VERSION ""

NS_ :

BS_:

BU_: SR_RR SR_RF SR_LR SR_LF DACU

BO_ 842 LFSideSensorObj10: 48 SR_LF
 SG_ LFSideSensorObj10_LatExtLeft : 276|7@1+ (0.05,0) [0|6.35] "m"  VCM
 SG_ LFSideSensorObj10_LatVel : 208|13@1+ (0.032,-80) [-80|182.112] "m_per_s"  VCM
 SG_ LFSideSensorObj10_LatPosVar : 88|8@1+ (0.1,0) [0|25.5] "NotApplicable"  VCM
 SG_ LFSideSensorObj10_LongAccVar : 72|8@1+ (0.1,0) [0|25.5] "NotApplicable"  VCM
 SG_ LFSideSensorObj10_LongPos : 234|13@1+ (0.05,-180) [-180|229.55] "m"  VCM
 SG_ LFSideSensorObj10_ObstacleConf : 300|7@1+ (0.01,0) [0|1.27] "NotApplicable"  VCM
 SG_ LFSideSensorObj10_LatExtRtVar : 96|8@1+ (0.1,0) [0|25.5] "NotApplicable"  VCM
 SG_ LFSideSensorObj10_Prioritisation : 290|2@1+ (1,0) [0|0] ""  VCM
 SG_ LFSideSensorObj10_HeadingVar : 120|8@1+ (0.001,0) [0|0.255] "NotApplicable"  VCM
 SG_ LFSideSensorObj10_ExistConf : 283|7@1+ (0.01,0) [0|1.27] "NotApplicable"  VCM
 SG_ LFSideSensorObj10_Counter : 16|8@1+ (1,0) [0|255] "Count"  VCM
 SG_ LFSideSensorObj10_ObjDynClass : 166|2@1+ (1,0) [0|0] ""  VCM
 SG_ LFSideSensorObj10_LatAcc : 267|9@1+ (0.08,-20) [-20|20.88] "m_per_s_squared"  VCM
 SG_ LFSideSensorObj10_TrackStatus : 192|3@1+ (1,0) [0|0] ""  VCM
 SG_ LFSideSensorObj10_CoastIndex : 155|5@1+ (1,0) [0|31] "NotApplicable"  VCM
 SG_ LFSideSensorObj10_LongVelVar : 40|8@1+ (0.01,0) [0|2.55] "NotApplicable"  VCM
 SG_ LFSideSensorObj10_LongExtFrVar : 56|8@1+ (0.1,0) [0|25.5] "NotApplicable"  VCM
 SG_ LFSideSensorObj10_LongExtFront : 247|10@1+ (0.05,0) [0|51.15] "m"  VCM
 SG_ LFSideSensorObj10_LatExtRight : 185|7@1+ (0.05,-5) [-5|1.35] "m"  VCM
 SG_ LFSideSensorObj10_MOISPrio : 307|1@1+ (1,0) [0|0] ""  VCM
 SG_ LFSideSensorObj10_LongAcc : 176|9@1+ (0.08,-20) [-20|20.88] "m_per_s_squared"  VCM
 SG_ LFSideSensorObj10_LongVel : 195|13@1+ (0.032,-80) [-80|182.112] "m_per_s"  VCM
 SG_ LFSideSensorObj10_LongExtBack : 257|10@1+ (0.05,-50) [-50|1.15000000000001] "m"  VCM
 SG_ LFSideSensorObj10_ObjClassConf : 296|4@1+ (0.1,0) [0|1.5] "NotApplicable"  VCM
 SG_ LFSideSensorObj10_LatVelVar : 80|8@1+ (0.01,0) [0|2.55] "NotApplicable"  VCM
 SG_ LFSideSensorObj10_TimeStamp : 24|16@1+ (0.1,0) [0|6553.5] "ms"  VCM
 SG_ LFSideSensorObj10_ObjID : 160|6@1+ (1,0) [0|63] "NotApplicable"  VCM
 SG_ LFSideSensorObj10_ObjClass : 292|4@1+ (1,0) [0|0] ""  VCM
 SG_ LFSideSensorObj10_LifeTime : 128|16@1+ (0.1,0) [0|6553.5] "s"  VCM
 SG_ LFSideSensorObj10_LongPosVar : 48|8@1+ (0.01,0) [0|2.55] "NotApplicable"  VCM
 SG_ LFSideSensorObj10_LongExtBkVar : 64|8@1+ (0.1,0) [0|25.5] "NotApplicable"  VCM
 SG_ LFSideSensorObj10_LatExtLeftVar : 104|8@1+ (0.1,0) [0|25.5] "NotApplicable"  VCM
 SG_ LFSideSensorObj10_Heading : 144|11@1+ (0.005818,-4.71) [-4.71|7.199446] "rad"  VCM
 SG_ LFSideSensorObj10_CRC : 0|16@1+ (1,0) [0|65535] "NotApplicable"  VCM
 SG_ LFSideSensorObj10_LatAccVar : 112|8@1+ (0.1,0) [0|25.5] "NotApplicable"  VCM
 SG_ LFSideSensorObj10_Height : 168|8@1+ (0.02,0) [0|5.1] "m"  VCM
 SG_ LFSideSensorObj10_LatPos : 221|13@1+ (0.05,-180) [-180|229.55] "m"  VCM

BO_ 841 LFSideSensorObj09: 48 SR_LF
 SG_ LFSideSensorObj09_Prioritisation : 290|2@1+ (1,0) [0|0] ""  VCM
 SG_ LFSideSensorObj09_TimeStamp : 24|16@1+ (0.1,0) [0|6553.5] "ms"  VCM
 SG_ LFSideSensorObj09_CoastIndex : 155|5@1+ (1,0) [0|31] "NotApplicable"  VCM
 SG_ LFSideSensorObj09_MOISPrio : 307|1@1+ (1,0) [0|0] ""  VCM
 SG_ LFSideSensorObj09_ExistConf : 283|7@1+ (0.01,0) [0|1.27] "NotApplicable"  VCM
 SG_ LFSideSensorObj09_Counter : 16|8@1+ (1,0) [0|255] "Count"  VCM
 SG_ LFSideSensorObj09_TrackStatus : 192|3@1+ (1,0) [0|0] ""  VCM
 SG_ LFSideSensorObj09_LongExtFront : 247|10@1+ (0.05,0) [0|51.15] "m"  VCM
 SG_ LFSideSensorObj09_LatPos : 221|13@1+ (0.05,-180) [-180|229.55] "m"  VCM
 SG_ LFSideSensorObj09_LongExtFrVar : 56|8@1+ (0.1,0) [0|25.5] "NotApplicable"  VCM
 SG_ LFSideSensorObj09_CRC : 0|16@1+ (1,0) [0|65535] "NotApplicable"  VCM
 SG_ LFSideSensorObj09_LongVelVar : 40|8@1+ (0.01,0) [0|2.55] "NotApplicable"  VCM
 SG_ LFSideSensorObj09_LongPosVar : 48|8@1+ (0.01,0) [0|2.55] "NotApplicable"  VCM
 SG_ LFSideSensorObj09_LongExtBkVar : 64|8@1+ (0.1,0) [0|25.5] "NotApplicable"  VCM
 SG_ LFSideSensorObj09_LongPos : 234|13@1+ (0.05,-180) [-180|229.55] "m"  VCM
 SG_ LFSideSensorObj09_LatVelVar : 80|8@1+ (0.01,0) [0|2.55] "NotApplicable"  VCM
 SG_ LFSideSensorObj09_LatExtRtVar : 96|8@1+ (0.1,0) [0|25.5] "NotApplicable"  VCM
 SG_ LFSideSensorObj09_ObjClassConf : 296|4@1+ (0.1,0) [0|1.5] "NotApplicable"  VCM
 SG_ LFSideSensorObj09_Height : 168|8@1+ (0.02,0) [0|5.1] "m"  VCM
 SG_ LFSideSensorObj09_LatVel : 208|13@1+ (0.032,-80) [-80|182.112] "m_per_s"  VCM
 SG_ LFSideSensorObj09_ObjDynClass : 166|2@1+ (1,0) [0|0] ""  VCM
 SG_ LFSideSensorObj09_LongExtBack : 257|10@1+ (0.05,-50) [-50|1.15000000000001] "m"  VCM
 SG_ LFSideSensorObj09_LatExtLeftVar : 104|8@1+ (0.1,0) [0|25.5] "NotApplicable"  VCM
 SG_ LFSideSensorObj09_HeadingVar : 120|8@1+ (0.001,0) [0|0.255] "NotApplicable"  VCM
 SG_ LFSideSensorObj09_LatExtLeft : 276|7@1+ (0.05,0) [0|6.35] "m"  VCM
 SG_ LFSideSensorObj09_LongAccVar : 72|8@1+ (0.1,0) [0|25.5] "NotApplicable"  VCM
 SG_ LFSideSensorObj09_LifeTime : 128|16@1+ (0.1,0) [0|6553.5] "s"  VCM
 SG_ LFSideSensorObj09_LongVel : 195|13@1+ (0.032,-80) [-80|182.112] "m_per_s"  VCM
 SG_ LFSideSensorObj09_Heading : 144|11@1+ (0.005818,-4.71) [-4.71|7.199446] "rad"  VCM
 SG_ LFSideSensorObj09_LatPosVar : 88|8@1+ (0.1,0) [0|25.5] "NotApplicable"  VCM
 SG_ LFSideSensorObj09_ObjID : 160|6@1+ (1,0) [0|63] "NotApplicable"  VCM
 SG_ LFSideSensorObj09_LatAccVar : 112|8@1+ (0.1,0) [0|25.5] "NotApplicable"  VCM
 SG_ LFSideSensorObj09_LatExtRight : 185|7@1+ (0.05,-5) [-5|1.35] "m"  VCM
 SG_ LFSideSensorObj09_LongAcc : 176|9@1+ (0.08,-20) [-20|20.88] "m_per_s_squared"  VCM
 SG_ LFSideSensorObj09_LatAcc : 267|9@1+ (0.08,-20) [-20|20.88] "m_per_s_squared"  VCM
 SG_ LFSideSensorObj09_ObjClass : 292|4@1+ (1,0) [0|0] ""  VCM
 SG_ LFSideSensorObj09_ObstacleConf : 300|7@1+ (0.01,0) [0|1.27] "NotApplicable"  VCM

BO_ 840 LFSideSensorObj08: 48 SR_LF
 SG_ LFSideSensorObj08_CoastIndex : 155|5@1+ (1,0) [0|31] "NotApplicable"  VCM
 SG_ LFSideSensorObj08_LatExtLeftVar : 104|8@1+ (0.1,0) [0|25.5] "NotApplicable"  VCM
 SG_ LFSideSensorObj08_LongExtFront : 247|10@1+ (0.05,0) [0|51.15] "m"  VCM
 SG_ LFSideSensorObj08_LatExtLeft : 276|7@1+ (0.05,0) [0|6.35] "m"  VCM
 SG_ LFSideSensorObj08_LatAcc : 267|9@1+ (0.08,-20) [-20|20.88] "m_per_s_squared"  VCM
 SG_ LFSideSensorObj08_LongExtBkVar : 64|8@1+ (0.1,0) [0|25.5] "NotApplicable"  VCM
 SG_ LFSideSensorObj08_LifeTime : 128|16@1+ (0.1,0) [0|6553.5] "s"  VCM
 SG_ LFSideSensorObj08_LatPos : 221|13@1+ (0.05,-180) [-180|229.55] "m"  VCM
 SG_ LFSideSensorObj08_ObjID : 160|6@1+ (1,0) [0|63] "NotApplicable"  VCM
 SG_ LFSideSensorObj08_Prioritisation : 290|2@1+ (1,0) [0|0] ""  VCM
 SG_ LFSideSensorObj08_ExistConf : 283|7@1+ (0.01,0) [0|1.27] "NotApplicable"  VCM
 SG_ LFSideSensorObj08_LongExtFrVar : 56|8@1+ (0.1,0) [0|25.5] "NotApplicable"  VCM
 SG_ LFSideSensorObj08_MOISPrio : 307|1@1+ (1,0) [0|0] ""  VCM
 SG_ LFSideSensorObj08_LongPosVar : 48|8@1+ (0.01,0) [0|2.55] "NotApplicable"  VCM
 SG_ LFSideSensorObj08_LongVel : 195|13@1+ (0.032,-80) [-80|182.112] "m_per_s"  VCM
 SG_ LFSideSensorObj08_TrackStatus : 192|3@1+ (1,0) [0|0] ""  VCM
 SG_ LFSideSensorObj08_Counter : 16|8@1+ (1,0) [0|255] "Count"  VCM
 SG_ LFSideSensorObj08_CRC : 0|16@1+ (1,0) [0|65535] "NotApplicable"  VCM
 SG_ LFSideSensorObj08_LatExtRight : 185|7@1+ (0.05,-5) [-5|1.35] "m"  VCM
 SG_ LFSideSensorObj08_LongVelVar : 40|8@1+ (0.01,0) [0|2.55] "NotApplicable"  VCM
 SG_ LFSideSensorObj08_LongAcc : 176|9@1+ (0.08,-20) [-20|20.88] "m_per_s_squared"  VCM
 SG_ LFSideSensorObj08_Heading : 144|11@1+ (0.005818,-4.71) [-4.71|7.199446] "rad"  VCM
 SG_ LFSideSensorObj08_LongExtBack : 257|10@1+ (0.05,-50) [-50|1.15000000000001] "m"  VCM
 SG_ LFSideSensorObj08_LatExtRtVar : 96|8@1+ (0.1,0) [0|25.5] "NotApplicable"  VCM
 SG_ LFSideSensorObj08_LatVelVar : 80|8@1+ (0.01,0) [0|2.55] "NotApplicable"  VCM
 SG_ LFSideSensorObj08_HeadingVar : 120|8@1+ (0.001,0) [0|0.255] "NotApplicable"  VCM
 SG_ LFSideSensorObj08_ObjClass : 292|4@1+ (1,0) [0|0] ""  VCM
 SG_ LFSideSensorObj08_ObjClassConf : 296|4@1+ (0.1,0) [0|1.5] "NotApplicable"  VCM
 SG_ LFSideSensorObj08_LatPosVar : 88|8@1+ (0.1,0) [0|25.5] "NotApplicable"  VCM
 SG_ LFSideSensorObj08_LongPos : 234|13@1+ (0.05,-180) [-180|229.55] "m"  VCM
 SG_ LFSideSensorObj08_LatAccVar : 112|8@1+ (0.1,0) [0|25.5] "NotApplicable"  VCM
 SG_ LFSideSensorObj08_Height : 168|8@1+ (0.02,0) [0|5.1] "m"  VCM
 SG_ LFSideSensorObj08_TimeStamp : 24|16@1+ (0.1,0) [0|6553.5] "ms"  VCM
 SG_ LFSideSensorObj08_LongAccVar : 72|8@1+ (0.1,0) [0|25.5] "NotApplicable"  VCM
 SG_ LFSideSensorObj08_LatVel : 208|13@1+ (0.032,-80) [-80|182.112] "m_per_s"  VCM
 SG_ LFSideSensorObj08_ObjDynClass : 166|2@1+ (1,0) [0|0] ""  VCM
 SG_ LFSideSensorObj08_ObstacleConf : 300|7@1+ (0.01,0) [0|1.27] "NotApplicable"  VCM

BO_ 839 LFSideSensorObj07: 48 SR_LF
 SG_ LFSideSensorObj07_LatAcc : 267|9@1+ (0.08,-20) [-20|20.88] "m_per_s_squared"  VCM
 SG_ LFSideSensorObj07_LongPosVar : 48|8@1+ (0.01,0) [0|2.55] "NotApplicable"  VCM
 SG_ LFSideSensorObj07_ObjClassConf : 296|4@1+ (0.1,0) [0|1.5] "NotApplicable"  VCM
 SG_ LFSideSensorObj07_LatPosVar : 88|8@1+ (0.1,0) [0|25.5] "NotApplicable"  VCM
 SG_ LFSideSensorObj07_ExistConf : 283|7@1+ (0.01,0) [0|1.27] "NotApplicable"  VCM
 SG_ LFSideSensorObj07_LifeTime : 128|16@1+ (0.1,0) [0|6553.5] "s"  VCM
 SG_ LFSideSensorObj07_ObstacleConf : 300|7@1+ (0.01,0) [0|1.27] "NotApplicable"  VCM
 SG_ LFSideSensorObj07_MOISPrio : 307|1@1+ (1,0) [0|0] ""  VCM
 SG_ LFSideSensorObj07_ObjDynClass : 166|2@1+ (1,0) [0|0] ""  VCM
 SG_ LFSideSensorObj07_Height : 168|8@1+ (0.02,0) [0|5.1] "m"  VCM
 SG_ LFSideSensorObj07_HeadingVar : 120|8@1+ (0.001,0) [0|0.255] "NotApplicable"  VCM
 SG_ LFSideSensorObj07_Heading : 144|11@1+ (0.005818,-4.71) [-4.71|7.199446] "rad"  VCM
 SG_ LFSideSensorObj07_LatExtLeftVar : 104|8@1+ (0.1,0) [0|25.5] "NotApplicable"  VCM
 SG_ LFSideSensorObj07_LatVel : 208|13@1+ (0.032,-80) [-80|182.112] "m_per_s"  VCM
 SG_ LFSideSensorObj07_Counter : 16|8@1+ (1,0) [0|255] "Count"  VCM
 SG_ LFSideSensorObj07_TrackStatus : 192|3@1+ (1,0) [0|0] ""  VCM
 SG_ LFSideSensorObj07_LongExtBack : 257|10@1+ (0.05,-50) [-50|1.15000000000001] "m"  VCM
 SG_ LFSideSensorObj07_LatVelVar : 80|8@1+ (0.01,0) [0|2.55] "NotApplicable"  VCM
 SG_ LFSideSensorObj07_TimeStamp : 24|16@1+ (0.1,0) [0|6553.5] "ms"  VCM
 SG_ LFSideSensorObj07_LongAccVar : 72|8@1+ (0.1,0) [0|25.5] "NotApplicable"  VCM
 SG_ LFSideSensorObj07_LongVelVar : 40|8@1+ (0.01,0) [0|2.55] "NotApplicable"  VCM
 SG_ LFSideSensorObj07_LatExtLeft : 276|7@1+ (0.05,0) [0|6.35] "m"  VCM
 SG_ LFSideSensorObj07_LongPos : 234|13@1+ (0.05,-180) [-180|229.55] "m"  VCM
 SG_ LFSideSensorObj07_LongVel : 195|13@1+ (0.032,-80) [-80|182.112] "m_per_s"  VCM
 SG_ LFSideSensorObj07_LongExtFrVar : 56|8@1+ (0.1,0) [0|25.5] "NotApplicable"  VCM
 SG_ LFSideSensorObj07_LatExtRtVar : 96|8@1+ (0.1,0) [0|25.5] "NotApplicable"  VCM
 SG_ LFSideSensorObj07_LatAccVar : 112|8@1+ (0.1,0) [0|25.5] "NotApplicable"  VCM
 SG_ LFSideSensorObj07_Prioritisation : 290|2@1+ (1,0) [0|0] ""  VCM
 SG_ LFSideSensorObj07_ObjClass : 292|4@1+ (1,0) [0|0] ""  VCM
 SG_ LFSideSensorObj07_CoastIndex : 155|5@1+ (1,0) [0|31] "NotApplicable"  VCM
 SG_ LFSideSensorObj07_LatPos : 221|13@1+ (0.05,-180) [-180|229.55] "m"  VCM
 SG_ LFSideSensorObj07_LongExtBkVar : 64|8@1+ (0.1,0) [0|25.5] "NotApplicable"  VCM
 SG_ LFSideSensorObj07_ObjID : 160|6@1+ (1,0) [0|63] "NotApplicable"  VCM
 SG_ LFSideSensorObj07_LongExtFront : 247|10@1+ (0.05,0) [0|51.15] "m"  VCM
 SG_ LFSideSensorObj07_CRC : 0|16@1+ (1,0) [0|65535] "NotApplicable"  VCM
 SG_ LFSideSensorObj07_LatExtRight : 185|7@1+ (0.05,-5) [-5|1.35] "m"  VCM
 SG_ LFSideSensorObj07_LongAcc : 176|9@1+ (0.08,-20) [-20|20.88] "m_per_s_squared"  VCM

BO_ 838 LFSideSensorObj06: 48 SR_LF
 SG_ LFSideSensorObj06_MOISPrio : 307|1@1+ (1,0) [0|0] ""  VCM
 SG_ LFSideSensorObj06_ObstacleConf : 300|7@1+ (0.01,0) [0|1.27] "NotApplicable"  VCM
 SG_ LFSideSensorObj06_LongVel : 195|13@1+ (0.032,-80) [-80|182.112] "m_per_s"  VCM
 SG_ LFSideSensorObj06_LongExtFront : 247|10@1+ (0.05,0) [0|51.15] "m"  VCM
 SG_ LFSideSensorObj06_Counter : 16|8@1+ (1,0) [0|255] "Count"  VCM
 SG_ LFSideSensorObj06_LongVelVar : 40|8@1+ (0.01,0) [0|2.55] "NotApplicable"  VCM
 SG_ LFSideSensorObj06_LongPos : 234|13@1+ (0.05,-180) [-180|229.55] "m"  VCM
 SG_ LFSideSensorObj06_LongExtFrVar : 56|8@1+ (0.1,0) [0|25.5] "NotApplicable"  VCM
 SG_ LFSideSensorObj06_LatExtLeft : 276|7@1+ (0.05,0) [0|6.35] "m"  VCM
 SG_ LFSideSensorObj06_Prioritisation : 290|2@1+ (1,0) [0|0] ""  VCM
 SG_ LFSideSensorObj06_CoastIndex : 155|5@1+ (1,0) [0|31] "NotApplicable"  VCM
 SG_ LFSideSensorObj06_HeadingVar : 120|8@1+ (0.001,0) [0|0.255] "NotApplicable"  VCM
 SG_ LFSideSensorObj06_LatAcc : 267|9@1+ (0.08,-20) [-20|20.88] "m_per_s_squared"  VCM
 SG_ LFSideSensorObj06_LongExtBkVar : 64|8@1+ (0.1,0) [0|25.5] "NotApplicable"  VCM
 SG_ LFSideSensorObj06_LongAccVar : 72|8@1+ (0.1,0) [0|25.5] "NotApplicable"  VCM
 SG_ LFSideSensorObj06_LongExtBack : 257|10@1+ (0.05,-50) [-50|1.15000000000001] "m"  VCM
 SG_ LFSideSensorObj06_Heading : 144|11@1+ (0.005818,-4.71) [-4.71|7.199446] "rad"  VCM
 SG_ LFSideSensorObj06_ExistConf : 283|7@1+ (0.01,0) [0|1.27] "NotApplicable"  VCM
 SG_ LFSideSensorObj06_LatVelVar : 80|8@1+ (0.01,0) [0|2.55] "NotApplicable"  VCM
 SG_ LFSideSensorObj06_LifeTime : 128|16@1+ (0.1,0) [0|6553.5] "s"  VCM
 SG_ LFSideSensorObj06_LatVel : 208|13@1+ (0.032,-80) [-80|182.112] "m_per_s"  VCM
 SG_ LFSideSensorObj06_TimeStamp : 24|16@1+ (0.1,0) [0|6553.5] "ms"  VCM
 SG_ LFSideSensorObj06_ObjDynClass : 166|2@1+ (1,0) [0|0] ""  VCM
 SG_ LFSideSensorObj06_ObjClass : 292|4@1+ (1,0) [0|0] ""  VCM
 SG_ LFSideSensorObj06_TrackStatus : 192|3@1+ (1,0) [0|0] ""  VCM
 SG_ LFSideSensorObj06_LatExtLeftVar : 104|8@1+ (0.1,0) [0|25.5] "NotApplicable"  VCM
 SG_ LFSideSensorObj06_ObjClassConf : 296|4@1+ (0.1,0) [0|1.5] "NotApplicable"  VCM
 SG_ LFSideSensorObj06_LongPosVar : 48|8@1+ (0.01,0) [0|2.55] "NotApplicable"  VCM
 SG_ LFSideSensorObj06_LatExtRtVar : 96|8@1+ (0.1,0) [0|25.5] "NotApplicable"  VCM
 SG_ LFSideSensorObj06_CRC : 0|16@1+ (1,0) [0|65535] "NotApplicable"  VCM
 SG_ LFSideSensorObj06_LatPosVar : 88|8@1+ (0.1,0) [0|25.5] "NotApplicable"  VCM
 SG_ LFSideSensorObj06_LatPos : 221|13@1+ (0.05,-180) [-180|229.55] "m"  VCM
 SG_ LFSideSensorObj06_ObjID : 160|6@1+ (1,0) [0|63] "NotApplicable"  VCM
 SG_ LFSideSensorObj06_LongAcc : 176|9@1+ (0.08,-20) [-20|20.88] "m_per_s_squared"  VCM
 SG_ LFSideSensorObj06_LatExtRight : 185|7@1+ (0.05,-5) [-5|1.35] "m"  VCM
 SG_ LFSideSensorObj06_LatAccVar : 112|8@1+ (0.1,0) [0|25.5] "NotApplicable"  VCM
 SG_ LFSideSensorObj06_Height : 168|8@1+ (0.02,0) [0|5.1] "m"  VCM

BO_ 837 LFSideSensorObj05: 48 SR_LF
 SG_ LFSideSensorObj05_Height : 168|8@1+ (0.02,0) [0|5.1] "m"  VCM
 SG_ LFSideSensorObj05_LatPosVar : 88|8@1+ (0.1,0) [0|25.5] "NotApplicable"  VCM
 SG_ LFSideSensorObj05_MOISPrio : 307|1@1+ (1,0) [0|0] ""  VCM
 SG_ LFSideSensorObj05_LatExtLeftVar : 104|8@1+ (0.1,0) [0|25.5] "NotApplicable"  VCM
 SG_ LFSideSensorObj05_LongPosVar : 48|8@1+ (0.01,0) [0|2.55] "NotApplicable"  VCM
 SG_ LFSideSensorObj05_LatAccVar : 112|8@1+ (0.1,0) [0|25.5] "NotApplicable"  VCM
 SG_ LFSideSensorObj05_LongExtBkVar : 64|8@1+ (0.1,0) [0|25.5] "NotApplicable"  VCM
 SG_ LFSideSensorObj05_LongAcc : 176|9@1+ (0.08,-20) [-20|20.88] "m_per_s_squared"  VCM
 SG_ LFSideSensorObj05_LatExtRight : 185|7@1+ (0.05,-5) [-5|1.35] "m"  VCM
 SG_ LFSideSensorObj05_LatExtLeft : 276|7@1+ (0.05,0) [0|6.35] "m"  VCM
 SG_ LFSideSensorObj05_LongExtFront : 247|10@1+ (0.05,0) [0|51.15] "m"  VCM
 SG_ LFSideSensorObj05_ObjClassConf : 296|4@1+ (0.1,0) [0|1.5] "NotApplicable"  VCM
 SG_ LFSideSensorObj05_ObjID : 160|6@1+ (1,0) [0|63] "NotApplicable"  VCM
 SG_ LFSideSensorObj05_LatPos : 221|13@1+ (0.05,-180) [-180|229.55] "m"  VCM
 SG_ LFSideSensorObj05_LongExtBack : 257|10@1+ (0.05,-50) [-50|1.15000000000001] "m"  VCM
 SG_ LFSideSensorObj05_Heading : 144|11@1+ (0.005818,-4.71) [-4.71|7.199446] "rad"  VCM
 SG_ LFSideSensorObj05_CRC : 0|16@1+ (1,0) [0|65535] "NotApplicable"  VCM
 SG_ LFSideSensorObj05_LongAccVar : 72|8@1+ (0.1,0) [0|25.5] "NotApplicable"  VCM
 SG_ LFSideSensorObj05_LatExtRtVar : 96|8@1+ (0.1,0) [0|25.5] "NotApplicable"  VCM
 SG_ LFSideSensorObj05_ExistConf : 283|7@1+ (0.01,0) [0|1.27] "NotApplicable"  VCM
 SG_ LFSideSensorObj05_LatAcc : 267|9@1+ (0.08,-20) [-20|20.88] "m_per_s_squared"  VCM
 SG_ LFSideSensorObj05_CoastIndex : 155|5@1+ (1,0) [0|31] "NotApplicable"  VCM
 SG_ LFSideSensorObj05_LongPos : 234|13@1+ (0.05,-180) [-180|229.55] "m"  VCM
 SG_ LFSideSensorObj05_LongVel : 195|13@1+ (0.032,-80) [-80|182.112] "m_per_s"  VCM
 SG_ LFSideSensorObj05_LongVelVar : 40|8@1+ (0.01,0) [0|2.55] "NotApplicable"  VCM
 SG_ LFSideSensorObj05_TrackStatus : 192|3@1+ (1,0) [0|0] ""  VCM
 SG_ LFSideSensorObj05_LifeTime : 128|16@1+ (0.1,0) [0|6553.5] "s"  VCM
 SG_ LFSideSensorObj05_ObjClass : 292|4@1+ (1,0) [0|0] ""  VCM
 SG_ LFSideSensorObj05_HeadingVar : 120|8@1+ (0.001,0) [0|0.255] "NotApplicable"  VCM
 SG_ LFSideSensorObj05_Prioritisation : 290|2@1+ (1,0) [0|0] ""  VCM
 SG_ LFSideSensorObj05_Counter : 16|8@1+ (1,0) [0|255] "Count"  VCM
 SG_ LFSideSensorObj05_LatVel : 208|13@1+ (0.032,-80) [-80|182.112] "m_per_s"  VCM
 SG_ LFSideSensorObj05_LongExtFrVar : 56|8@1+ (0.1,0) [0|25.5] "NotApplicable"  VCM
 SG_ LFSideSensorObj05_ObjDynClass : 166|2@1+ (1,0) [0|0] ""  VCM
 SG_ LFSideSensorObj05_TimeStamp : 24|16@1+ (0.1,0) [0|6553.5] "ms"  VCM
 SG_ LFSideSensorObj05_ObstacleConf : 300|7@1+ (0.01,0) [0|1.27] "NotApplicable"  VCM
 SG_ LFSideSensorObj05_LatVelVar : 80|8@1+ (0.01,0) [0|2.55] "NotApplicable"  VCM

BO_ 836 LFSideSensorObj04: 48 SR_LF
 SG_ LFSideSensorObj04_TrackStatus : 192|3@1+ (1,0) [0|0] ""  VCM
 SG_ LFSideSensorObj04_LongAcc : 176|9@1+ (0.08,-20) [-20|20.88] "m_per_s_squared"  VCM
 SG_ LFSideSensorObj04_LatExtRight : 185|7@1+ (0.05,-5) [-5|1.35] "m"  VCM
 SG_ LFSideSensorObj04_Heading : 144|11@1+ (0.005818,-4.71) [-4.71|7.199446] "rad"  VCM
 SG_ LFSideSensorObj04_ObjDynClass : 166|2@1+ (1,0) [0|0] ""  VCM
 SG_ LFSideSensorObj04_CRC : 0|16@1+ (1,0) [0|65535] "NotApplicable"  VCM
 SG_ LFSideSensorObj04_ExistConf : 283|7@1+ (0.01,0) [0|1.27] "NotApplicable"  VCM
 SG_ LFSideSensorObj04_LongAccVar : 72|8@1+ (0.1,0) [0|25.5] "NotApplicable"  VCM
 SG_ LFSideSensorObj04_TimeStamp : 24|16@1+ (0.1,0) [0|6553.5] "ms"  VCM
 SG_ LFSideSensorObj04_Counter : 16|8@1+ (1,0) [0|255] "Count"  VCM
 SG_ LFSideSensorObj04_LatPos : 221|13@1+ (0.05,-180) [-180|229.55] "m"  VCM
 SG_ LFSideSensorObj04_CoastIndex : 155|5@1+ (1,0) [0|31] "NotApplicable"  VCM
 SG_ LFSideSensorObj04_LongPos : 234|13@1+ (0.05,-180) [-180|229.55] "m"  VCM
 SG_ LFSideSensorObj04_LongExtBkVar : 64|8@1+ (0.1,0) [0|25.5] "NotApplicable"  VCM
 SG_ LFSideSensorObj04_LatVelVar : 80|8@1+ (0.01,0) [0|2.55] "NotApplicable"  VCM
 SG_ LFSideSensorObj04_LatAccVar : 112|8@1+ (0.1,0) [0|25.5] "NotApplicable"  VCM
 SG_ LFSideSensorObj04_LifeTime : 128|16@1+ (0.1,0) [0|6553.5] "s"  VCM
 SG_ LFSideSensorObj04_LongExtFront : 247|10@1+ (0.05,0) [0|51.15] "m"  VCM
 SG_ LFSideSensorObj04_Prioritisation : 290|2@1+ (1,0) [0|0] ""  VCM
 SG_ LFSideSensorObj04_ObjID : 160|6@1+ (1,0) [0|63] "NotApplicable"  VCM
 SG_ LFSideSensorObj04_LongPosVar : 48|8@1+ (0.01,0) [0|2.55] "NotApplicable"  VCM
 SG_ LFSideSensorObj04_LongVel : 195|13@1+ (0.032,-80) [-80|182.112] "m_per_s"  VCM
 SG_ LFSideSensorObj04_ObjClassConf : 296|4@1+ (0.1,0) [0|1.5] "NotApplicable"  VCM
 SG_ LFSideSensorObj04_LatExtLeft : 276|7@1+ (0.05,0) [0|6.35] "m"  VCM
 SG_ LFSideSensorObj04_LatVel : 208|13@1+ (0.032,-80) [-80|182.112] "m_per_s"  VCM
 SG_ LFSideSensorObj04_LongExtBack : 257|10@1+ (0.05,-50) [-50|1.15000000000001] "m"  VCM
 SG_ LFSideSensorObj04_LatAcc : 267|9@1+ (0.08,-20) [-20|20.88] "m_per_s_squared"  VCM
 SG_ LFSideSensorObj04_MOISPrio : 307|1@1+ (1,0) [0|0] ""  VCM
 SG_ LFSideSensorObj04_ObstacleConf : 300|7@1+ (0.01,0) [0|1.27] "NotApplicable"  VCM
 SG_ LFSideSensorObj04_LatPosVar : 88|8@1+ (0.1,0) [0|25.5] "NotApplicable"  VCM
 SG_ LFSideSensorObj04_HeadingVar : 120|8@1+ (0.001,0) [0|0.255] "NotApplicable"  VCM
 SG_ LFSideSensorObj04_LongExtFrVar : 56|8@1+ (0.1,0) [0|25.5] "NotApplicable"  VCM
 SG_ LFSideSensorObj04_LatExtLeftVar : 104|8@1+ (0.1,0) [0|25.5] "NotApplicable"  VCM
 SG_ LFSideSensorObj04_Height : 168|8@1+ (0.02,0) [0|5.1] "m"  VCM
 SG_ LFSideSensorObj04_LongVelVar : 40|8@1+ (0.01,0) [0|2.55] "NotApplicable"  VCM
 SG_ LFSideSensorObj04_ObjClass : 292|4@1+ (1,0) [0|0] ""  VCM
 SG_ LFSideSensorObj04_LatExtRtVar : 96|8@1+ (0.1,0) [0|25.5] "NotApplicable"  VCM

BO_ 835 LFSideSensorObj03: 48 SR_LF
 SG_ LFSideSensorObj03_ObjDynClass : 166|2@1+ (1,0) [0|0] ""  VCM
 SG_ LFSideSensorObj03_TrackStatus : 192|3@1+ (1,0) [0|0] ""  VCM
 SG_ LFSideSensorObj03_Counter : 16|8@1+ (1,0) [0|255] "Count"  VCM
 SG_ LFSideSensorObj03_LatVel : 208|13@1+ (0.032,-80) [-80|182.112] "m_per_s"  VCM
 SG_ LFSideSensorObj03_LatVelVar : 80|8@1+ (0.01,0) [0|2.55] "NotApplicable"  VCM
 SG_ LFSideSensorObj03_ExistConf : 283|7@1+ (0.01,0) [0|1.27] "NotApplicable"  VCM
 SG_ LFSideSensorObj03_ObjClass : 292|4@1+ (1,0) [0|0] ""  VCM
 SG_ LFSideSensorObj03_ObstacleConf : 300|7@1+ (0.01,0) [0|1.27] "NotApplicable"  VCM
 SG_ LFSideSensorObj03_LongAcc : 176|9@1+ (0.08,-20) [-20|20.88] "m_per_s_squared"  VCM
 SG_ LFSideSensorObj03_LatAccVar : 112|8@1+ (0.1,0) [0|25.5] "NotApplicable"  VCM
 SG_ LFSideSensorObj03_CRC : 0|16@1+ (1,0) [0|65535] "NotApplicable"  VCM
 SG_ LFSideSensorObj03_MOISPrio : 307|1@1+ (1,0) [0|0] ""  VCM
 SG_ LFSideSensorObj03_ObjClassConf : 296|4@1+ (0.1,0) [0|1.5] "NotApplicable"  VCM
 SG_ LFSideSensorObj03_LongPos : 234|13@1+ (0.05,-180) [-180|229.55] "m"  VCM
 SG_ LFSideSensorObj03_LatPosVar : 88|8@1+ (0.1,0) [0|25.5] "NotApplicable"  VCM
 SG_ LFSideSensorObj03_ObjID : 160|6@1+ (1,0) [0|63] "NotApplicable"  VCM
 SG_ LFSideSensorObj03_LongVel : 195|13@1+ (0.032,-80) [-80|182.112] "m_per_s"  VCM
 SG_ LFSideSensorObj03_Height : 168|8@1+ (0.02,0) [0|5.1] "m"  VCM
 SG_ LFSideSensorObj03_LatExtLeftVar : 104|8@1+ (0.1,0) [0|25.5] "NotApplicable"  VCM
 SG_ LFSideSensorObj03_Prioritisation : 290|2@1+ (1,0) [0|0] ""  VCM
 SG_ LFSideSensorObj03_HeadingVar : 120|8@1+ (0.001,0) [0|0.255] "NotApplicable"  VCM
 SG_ LFSideSensorObj03_LifeTime : 128|16@1+ (0.1,0) [0|6553.5] "s"  VCM
 SG_ LFSideSensorObj03_LatExtLeft : 276|7@1+ (0.05,0) [0|6.35] "m"  VCM
 SG_ LFSideSensorObj03_Heading : 144|11@1+ (0.005818,-4.71) [-4.71|7.199446] "rad"  VCM
 SG_ LFSideSensorObj03_LongPosVar : 48|8@1+ (0.01,0) [0|2.55] "NotApplicable"  VCM
 SG_ LFSideSensorObj03_LongExtFrVar : 56|8@1+ (0.1,0) [0|25.5] "NotApplicable"  VCM
 SG_ LFSideSensorObj03_LongExtBack : 257|10@1+ (0.05,-50) [-50|1.15000000000001] "m"  VCM
 SG_ LFSideSensorObj03_LatExtRtVar : 96|8@1+ (0.1,0) [0|25.5] "NotApplicable"  VCM
 SG_ LFSideSensorObj03_TimeStamp : 24|16@1+ (0.1,0) [0|6553.5] "ms"  VCM
 SG_ LFSideSensorObj03_LongExtBkVar : 64|8@1+ (0.1,0) [0|25.5] "NotApplicable"  VCM
 SG_ LFSideSensorObj03_LatAcc : 267|9@1+ (0.08,-20) [-20|20.88] "m_per_s_squared"  VCM
 SG_ LFSideSensorObj03_LatPos : 221|13@1+ (0.05,-180) [-180|229.55] "m"  VCM
 SG_ LFSideSensorObj03_LongVelVar : 40|8@1+ (0.01,0) [0|2.55] "NotApplicable"  VCM
 SG_ LFSideSensorObj03_CoastIndex : 155|5@1+ (1,0) [0|31] "NotApplicable"  VCM
 SG_ LFSideSensorObj03_LatExtRight : 185|7@1+ (0.05,-5) [-5|1.35] "m"  VCM
 SG_ LFSideSensorObj03_LongExtFront : 247|10@1+ (0.05,0) [0|51.15] "m"  VCM
 SG_ LFSideSensorObj03_LongAccVar : 72|8@1+ (0.1,0) [0|25.5] "NotApplicable"  VCM

BO_ 834 LFSideSensorObj02: 48 SR_LF
 SG_ LFSideSensorObj02_LatVelVar : 80|8@1+ (0.01,0) [0|2.55] "NotApplicable"  VCM
 SG_ LFSideSensorObj02_LatExtLeftVar : 104|8@1+ (0.1,0) [0|25.5] "NotApplicable"  VCM
 SG_ LFSideSensorObj02_ObstacleConf : 300|7@1+ (0.01,0) [0|1.27] "NotApplicable"  VCM
 SG_ LFSideSensorObj02_LatExtRtVar : 96|8@1+ (0.1,0) [0|25.5] "NotApplicable"  VCM
 SG_ LFSideSensorObj02_Height : 168|8@1+ (0.02,0) [0|5.1] "m"  VCM
 SG_ LFSideSensorObj02_LongVelVar : 40|8@1+ (0.01,0) [0|2.55] "NotApplicable"  VCM
 SG_ LFSideSensorObj02_Prioritisation : 290|2@1+ (1,0) [0|0] ""  VCM
 SG_ LFSideSensorObj02_ExistConf : 283|7@1+ (0.01,0) [0|1.27] "NotApplicable"  VCM
 SG_ LFSideSensorObj02_CRC : 0|16@1+ (1,0) [0|65535] "NotApplicable"  VCM
 SG_ LFSideSensorObj02_LongVel : 195|13@1+ (0.032,-80) [-80|182.112] "m_per_s"  VCM
 SG_ LFSideSensorObj02_LongAcc : 176|9@1+ (0.08,-20) [-20|20.88] "m_per_s_squared"  VCM
 SG_ LFSideSensorObj02_LifeTime : 128|16@1+ (0.1,0) [0|6553.5] "s"  VCM
 SG_ LFSideSensorObj02_LatAcc : 267|9@1+ (0.08,-20) [-20|20.88] "m_per_s_squared"  VCM
 SG_ LFSideSensorObj02_ObjClassConf : 296|4@1+ (0.1,0) [0|1.5] "NotApplicable"  VCM
 SG_ LFSideSensorObj02_LatPos : 221|13@1+ (0.05,-180) [-180|229.55] "m"  VCM
 SG_ LFSideSensorObj02_ObjID : 160|6@1+ (1,0) [0|63] "NotApplicable"  VCM
 SG_ LFSideSensorObj02_LongPos : 234|13@1+ (0.05,-180) [-180|229.55] "m"  VCM
 SG_ LFSideSensorObj02_LatVel : 208|13@1+ (0.032,-80) [-80|182.112] "m_per_s"  VCM
 SG_ LFSideSensorObj02_Heading : 144|11@1+ (0.005818,-4.71) [-4.71|7.199446] "rad"  VCM
 SG_ LFSideSensorObj02_LongExtFront : 247|10@1+ (0.05,0) [0|51.15] "m"  VCM
 SG_ LFSideSensorObj02_MOISPrio : 307|1@1+ (1,0) [0|0] ""  VCM
 SG_ LFSideSensorObj02_LatAccVar : 112|8@1+ (0.1,0) [0|25.5] "NotApplicable"  VCM
 SG_ LFSideSensorObj02_TimeStamp : 24|16@1+ (0.1,0) [0|6553.5] "ms"  VCM
 SG_ LFSideSensorObj02_LongExtFrVar : 56|8@1+ (0.1,0) [0|25.5] "NotApplicable"  VCM
 SG_ LFSideSensorObj02_LatExtLeft : 276|7@1+ (0.05,0) [0|6.35] "m"  VCM
 SG_ LFSideSensorObj02_LongExtBack : 257|10@1+ (0.05,-50) [-50|1.15000000000001] "m"  VCM
 SG_ LFSideSensorObj02_ObjDynClass : 166|2@1+ (1,0) [0|0] ""  VCM
 SG_ LFSideSensorObj02_HeadingVar : 120|8@1+ (0.001,0) [0|0.255] "NotApplicable"  VCM
 SG_ LFSideSensorObj02_LongPosVar : 48|8@1+ (0.01,0) [0|2.55] "NotApplicable"  VCM
 SG_ LFSideSensorObj02_LatPosVar : 88|8@1+ (0.1,0) [0|25.5] "NotApplicable"  VCM
 SG_ LFSideSensorObj02_LatExtRight : 185|7@1+ (0.05,-5) [-5|1.35] "m"  VCM
 SG_ LFSideSensorObj02_LongAccVar : 72|8@1+ (0.1,0) [0|25.5] "NotApplicable"  VCM
 SG_ LFSideSensorObj02_CoastIndex : 155|5@1+ (1,0) [0|31] "NotApplicable"  VCM
 SG_ LFSideSensorObj02_Counter : 16|8@1+ (1,0) [0|255] "Count"  VCM
 SG_ LFSideSensorObj02_ObjClass : 292|4@1+ (1,0) [0|0] ""  VCM
 SG_ LFSideSensorObj02_LongExtBkVar : 64|8@1+ (0.1,0) [0|25.5] "NotApplicable"  VCM
 SG_ LFSideSensorObj02_TrackStatus : 192|3@1+ (1,0) [0|0] ""  VCM

BO_ 833 LFSideSensorObj01: 48 SR_LF
 SG_ LFSideSensorObj01_LatAcc : 267|9@1+ (0.08,-20) [-20|20.88] "m_per_s_squared"  VCM
 SG_ LFSideSensorObj01_ExistConf : 283|7@1+ (0.01,0) [0|1.27] "NotApplicable"  VCM
 SG_ LFSideSensorObj01_ObjDynClass : 166|2@1+ (1,0) [0|0] ""  VCM
 SG_ LFSideSensorObj01_LongAcc : 176|9@1+ (0.08,-20) [-20|20.88] "m_per_s_squared"  VCM
 SG_ LFSideSensorObj01_LatExtRtVar : 96|8@1+ (0.1,0) [0|25.5] "NotApplicable"  VCM
 SG_ LFSideSensorObj01_CRC : 0|16@1+ (1,0) [0|65535] "NotApplicable"  VCM
 SG_ LFSideSensorObj01_LatVel : 208|13@1+ (0.032,-80) [-80|182.112] "m_per_s"  VCM
 SG_ LFSideSensorObj01_LongExtBack : 257|10@1+ (0.05,-50) [-50|1.15000000000001] "m"  VCM
 SG_ LFSideSensorObj01_LongAccVar : 72|8@1+ (0.1,0) [0|25.5] "NotApplicable"  VCM
 SG_ LFSideSensorObj01_Counter : 16|8@1+ (1,0) [0|255] "Count"  VCM
 SG_ LFSideSensorObj01_Heading : 144|11@1+ (0.005818,-4.71) [-4.71|7.199446] "rad"  VCM
 SG_ LFSideSensorObj01_ObjID : 160|6@1+ (1,0) [0|63] "NotApplicable"  VCM
 SG_ LFSideSensorObj01_LatPosVar : 88|8@1+ (0.1,0) [0|25.5] "NotApplicable"  VCM
 SG_ LFSideSensorObj01_LongVel : 195|13@1+ (0.032,-80) [-80|182.112] "m_per_s"  VCM
 SG_ LFSideSensorObj01_ObjClass : 292|4@1+ (1,0) [0|0] ""  VCM
 SG_ LFSideSensorObj01_MOISPrio : 307|1@1+ (1,0) [0|0] ""  VCM
 SG_ LFSideSensorObj01_LongPos : 234|13@1+ (0.05,-180) [-180|229.55] "m"  VCM
 SG_ LFSideSensorObj01_LatExtRight : 185|7@1+ (0.05,-5) [-5|1.35] "m"  VCM
 SG_ LFSideSensorObj01_LatExtLeftVar : 104|8@1+ (0.1,0) [0|25.5] "NotApplicable"  VCM
 SG_ LFSideSensorObj01_LongExtFrVar : 56|8@1+ (0.1,0) [0|25.5] "NotApplicable"  VCM
 SG_ LFSideSensorObj01_LatExtLeft : 276|7@1+ (0.05,0) [0|6.35] "m"  VCM
 SG_ LFSideSensorObj01_Prioritisation : 290|2@1+ (1,0) [0|0] ""  VCM
 SG_ LFSideSensorObj01_Height : 168|8@1+ (0.02,0) [0|5.1] "m"  VCM
 SG_ LFSideSensorObj01_HeadingVar : 120|8@1+ (0.001,0) [0|0.255] "NotApplicable"  VCM
 SG_ LFSideSensorObj01_CoastIndex : 155|5@1+ (1,0) [0|31] "NotApplicable"  VCM
 SG_ LFSideSensorObj01_ObjClassConf : 296|4@1+ (0.1,0) [0|1.5] "NotApplicable"  VCM
 SG_ LFSideSensorObj01_LongExtBkVar : 64|8@1+ (0.1,0) [0|25.5] "NotApplicable"  VCM
 SG_ LFSideSensorObj01_LifeTime : 128|16@1+ (0.1,0) [0|6553.5] "s"  VCM
 SG_ LFSideSensorObj01_LongPosVar : 48|8@1+ (0.01,0) [0|2.55] "NotApplicable"  VCM
 SG_ LFSideSensorObj01_LatPos : 221|13@1+ (0.05,-180) [-180|229.55] "m"  VCM
 SG_ LFSideSensorObj01_LongVelVar : 40|8@1+ (0.01,0) [0|2.55] "NotApplicable"  VCM
 SG_ LFSideSensorObj01_LongExtFront : 247|10@1+ (0.05,0) [0|51.15] "m"  VCM
 SG_ LFSideSensorObj01_ObstacleConf : 300|7@1+ (0.01,0) [0|1.27] "NotApplicable"  VCM
 SG_ LFSideSensorObj01_TrackStatus : 192|3@1+ (1,0) [0|0] ""  VCM
 SG_ LFSideSensorObj01_TimeStamp : 24|16@1+ (0.1,0) [0|6553.5] "ms"  VCM
 SG_ LFSideSensorObj01_LatAccVar : 112|8@1+ (0.1,0) [0|25.5] "NotApplicable"  VCM
 SG_ LFSideSensorObj01_LatVelVar : 80|8@1+ (0.01,0) [0|2.55] "NotApplicable"  VCM

BO_ 832 LFSideSensorObj00: 48 SR_LF
 SG_ LFSideSensorObj00_LongAccVar : 72|8@1+ (0.1,0) [0|25.5] "NotApplicable"  VCM
 SG_ LFSideSensorObj00_LongVelVar : 40|8@1+ (0.01,0) [0|2.55] "NotApplicable"  VCM
 SG_ LFSideSensorObj00_Prioritisation : 290|2@1+ (1,0) [0|0] ""  VCM
 SG_ LFSideSensorObj00_LatAcc : 267|9@1+ (0.08,-20) [-20|20.88] "m_per_s_squared"  VCM
 SG_ LFSideSensorObj00_MOISPrio : 307|1@1+ (1,0) [0|0] ""  VCM
 SG_ LFSideSensorObj00_Heading : 144|11@1+ (0.005818,-4.71) [-4.71|7.199446] "rad"  VCM
 SG_ LFSideSensorObj00_LongAcc : 176|9@1+ (0.08,-20) [-20|20.88] "m_per_s_squared"  VCM
 SG_ LFSideSensorObj00_LongPos : 234|13@1+ (0.05,-180) [-180|229.55] "m"  VCM
 SG_ LFSideSensorObj00_ObjID : 160|6@1+ (1,0) [0|63] "NotApplicable"  VCM
 SG_ LFSideSensorObj00_LongPosVar : 48|8@1+ (0.01,0) [0|2.55] "NotApplicable"  VCM
 SG_ LFSideSensorObj00_HeadingVar : 120|8@1+ (0.001,0) [0|0.255] "NotApplicable"  VCM
 SG_ LFSideSensorObj00_LongExtFrVar : 56|8@1+ (0.1,0) [0|25.5] "NotApplicable"  VCM
 SG_ LFSideSensorObj00_LatVelVar : 80|8@1+ (0.01,0) [0|2.55] "NotApplicable"  VCM
 SG_ LFSideSensorObj00_LatPosVar : 88|8@1+ (0.1,0) [0|25.5] "NotApplicable"  VCM
 SG_ LFSideSensorObj00_ObjDynClass : 166|2@1+ (1,0) [0|0] ""  VCM
 SG_ LFSideSensorObj00_CRC : 0|16@1+ (1,0) [0|65535] "NotApplicable"  VCM
 SG_ LFSideSensorObj00_ExistConf : 283|7@1+ (0.01,0) [0|1.27] "NotApplicable"  VCM
 SG_ LFSideSensorObj00_Height : 168|8@1+ (0.02,0) [0|5.1] "m"  VCM
 SG_ LFSideSensorObj00_LongVel : 195|13@1+ (0.032,-80) [-80|182.112] "m_per_s"  VCM
 SG_ LFSideSensorObj00_LongExtBkVar : 64|8@1+ (0.1,0) [0|25.5] "NotApplicable"  VCM
 SG_ LFSideSensorObj00_LatPos : 221|13@1+ (0.05,-180) [-180|229.55] "m"  VCM
 SG_ LFSideSensorObj00_Counter : 16|8@1+ (1,0) [0|255] "Count"  VCM
 SG_ LFSideSensorObj00_ObjClass : 292|4@1+ (1,0) [0|0] ""  VCM
 SG_ LFSideSensorObj00_LatAccVar : 112|8@1+ (0.1,0) [0|25.5] "NotApplicable"  VCM
 SG_ LFSideSensorObj00_TrackStatus : 192|3@1+ (1,0) [0|0] ""  VCM
 SG_ LFSideSensorObj00_LatExtRtVar : 96|8@1+ (0.1,0) [0|25.5] "NotApplicable"  VCM
 SG_ LFSideSensorObj00_ObstacleConf : 300|7@1+ (0.01,0) [0|1.27] "NotApplicable"  VCM
 SG_ LFSideSensorObj00_LongExtBack : 257|10@1+ (0.05,-50) [-50|1.15000000000001] "m"  VCM
 SG_ LFSideSensorObj00_ObjClassConf : 296|4@1+ (0.1,0) [0|1.5] "NotApplicable"  VCM
 SG_ LFSideSensorObj00_LatExtLeftVar : 104|8@1+ (0.1,0) [0|25.5] "NotApplicable"  VCM
 SG_ LFSideSensorObj00_LifeTime : 128|16@1+ (0.1,0) [0|6553.5] "s"  VCM
 SG_ LFSideSensorObj00_LatExtLeft : 276|7@1+ (0.05,0) [0|6.35] "m"  VCM
 SG_ LFSideSensorObj00_TimeStamp : 24|16@1+ (0.1,0) [0|6553.5] "ms"  VCM
 SG_ LFSideSensorObj00_LatVel : 208|13@1+ (0.032,-80) [-80|182.112] "m_per_s"  VCM
 SG_ LFSideSensorObj00_LongExtFront : 247|10@1+ (0.05,0) [0|51.15] "m"  VCM
 SG_ LFSideSensorObj00_LatExtRight : 185|7@1+ (0.05,-5) [-5|1.35] "m"  VCM
 SG_ LFSideSensorObj00_CoastIndex : 155|5@1+ (1,0) [0|31] "NotApplicable"  VCM

BO_ 1556 LFSRSwVersion_Vic4: 64 SR_LF
 SG_ LFSRSwVersion_Substring6 : 384|64@1+ (1,0) [0|0] ""  VCM
 SG_ LFSRSwVersion_Substring2 : 128|64@1+ (1,0) [0|0] ""  VCM
 SG_ LFSRSwVersion_Substring1 : 64|64@1+ (1,0) [0|0] ""  VCM
 SG_ LFSRSwVersion_Substring0 : 0|64@1+ (1,0) [0|0] ""  VCM
 SG_ LFSRSwVersion_Substring3 : 192|64@1+ (1,0) [0|0] ""  VCM
 SG_ LFSRSwVersion_Substring5 : 320|64@1+ (1,0) [0|0] ""  VCM
 SG_ LFSRSwVersion_Substring4 : 256|64@1+ (1,0) [0|0] ""  VCM
 SG_ LFSRSwVersion_Substring7 : 448|64@1+ (1,0) [0|0] ""  VCM

BO_ 847 LFSRRaisedEdge_Vic4: 20 SR_LF
 SG_ LFSRRaisedEdge_LifeTime : 136|16@1+ (0.1,0) [0|6553.5] "s"  VCM
 SG_ LFSRRaisedEdge_HeadingAngle : 80|13@1+ (0.0005,-1.57) [-1.57|2.5255] "rad"  VCM
 SG_ LFSRRaisedEdge_Curvature : 96|18@1+ (1E-006,-0.1310705) [-0.1310705|0.1310725] "per_meter"  VCM
 SG_ LFSRRaisedEdge_CoastIndex : 75|5@1+ (1,0) [0|31] "NotApplicable"  VCM
 SG_ LFSRRaisedEdge_Confidence : 126|7@1+ (0.01,0) [0|1.27] "NotApplicable"  VCM
 SG_ LFSRRaisedEdge_DxEnd : 56|8@1+ (1,0) [0|255] "m"  VCM
 SG_ LFSRRaisedEdge_Type : 133|3@1+ (1,0) [0|0] ""  VCM
 SG_ LFSRRaisedEdge_CurvatureRate : 64|11@1+ (5.1E-007,-0.000516) [-0.000516|0.00052797] "per_meter_squared"  VCM
 SG_ LFSRRaisedEdge_Counter : 16|8@1+ (1,0) [0|255] "Count"  VCM
 SG_ LFSRRaisedEdge_LatDist : 114|12@1+ (0.005,-10) [-10|10.475] "m"  VCM
 SG_ LFSRRaisedEdge_DxStart : 40|8@1+ (1,0) [0|255] "m"  VCM
 SG_ LFSRRaisedEdge_TimeStamp : 24|16@1+ (0.1,0) [0|6553.5] "ms"  VCM
 SG_ LFSRRaisedEdge_CRC : 0|16@1+ (1,0) [0|65535] "NotApplicable"  VCM
 SG_ LFSRRaisedEdge_TrackStatus : 93|3@1+ (1,0) [0|0] ""  VCM
 SG_ LFSRRaisedEdge_LatDistVar : 48|8@1+ (0.001,0) [0|0.255] "NotApplicable"  VCM

BO_ 846 LFSREgoAssumpt_Vic4: 16 SR_LF
 SG_ LFSREgoAssumpt_EgoLongVel : 0|16@1+ (0.00108507,0) [0|71.11006245] "m_per_s"  VCM
 SG_ LFSREgoAssumpt_EgoRoadEnd : 72|8@1+ (1,0) [0|255] "m"  VCM
 SG_ LFSREgoAssumpt_EgoLongAcc : 16|16@1+ (0.00048828125,-15.6875) [-15.6875|16.31201171875] "m_per_s_squared"  VCM
 SG_ LFSREgoAssumpt_EgoRoadCurvature : 104|18@1+ (1E-006,-0.1310705) [-0.1310705|0.1310725] "per_meter"  VCM
 SG_ LFSREgoAssumpt_EgoRoadCurvRate : 93|11@1+ (5.1E-007,-0.000516) [-0.000516|0.00052797] "per_meter_squared"  VCM
 SG_ LFSREgoAssumpt_EgoYawRate : 32|16@1+ (0.000122,-3.92) [-3.92|4.07527] "Rad_per_s"  VCM
 SG_ LFSREgoAssumpt_VelCorrFactor : 64|8@1+ (0.002,0.75) [0.75|1.26] "NotApplicable"  VCM
 SG_ LFSREgoAssumpt_EgoRoadHeading : 80|13@1+ (0.0005,-1.57) [-1.57|2.5255] "rad"  VCM
 SG_ LFSREgoAssumpt_TimeStamp : 48|16@1+ (0.1,0) [0|6553.5] "ms"  VCM

BO_ 2671902708 IntTesterTGW2FuncDiagMsg_Vic4: 8 DACU
 SG_ FuncDiagDataIntTesterTGW2 : 0|64@1+ (1,0) [0|0] ""  SR_LF,SR_LR,SR_RF,SR_RR

BO_ 2671964779 DiagUUDTRespMsg1_F2_6B_Vic4: 8 SR_RF
 SG_ DiagUUDTRespSig_F2_6B : 0|64@1+ (1,0) [0|0] ""  VCM

BO_ 2671964778 DiagUUDTRespMsg1_F2_6A_Vic4: 8 SR_RR
 SG_ DiagUUDTRespSig_F2_6A : 0|64@1+ (1,0) [0|0] ""  VCM

BO_ 2671964777 DiagUUDTRespMsg1_F2_69_Vic4: 8 SR_LF
 SG_ DiagUUDTRespSig_F2_69 : 0|64@1+ (1,0) [0|0] ""  VCM

BO_ 2671964776 DiagUUDTRespMsg1_F2_68_Vic4: 8 SR_LR
 SG_ DiagUUDTRespSig_F2_68 : 0|64@1+ (1,0) [0|0] ""  VCM

BO_ 2671834219 DiagRespMsgIntTGW_F4_6B_Vic4: 8 SR_RF
 SG_ InternalTesterDiagSig_F4_6B : 0|64@1+ (1,0) [0|0] ""  VCM

BO_ 2671834218 DiagRespMsgIntTGW_F4_6A_Vic4: 8 SR_RR
 SG_ InternalTesterDiagSig_F4_6A : 0|64@1+ (1,0) [0|0] ""  VCM

BO_ 2671834217 DiagRespMsgIntTGW_F4_69_Vic4: 8 SR_LF
 SG_ InternalTesterDiagSig_F4_69 : 0|64@1+ (1,0) [0|0] ""  VCM

BO_ 2671834216 DiagRespMsgIntTGW_F4_68_Vic4: 8 SR_LR
 SG_ InternalTesterDiagSig_F4_68 : 0|64@1+ (1,0) [0|0] ""  VCM

BO_ 2671833963 DiagRespMsgIntIC_F3_6B_Vic4: 8 SR_RF
 SG_ InternalTesterDiagSig_F3_6B : 0|64@1+ (1,0) [0|0] ""  VCM

BO_ 2671833962 DiagRespMsgIntIC_F3_6A_Vic4: 8 SR_RR
 SG_ InternalTesterDiagSig_F3_6A : 0|64@1+ (1,0) [0|0] ""  VCM

BO_ 2671833961 DiagRespMsgIntIC_F3_69_Vic4: 8 SR_LF
 SG_ InternalTesterDiagSig_F3_69 : 0|64@1+ (1,0) [0|0] ""  VCM

BO_ 2671833960 DiagRespMsgIntIC_F3_68_Vic4: 8 SR_LR
 SG_ InternalTesterDiagSig_F3_68 : 0|64@1+ (1,0) [0|0] ""  VCM

BO_ 2671799284 DiagReqMsgIntTGW_6B_F4_Vic4: 8 DACU
 SG_ InternalTesterDiagSig_6B_F4 : 0|64@1+ (1,0) [0|0] ""  SR_RF

BO_ 2671799028 DiagReqMsgIntTGW_6A_F4_Vic4: 8 DACU
 SG_ InternalTesterDiagSig_6A_F4 : 0|64@1+ (1,0) [0|0] ""  SR_RR

BO_ 2671798772 DiagReqMsgIntTGW_69_F4_Vic4: 8 DACU
 SG_ InternalTesterDiagSig_69_F4 : 0|64@1+ (1,0) [0|0] ""  SR_LF

BO_ 2671798516 DiagReqMsgIntTGW_68_F4_Vic4: 8 DACU
 SG_ InternalTesterDiagSig_68_F4 : 0|64@1+ (1,0) [0|0] ""  SR_LR

BO_ 2671799283 DiagReqMsgIntIC_6B_F3_Vic4: 8 DACU
 SG_ InternalTesterDiagSig_6B_F3 : 0|64@1+ (1,0) [0|0] ""  SR_RF

BO_ 2671799027 DiagReqMsgIntIC_6A_F3_Vic4: 8 DACU
 SG_ InternalTesterDiagSig_6A_F3 : 0|64@1+ (1,0) [0|0] ""  SR_RR

BO_ 2671798771 DiagReqMsgIntIC_69_F3_Vic4: 8 DACU
 SG_ InternalTesterDiagSig_69_F3 : 0|64@1+ (1,0) [0|0] ""  SR_LF

BO_ 2671798515 DiagReqMsgIntIC_68_F3_Vic4: 8 DACU
 SG_ InternalTesterDiagSig_68_F3 : 0|64@1+ (1,0) [0|0] ""  SR_LR

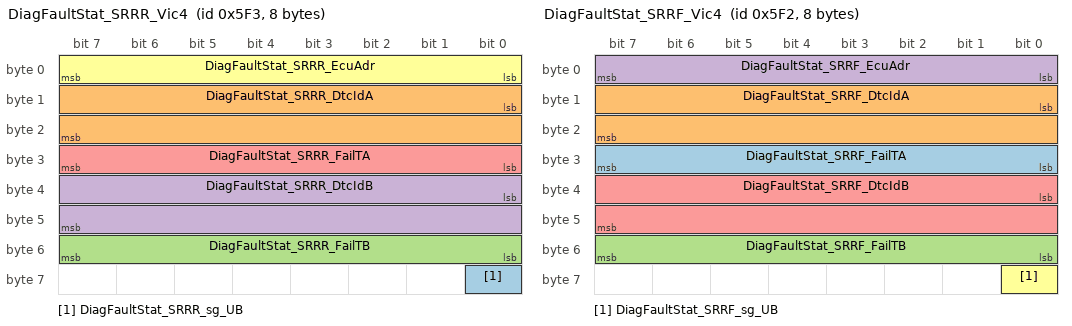
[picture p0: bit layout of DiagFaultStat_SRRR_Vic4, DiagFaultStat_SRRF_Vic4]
BO_ 1523 DiagFaultStat_SRRR_Vic4: 8 SR_RR
 SG_ DiagFaultStat_SRRR_sg_UB : 56|1@1+ (1,0) [0|0] ""  VCM
 SG_ DiagFaultStat_SRRR_DtcIdA : 8|16@1+ (1,0) [0|65535] ""  VCM
 SG_ DiagFaultStat_SRRR_FailTB : 48|8@1+ (1,0) [0|255] ""  VCM
 SG_ DiagFaultStat_SRRR_DtcIdB : 32|16@1+ (1,0) [0|65535] ""  VCM
 SG_ DiagFaultStat_SRRR_FailTA : 24|8@1+ (1,0) [0|255] ""  VCM
 SG_ DiagFaultStat_SRRR_EcuAdr : 0|8@1+ (1,0) [0|255] ""  VCM

BO_ 1522 DiagFaultStat_SRRF_Vic4: 8 SR_RF
 SG_ DiagFaultStat_SRRF_FailTA : 24|8@1+ (1,0) [0|255] ""  VCM
 SG_ DiagFaultStat_SRRF_DtcIdA : 8|16@1+ (1,0) [0|65535] ""  VCM
 SG_ DiagFaultStat_SRRF_FailTB : 48|8@1+ (1,0) [0|255] ""  VCM
 SG_ DiagFaultStat_SRRF_EcuAdr : 0|8@1+ (1,0) [0|255] ""  VCM
 SG_ DiagFaultStat_SRRF_DtcIdB : 32|16@1+ (1,0) [0|65535] ""  VCM
 SG_ DiagFaultStat_SRRF_sg_UB : 56|1@1+ (1,0) [0|0] ""  VCM

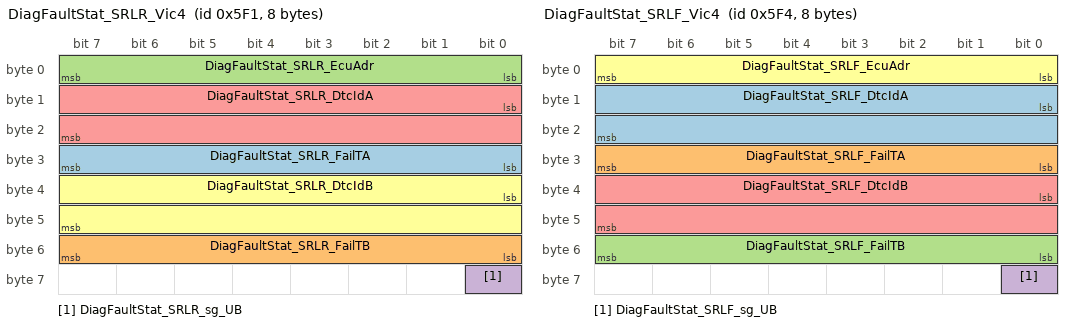
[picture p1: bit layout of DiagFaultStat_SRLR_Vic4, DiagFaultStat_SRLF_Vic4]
BO_ 1521 DiagFaultStat_SRLR_Vic4: 8 SR_LR
 SG_ DiagFaultStat_SRLR_FailTA : 24|8@1+ (1,0) [0|255] ""  VCM
 SG_ DiagFaultStat_SRLR_FailTB : 48|8@1+ (1,0) [0|255] ""  VCM
 SG_ DiagFaultStat_SRLR_EcuAdr : 0|8@1+ (1,0) [0|255] ""  VCM
 SG_ DiagFaultStat_SRLR_sg_UB : 56|1@1+ (1,0) [0|0] ""  VCM
 SG_ DiagFaultStat_SRLR_DtcIdA : 8|16@1+ (1,0) [0|65535] ""  VCM
 SG_ DiagFaultStat_SRLR_DtcIdB : 32|16@1+ (1,0) [0|65535] ""  VCM

BO_ 1524 DiagFaultStat_SRLF_Vic4: 8 SR_LF
 SG_ DiagFaultStat_SRLF_DtcIdA : 8|16@1+ (1,0) [0|65535] ""  VCM
 SG_ DiagFaultStat_SRLF_FailTA : 24|8@1+ (1,0) [0|255] ""  VCM
 SG_ DiagFaultStat_SRLF_FailTB : 48|8@1+ (1,0) [0|255] ""  VCM
 SG_ DiagFaultStat_SRLF_sg_UB : 56|1@1+ (1,0) [0|0] ""  VCM
 SG_ DiagFaultStat_SRLF_DtcIdB : 32|16@1+ (1,0) [0|65535] ""  VCM
 SG_ DiagFaultStat_SRLF_EcuAdr : 0|8@1+ (1,0) [0|255] ""  VCM

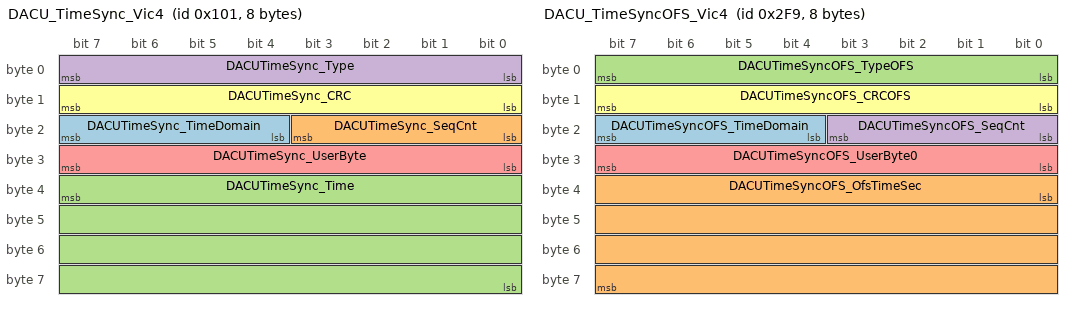
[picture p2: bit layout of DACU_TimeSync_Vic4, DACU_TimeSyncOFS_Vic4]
BO_ 257 DACU_TimeSync_Vic4: 8 DACU
 SG_ DACUTimeSync_TimeDomain : 23|4@0+ (1,0) [0|15] "Count"  SR_RR,SR_LF,SR_RF,SR_LR
 SG_ DACUTimeSync_SeqCnt : 19|4@0+ (1,0) [0|15] "Count"  SR_LF,SR_RR,SR_LR,SR_RF
 SG_ DACUTimeSync_Time : 39|32@0+ (1,0) [0|0] ""  SR_LR,SR_RF,SR_LF,SR_RR
 SG_ DACUTimeSync_Type : 7|8@0+ (1,0) [0|0] ""  SR_LR,SR_RR,SR_RF,SR_LF
 SG_ DACUTimeSync_UserByte : 31|8@0+ (1,0) [0|0] ""  SR_LF,SR_RF,SR_LR,SR_RR
 SG_ DACUTimeSync_CRC : 15|8@0+ (1,0) [0|0] ""  SR_LR,SR_RR,SR_LF,SR_RF

BO_ 761 DACU_TimeSyncOFS_Vic4: 8 DACU
 SG_ DACUTimeSyncOFS_TimeDomain : 20|4@1+ (1,16) [16|31] "NotApplicable"  SR_LR,SR_RR,SR_LF,SR_RF
 SG_ DACUTimeSyncOFS_OfsTimeSec : 32|32@1+ (1,0) [0|0] ""  SR_LR,SR_LF,SR_RR,SR_RF
 SG_ DACUTimeSyncOFS_TypeOFS : 0|8@1+ (1,0) [0|0] ""  SR_RF,SR_LF,SR_RR,SR_LR
 SG_ DACUTimeSyncOFS_SeqCnt : 16|4@1+ (1,0) [0|15] "Count"  SR_RR,SR_RF,SR_LF,SR_LR
 SG_ DACUTimeSyncOFS_UserByte0 : 24|8@1+ (1,0) [0|0] ""  SR_LR,SR_RR,SR_LF,SR_RF
 SG_ DACUTimeSyncOFS_CRCOFS : 8|8@1+ (1,0) [0|0] ""  SR_LF,SR_RF,SR_RR,SR_LR

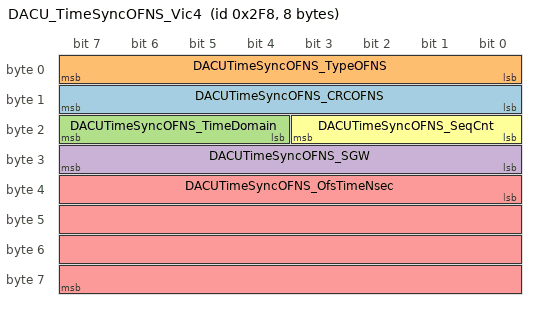
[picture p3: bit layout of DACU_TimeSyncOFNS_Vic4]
BO_ 760 DACU_TimeSyncOFNS_Vic4: 8 DACU
 SG_ DACUTimeSyncOFNS_CRCOFNS : 8|8@1+ (1,0) [0|0] ""  SR_LF,SR_RF,SR_RR,SR_LR
 SG_ DACUTimeSyncOFNS_TypeOFNS : 0|8@1+ (1,0) [0|0] ""  SR_LF,SR_LR,SR_RF,SR_RR
 SG_ DACUTimeSyncOFNS_TimeDomain : 20|4@1+ (1,16) [16|31] "NotApplicable"  SR_RF,SR_RR,SR_LR,SR_LF
 SG_ DACUTimeSyncOFNS_SGW : 24|8@1+ (1,0) [0|0] ""  SR_RR,SR_LR,SR_LF,SR_RF
 SG_ DACUTimeSyncOFNS_OfsTimeNsec : 32|32@1+ (1,0) [0|0] ""  SR_RR,SR_LR,SR_RF,SR_LF
 SG_ DACUTimeSyncOFNS_SeqCnt : 16|4@1+ (1,0) [0|15] "Count"  SR_RF,SR_LR,SR_LF,SR_RR

BO_ 279 DACU_EgoPathPrediction_Vic4: 16 DACU
 SG_ EgoPathPrediction_DxEnd : 0|8@1+ (1,-126) [-126|129] "m"  SR_RR,SR_LF,SR_RF,SR_LR
 SG_ EgoPathPrediction_ConfCoeffA1 : 40|16@1+ (0.001,-30) [-30|35.535] "NotApplicable"  SR_RR,SR_LR,SR_RF,SR_LF
 SG_ EgoPathPrediction_ConfCoeffA0 : 8|16@1+ (0.001,-30) [-30|35.535] "NotApplicable"  SR_LF,SR_LR,SR_RR,SR_RF
 SG_ EgoPathPrediction_ConfCoeffA2 : 24|16@1+ (0.001,-30) [-30|35.535] "NotApplicable"  SR_LR,SR_RF,SR_LF,SR_RR
 SG_ EgoPathPrediction_Curvature : 96|18@1+ (1E-006,-0.1310705) [-0.1310705|0.1310725] "per_meter"  SR_RF,SR_LR,SR_RR,SR_LF
 SG_ EgoPathPrediction_HeadingAngle : 72|13@1+ (0.0005,-1.57) [-1.57|2.5255] "rad"  SR_LF,SR_LR,SR_RF,SR_RR
 SG_ EgoPathPrediction_ConfCoeffA3 : 56|16@1+ (0.001,-30) [-30|35.535] "NotApplicable"  SR_RR,SR_RF,SR_LR,SR_LF
 SG_ EgoPathPrediction_CurvatureRate : 85|11@1+ (5.1E-007,-0.000516) [-0.000516|0.00052797] "per_meter_squared"  SR_RF,SR_RR,SR_LR,SR_LF

BO_ 275 DACU_EgoMotion_Vic4: 32 DACU
 SG_ EgoMotionXYplane_LateralAcc : 56|16@1+ (0.00048828125,-15.687) [-15.687|16.31251171875] "m_per_s_squared"  SR_LR,SR_RR,SR_RF,SR_LF
 SG_ EgoMotionXYplane_LongAcc : 24|16@1+ (0.00048828125,-15.687) [-15.687|16.31251171875] "m_per_s_squared"  SR_LF,SR_LR,SR_RR,SR_RF
 SG_ EgoMotionXYplane_LongSpeed : 104|16@1+ (0.00108507,0) [0|71.11006245] "m_per_s"  SR_RF,SR_LR,SR_LF,SR_RR
 SG_ EgoMotionXYplane_LongMotDirConf : 190|4@1+ (1,0) [0|0] ""  SR_LF,SR_RR,SR_LR,SR_RF
 SG_ EgoMotionXYplane_Curvature : 200|21@1+ (1E-006,-1.0486) [-1.0486|1.048551] "per_meter"  SR_RR,SR_LR,SR_LF,SR_RF
 SG_ EgoMotionXYplane_EffectiveWheelB : 224|10@1+ (10,2000) [2000|12230] "mm"  SR_RF,SR_RR,SR_LF,SR_LR
 SG_ EgoMotionXYplane_LongMotionDir : 221|3@1+ (1,0) [0|0] ""  SR_RR,SR_LF,SR_LR,SR_RF
 SG_ EgoMotionXYplane_LongSpeedVar : 72|16@1+ (0.00115384616,0) [0|75.6173080956] "NotApplicable"  SR_RR,SR_LF,SR_RF,SR_LR
 SG_ EgoMotionXYplane_Counter : 16|8@1+ (1,0) [0|255] "Count"  SR_RF,SR_LF,SR_LR,SR_RR
 SG_ EgoMotionXYplane_LatencyEst : 176|8@1+ (1,0) [0|255] "ms"  SR_LF,SR_RF,SR_RR,SR_LR
 SG_ EgoMotionXYplane_LatAccVariance : 194|6@1+ (0.1,0) [0|6.3] "NotApplicable"  SR_LF,SR_RR,SR_RF,SR_LR
 SG_ EgoMotionXYplane_CRC : 0|16@1+ (1,0) [0|65535] "NotApplicable"  SR_RF,SR_LR,SR_LF,SR_RR
 SG_ EgoMotionXYplane_ReferencePointX : 40|16@1+ (0.001,-32) [-32|33.535] "m"  SR_RR,SR_LF,SR_RF,SR_LR
 SG_ EgoMotionXYplane_LateralSpeed : 152|16@1+ (0.00108507,-35) [-35|36.11006245] "m_per_s"  SR_LF,SR_RR,SR_RF,SR_LR
 SG_ EgoMotionXYplane_LatSpeedVar : 88|16@1+ (0.00153846154,0) [0|100.8230770239] "NotApplicable"  SR_RF,SR_LF,SR_LR,SR_RR
 SG_ EgoMotionXYplane_YawRateComp : 136|16@1+ (0.000122,-3.92) [-3.92|4.07527] "Rad_per_s"  SR_LR,SR_RR,SR_RF,SR_LF
 SG_ EgoMotionXYplane_ChassisDynPitch : 168|8@1+ (0.001,-0.126) [-0.126|0.129] "rad"  SR_RF,SR_RR,SR_LR,SR_LF
 SG_ EgoMotionXYplane_YawRateVariance : 120|16@1+ (3.846154E-005,0) [0|2.5205770239] "NotApplicable"  SR_LF,SR_LR,SR_RR,SR_RF
 SG_ EgoMotionXYplane_LongAccVariance : 184|6@1+ (0.1,0) [0|6.3] "NotApplicable"  SR_LF,SR_RR,SR_LR,SR_RF

CM_ BO_ 275 "Default 20 msec. TriggeredBy Application";
BA_DEF_ BO_  "GenMsgStartDelayTime" INT 0 0;
BA_DEF_ BO_  "GenMsgDelayTime" INT 0 0;
BA_DEF_ BO_  "GenMsgCycleTime" INT 0 0;
BA_DEF_ BO_  "GenMsgSendType" ENUM  "Cyclic","NotUsed","NotUsed","NotUsed","NotUsed","NotUsed","NotUsed","IfActive","NoMsgSendType","NotUsed";
BA_DEF_ SG_  "GenSigStartValue" INT 0 0;
BA_DEF_ SG_  "GenSigCycleTimeActive" INT 0 0;
BA_DEF_ SG_  "GenSigCycleTime" INT 0 0;
BA_DEF_ SG_  "GenSigSendType" ENUM  "Cyclic","OnWrite","OnWriteWithRepetition","OnChange","OnChangeWithRepetition","IfActive","IfActiveWithRepetition","NoSigSendType","NotUsed","NotUsed","NotUsed","NotUsed","NotUsed";
BA_DEF_ BO_  "VFrameFormat" ENUM  "StandardCAN","ExtendedCAN","reserved","J1939PG","reserved","reserved","reserved","reserved","reserved","reserved","reserved","reserved","reserved","reserved","StandardCAN_FD","ExtendedCAN_FD";
BA_DEF_ SG_  "SigType" ENUM  "Default","Range","RangeSigned","ASCII","Discrete","Control","ReferencePGN","DTC","StringDelimiter","StringLength","StringLengthControl";
BA_DEF_ SG_  "SeToolVersion_SIGNAL" STRING ;
BA_DEF_ SG_  "SeToolUniqueID_SIGNAL" STRING ;
BA_DEF_ SG_  "SeToolName_SIGNAL" STRING ;
BA_DEF_ SG_  "SeToolItemID_SIGNAL" STRING ;
BA_DEF_ SG_  "SeToolAncestorID_SIGNAL" STRING ;
BA_DEF_ SG_  "Platform_VMCU1_Sig" ENUM  "No","Yes";
BA_DEF_ SG_  "NeedsUpdateBit" ENUM  "No","Yes";
BA_DEF_ SG_  "GenSigMaxLatency" INT 0 65535;
BA_DEF_ SG_  "GenSigILSupport" ENUM  "Yes","No";
BA_DEF_ BO_  "GenMsgILSupport" ENUM  "No","Yes";
BA_DEF_ SG_  "E2EProfile" STRING ;
BA_DEF_ SG_  "E2EDataLength" INT 0 65535;
BA_DEF_ SG_  "E2EDataId" INT 0 65535;
BA_DEF_ BO_  "DiagUUDTResponse" ENUM  "No","Yes";
BA_DEF_ BO_  "DiagState" ENUM  "No","Yes";
BA_DEF_ BO_  "DiagResponse" ENUM  "No","Yes";
BA_DEF_ BO_  "DiagRequest" ENUM  "No","Yes";
BA_DEF_ BO_  "DiagConnection" HEX 0 65535;
BA_DEF_ BO_  "CanTpFcFrameId" HEX 0 2147483647;
BA_DEF_ BO_  "CanTpBs" INT 0 255;
BA_DEF_ BO_  "CANFD_BRS" ENUM  "0","1";
BA_DEF_REL_ BU_SG_REL_  "GenSigTimeoutTime" INT 0 65535;
BA_DEF_REL_ BU_SG_REL_  "GenSigFirstTimeoutTime" INT 0 65535;
BA_DEF_DEF_  "GenMsgStartDelayTime" 0;
BA_DEF_DEF_  "GenMsgDelayTime" 0;
BA_DEF_DEF_  "GenMsgCycleTime" 0;
BA_DEF_DEF_  "GenMsgSendType" "Cyclic";
BA_DEF_DEF_  "GenSigStartValue" 0;
BA_DEF_DEF_  "GenSigCycleTimeActive" 0;
BA_DEF_DEF_  "GenSigCycleTime" 0;
BA_DEF_DEF_  "GenSigSendType" "Cyclic";
BA_DEF_DEF_  "VFrameFormat" "ExtendedCAN";
BA_DEF_DEF_  "SigType" "Default";
BA_DEF_DEF_  "SeToolVersion_SIGNAL" "";
BA_DEF_DEF_  "SeToolUniqueID_SIGNAL" "";
BA_DEF_DEF_  "SeToolName_SIGNAL" "";
BA_DEF_DEF_  "SeToolItemID_SIGNAL" "";
BA_DEF_DEF_  "SeToolAncestorID_SIGNAL" "";
BA_DEF_DEF_  "Platform_VMCU1_Sig" "No";
BA_DEF_DEF_  "NeedsUpdateBit" "No";
BA_DEF_DEF_  "GenSigMaxLatency" 0;
BA_DEF_DEF_  "GenSigILSupport" "Yes";
BA_DEF_DEF_  "GenMsgILSupport" "Yes";
BA_DEF_DEF_  "E2EProfile" "none";
BA_DEF_DEF_  "E2EDataLength" 0;
BA_DEF_DEF_  "E2EDataId" 0;
BA_DEF_DEF_  "DiagUUDTResponse" "No";
BA_DEF_DEF_  "DiagState" "No";
BA_DEF_DEF_  "DiagResponse" "No";
BA_DEF_DEF_  "DiagRequest" "No";
BA_DEF_DEF_  "DiagConnection" 0;
BA_DEF_DEF_  "CanTpFcFrameId" 2147483647;
BA_DEF_DEF_  "CanTpBs" 255;
BA_DEF_DEF_  "CANFD_BRS" "0";
BA_DEF_DEF_REL_ "GenSigTimeoutTime" 0;
BA_DEF_DEF_REL_ "GenSigFirstTimeoutTime" 0;
BA_ "CANFD_BRS" BO_ 842 1;
BA_ "GenMsgSendType" BO_ 842 8;
BA_ "GenMsgDelayTime" BO_ 842 10;
BA_ "VFrameFormat" BO_ 842 14;
BA_ "CANFD_BRS" BO_ 841 1;
BA_ "GenMsgSendType" BO_ 841 8;
BA_ "GenMsgDelayTime" BO_ 841 10;
BA_ "VFrameFormat" BO_ 841 14;
BA_ "CANFD_BRS" BO_ 840 1;
BA_ "GenMsgSendType" BO_ 840 8;
BA_ "GenMsgDelayTime" BO_ 840 10;
BA_ "VFrameFormat" BO_ 840 14;
BA_ "CANFD_BRS" BO_ 839 1;
BA_ "GenMsgSendType" BO_ 839 8;
BA_ "GenMsgDelayTime" BO_ 839 10;
BA_ "VFrameFormat" BO_ 839 14;
BA_ "CANFD_BRS" BO_ 838 1;
BA_ "GenMsgSendType" BO_ 838 8;
BA_ "GenMsgDelayTime" BO_ 838 10;
BA_ "VFrameFormat" BO_ 838 14;
BA_ "CANFD_BRS" BO_ 837 1;
BA_ "GenMsgSendType" BO_ 837 8;
BA_ "GenMsgDelayTime" BO_ 837 10;
BA_ "VFrameFormat" BO_ 837 14;
BA_ "CANFD_BRS" BO_ 836 1;
BA_ "GenMsgSendType" BO_ 836 8;
BA_ "GenMsgDelayTime" BO_ 836 10;
BA_ "VFrameFormat" BO_ 836 14;
BA_ "CANFD_BRS" BO_ 835 1;
BA_ "GenMsgSendType" BO_ 835 8;
BA_ "GenMsgDelayTime" BO_ 835 10;
BA_ "VFrameFormat" BO_ 835 14;
BA_ "CANFD_BRS" BO_ 834 1;
BA_ "GenMsgSendType" BO_ 834 8;
BA_ "GenMsgDelayTime" BO_ 834 10;
BA_ "VFrameFormat" BO_ 834 14;
BA_ "CANFD_BRS" BO_ 833 1;
BA_ "GenMsgSendType" BO_ 833 8;
BA_ "GenMsgDelayTime" BO_ 833 10;
BA_ "VFrameFormat" BO_ 833 14;
BA_ "CANFD_BRS" BO_ 832 1;
BA_ "GenMsgSendType" BO_ 832 8;
BA_ "GenMsgDelayTime" BO_ 832 10;
BA_ "VFrameFormat" BO_ 832 14;
BA_ "CANFD_BRS" BO_ 1556 1;
BA_ "GenMsgCycleTime" BO_ 1556 10000;
BA_ "GenMsgStartDelayTime" BO_ 1556 125;
BA_ "VFrameFormat" BO_ 1556 14;
BA_ "CANFD_BRS" BO_ 847 1;
BA_ "GenMsgSendType" BO_ 847 8;
BA_ "VFrameFormat" BO_ 847 14;
BA_ "CANFD_BRS" BO_ 846 1;
BA_ "GenMsgSendType" BO_ 846 8;
BA_ "VFrameFormat" BO_ 846 14;
BA_ "DiagConnection" BO_ 2671902708 62568;
BA_ "DiagState" BO_ 2671902708 1;
BA_ "GenMsgILSupport" BO_ 2671902708 0;
BA_ "GenMsgSendType" BO_ 2671902708 8;
BA_ "DiagConnection" BO_ 2671964779 62059;
BA_ "DiagUUDTResponse" BO_ 2671964779 1;
BA_ "GenMsgILSupport" BO_ 2671964779 0;
BA_ "GenMsgSendType" BO_ 2671964779 8;
BA_ "DiagConnection" BO_ 2671964778 62058;
BA_ "DiagUUDTResponse" BO_ 2671964778 1;
BA_ "GenMsgILSupport" BO_ 2671964778 0;
BA_ "GenMsgSendType" BO_ 2671964778 8;
BA_ "DiagConnection" BO_ 2671964777 62057;
BA_ "DiagUUDTResponse" BO_ 2671964777 1;
BA_ "GenMsgILSupport" BO_ 2671964777 0;
BA_ "GenMsgSendType" BO_ 2671964777 8;
BA_ "DiagConnection" BO_ 2671964776 62056;
BA_ "DiagUUDTResponse" BO_ 2671964776 1;
BA_ "GenMsgILSupport" BO_ 2671964776 0;
BA_ "GenMsgSendType" BO_ 2671964776 8;
BA_ "DiagConnection" BO_ 2671834219 62571;
BA_ "DiagResponse" BO_ 2671834219 1;
BA_ "GenMsgILSupport" BO_ 2671834219 0;
BA_ "GenMsgSendType" BO_ 2671834219 8;
BA_ "DiagConnection" BO_ 2671834218 62570;
BA_ "DiagResponse" BO_ 2671834218 1;
BA_ "GenMsgILSupport" BO_ 2671834218 0;
BA_ "GenMsgSendType" BO_ 2671834218 8;
BA_ "DiagConnection" BO_ 2671834217 62569;
BA_ "DiagResponse" BO_ 2671834217 1;
BA_ "GenMsgILSupport" BO_ 2671834217 0;
BA_ "GenMsgSendType" BO_ 2671834217 8;
BA_ "DiagConnection" BO_ 2671834216 62568;
BA_ "DiagResponse" BO_ 2671834216 1;
BA_ "GenMsgILSupport" BO_ 2671834216 0;
BA_ "GenMsgSendType" BO_ 2671834216 8;
BA_ "DiagConnection" BO_ 2671833963 62315;
BA_ "DiagResponse" BO_ 2671833963 1;
BA_ "GenMsgILSupport" BO_ 2671833963 0;
BA_ "GenMsgSendType" BO_ 2671833963 8;
BA_ "DiagConnection" BO_ 2671833962 62314;
BA_ "DiagResponse" BO_ 2671833962 1;
BA_ "GenMsgILSupport" BO_ 2671833962 0;
BA_ "GenMsgSendType" BO_ 2671833962 8;
BA_ "DiagConnection" BO_ 2671833961 62313;
BA_ "DiagResponse" BO_ 2671833961 1;
BA_ "GenMsgILSupport" BO_ 2671833961 0;
BA_ "GenMsgSendType" BO_ 2671833961 8;
BA_ "DiagConnection" BO_ 2671833960 62312;
BA_ "DiagResponse" BO_ 2671833960 1;
BA_ "GenMsgILSupport" BO_ 2671833960 0;
BA_ "GenMsgSendType" BO_ 2671833960 8;
BA_ "DiagConnection" BO_ 2671799284 62571;
BA_ "DiagRequest" BO_ 2671799284 1;
BA_ "GenMsgILSupport" BO_ 2671799284 0;
BA_ "GenMsgSendType" BO_ 2671799284 8;
BA_ "DiagConnection" BO_ 2671799028 62570;
BA_ "DiagRequest" BO_ 2671799028 1;
BA_ "GenMsgILSupport" BO_ 2671799028 0;
BA_ "GenMsgSendType" BO_ 2671799028 8;
BA_ "DiagConnection" BO_ 2671798772 62569;
BA_ "DiagRequest" BO_ 2671798772 1;
BA_ "GenMsgILSupport" BO_ 2671798772 0;
BA_ "GenMsgSendType" BO_ 2671798772 8;
BA_ "DiagConnection" BO_ 2671798516 62568;
BA_ "DiagRequest" BO_ 2671798516 1;
BA_ "GenMsgILSupport" BO_ 2671798516 0;
BA_ "GenMsgSendType" BO_ 2671798516 8;
BA_ "DiagConnection" BO_ 2671799283 62315;
BA_ "DiagRequest" BO_ 2671799283 1;
BA_ "GenMsgILSupport" BO_ 2671799283 0;
BA_ "GenMsgSendType" BO_ 2671799283 8;
BA_ "DiagConnection" BO_ 2671799027 62314;
BA_ "DiagRequest" BO_ 2671799027 1;
BA_ "GenMsgILSupport" BO_ 2671799027 0;
BA_ "GenMsgSendType" BO_ 2671799027 8;
BA_ "DiagConnection" BO_ 2671798771 62313;
BA_ "DiagRequest" BO_ 2671798771 1;
BA_ "GenMsgILSupport" BO_ 2671798771 0;
BA_ "GenMsgSendType" BO_ 2671798771 8;
BA_ "DiagConnection" BO_ 2671798515 62312;
BA_ "DiagRequest" BO_ 2671798515 1;
BA_ "GenMsgILSupport" BO_ 2671798515 0;
BA_ "GenMsgSendType" BO_ 2671798515 8;
BA_ "CANFD_BRS" BO_ 1523 1;
BA_ "GenMsgCycleTime" BO_ 1523 1000;
BA_ "GenMsgDelayTime" BO_ 1523 80;
BA_ "GenMsgStartDelayTime" BO_ 1523 5;
BA_ "VFrameFormat" BO_ 1523 14;
BA_ "CANFD_BRS" BO_ 1522 1;
BA_ "GenMsgCycleTime" BO_ 1522 1000;
BA_ "GenMsgDelayTime" BO_ 1522 80;
BA_ "GenMsgStartDelayTime" BO_ 1522 5;
BA_ "VFrameFormat" BO_ 1522 14;
BA_ "CANFD_BRS" BO_ 1521 1;
BA_ "GenMsgCycleTime" BO_ 1521 1000;
BA_ "GenMsgDelayTime" BO_ 1521 80;
BA_ "GenMsgStartDelayTime" BO_ 1521 5;
BA_ "VFrameFormat" BO_ 1521 14;
BA_ "CANFD_BRS" BO_ 1524 1;
BA_ "GenMsgCycleTime" BO_ 1524 1000;
BA_ "GenMsgDelayTime" BO_ 1524 80;
BA_ "GenMsgStartDelayTime" BO_ 1524 5;
BA_ "VFrameFormat" BO_ 1524 14;
BA_ "CANFD_BRS" BO_ 257 1;
BA_ "GenMsgSendType" BO_ 257 8;
BA_ "VFrameFormat" BO_ 257 14;
BA_ "CANFD_BRS" BO_ 761 1;
BA_ "GenMsgSendType" BO_ 761 8;
BA_ "VFrameFormat" BO_ 761 14;
BA_ "CANFD_BRS" BO_ 760 1;
BA_ "GenMsgSendType" BO_ 760 8;
BA_ "VFrameFormat" BO_ 760 14;
BA_ "CANFD_BRS" BO_ 279 1;
BA_ "GenMsgCycleTime" BO_ 279 20;
BA_ "GenMsgStartDelayTime" BO_ 279 15;
BA_ "VFrameFormat" BO_ 279 14;
BA_ "CANFD_BRS" BO_ 275 1;
BA_ "GenMsgSendType" BO_ 275 8;
BA_ "VFrameFormat" BO_ 275 14;
BA_ "GenSigSendType" SG_ 842 LFSideSensorObj10_LatExtLeft 1;
BA_ "GenSigStartValue" SG_ 842 LFSideSensorObj10_LatExtLeft 127;
BA_ "GenSigSendType" SG_ 842 LFSideSensorObj10_LatVel 1;
BA_ "GenSigStartValue" SG_ 842 LFSideSensorObj10_LatVel 8191;
BA_ "GenSigSendType" SG_ 842 LFSideSensorObj10_LatPosVar 1;
BA_ "GenSigStartValue" SG_ 842 LFSideSensorObj10_LatPosVar 255;
BA_ "GenSigSendType" SG_ 842 LFSideSensorObj10_LongAccVar 1;
BA_ "GenSigStartValue" SG_ 842 LFSideSensorObj10_LongAccVar 255;
BA_ "GenSigSendType" SG_ 842 LFSideSensorObj10_LongPos 1;
BA_ "GenSigStartValue" SG_ 842 LFSideSensorObj10_LongPos 8191;
BA_ "GenSigSendType" SG_ 842 LFSideSensorObj10_ObstacleConf 1;
BA_ "GenSigStartValue" SG_ 842 LFSideSensorObj10_ObstacleConf 127;
BA_ "GenSigSendType" SG_ 842 LFSideSensorObj10_LatExtRtVar 1;
BA_ "GenSigStartValue" SG_ 842 LFSideSensorObj10_LatExtRtVar 255;
BA_ "GenSigSendType" SG_ 842 LFSideSensorObj10_Prioritisation 1;
BA_ "GenSigStartValue" SG_ 842 LFSideSensorObj10_Prioritisation 3;
BA_ "GenSigSendType" SG_ 842 LFSideSensorObj10_HeadingVar 1;
BA_ "GenSigStartValue" SG_ 842 LFSideSensorObj10_HeadingVar 255;
BA_ "GenSigSendType" SG_ 842 LFSideSensorObj10_ExistConf 1;
BA_ "GenSigStartValue" SG_ 842 LFSideSensorObj10_ExistConf 127;
BA_ "GenSigSendType" SG_ 842 LFSideSensorObj10_Counter 1;
BA_ "GenSigStartValue" SG_ 842 LFSideSensorObj10_Counter 255;
BA_ "GenSigSendType" SG_ 842 LFSideSensorObj10_ObjDynClass 1;
BA_ "GenSigStartValue" SG_ 842 LFSideSensorObj10_ObjDynClass 3;
BA_ "GenSigSendType" SG_ 842 LFSideSensorObj10_LatAcc 1;
BA_ "GenSigStartValue" SG_ 842 LFSideSensorObj10_LatAcc 511;
BA_ "GenSigSendType" SG_ 842 LFSideSensorObj10_TrackStatus 1;
BA_ "GenSigStartValue" SG_ 842 LFSideSensorObj10_TrackStatus 7;
BA_ "GenSigSendType" SG_ 842 LFSideSensorObj10_CoastIndex 1;
BA_ "GenSigStartValue" SG_ 842 LFSideSensorObj10_CoastIndex 31;
BA_ "GenSigSendType" SG_ 842 LFSideSensorObj10_LongVelVar 1;
BA_ "GenSigStartValue" SG_ 842 LFSideSensorObj10_LongVelVar 255;
BA_ "GenSigSendType" SG_ 842 LFSideSensorObj10_LongExtFrVar 1;
BA_ "GenSigStartValue" SG_ 842 LFSideSensorObj10_LongExtFrVar 255;
BA_ "GenSigSendType" SG_ 842 LFSideSensorObj10_LongExtFront 1;
BA_ "GenSigStartValue" SG_ 842 LFSideSensorObj10_LongExtFront 1023;
BA_ "GenSigSendType" SG_ 842 LFSideSensorObj10_LatExtRight 1;
BA_ "GenSigStartValue" SG_ 842 LFSideSensorObj10_LatExtRight 127;
BA_ "GenSigSendType" SG_ 842 LFSideSensorObj10_MOISPrio 1;
BA_ "GenSigSendType" SG_ 842 LFSideSensorObj10_LongAcc 1;
BA_ "GenSigStartValue" SG_ 842 LFSideSensorObj10_LongAcc 511;
BA_ "GenSigSendType" SG_ 842 LFSideSensorObj10_LongVel 1;
BA_ "GenSigStartValue" SG_ 842 LFSideSensorObj10_LongVel 8191;
BA_ "GenSigSendType" SG_ 842 LFSideSensorObj10_LongExtBack 1;
BA_ "GenSigStartValue" SG_ 842 LFSideSensorObj10_LongExtBack 1023;
BA_ "GenSigSendType" SG_ 842 LFSideSensorObj10_ObjClassConf 1;
BA_ "GenSigStartValue" SG_ 842 LFSideSensorObj10_ObjClassConf 15;
BA_ "GenSigSendType" SG_ 842 LFSideSensorObj10_LatVelVar 1;
BA_ "GenSigStartValue" SG_ 842 LFSideSensorObj10_LatVelVar 255;
BA_ "GenSigSendType" SG_ 842 LFSideSensorObj10_TimeStamp 1;
BA_ "GenSigStartValue" SG_ 842 LFSideSensorObj10_TimeStamp 65535;
BA_ "GenSigSendType" SG_ 842 LFSideSensorObj10_ObjID 1;
BA_ "GenSigStartValue" SG_ 842 LFSideSensorObj10_ObjID 63;
BA_ "GenSigSendType" SG_ 842 LFSideSensorObj10_ObjClass 1;
BA_ "GenSigStartValue" SG_ 842 LFSideSensorObj10_ObjClass 15;
BA_ "GenSigSendType" SG_ 842 LFSideSensorObj10_LifeTime 1;
BA_ "GenSigStartValue" SG_ 842 LFSideSensorObj10_LifeTime 65535;
BA_ "GenSigSendType" SG_ 842 LFSideSensorObj10_LongPosVar 1;
BA_ "GenSigStartValue" SG_ 842 LFSideSensorObj10_LongPosVar 255;
BA_ "GenSigSendType" SG_ 842 LFSideSensorObj10_LongExtBkVar 1;
BA_ "GenSigStartValue" SG_ 842 LFSideSensorObj10_LongExtBkVar 255;
BA_ "GenSigSendType" SG_ 842 LFSideSensorObj10_LatExtLeftVar 1;
BA_ "GenSigStartValue" SG_ 842 LFSideSensorObj10_LatExtLeftVar 255;
BA_ "GenSigSendType" SG_ 842 LFSideSensorObj10_Heading 1;
BA_ "GenSigStartValue" SG_ 842 LFSideSensorObj10_Heading 2047;
BA_ "GenSigSendType" SG_ 842 LFSideSensorObj10_CRC 1;
BA_ "GenSigStartValue" SG_ 842 LFSideSensorObj10_CRC 65535;
BA_ "E2EDataId" SG_ 842 LFSideSensorObj10_CRC 28;
BA_ "E2EDataLength" SG_ 842 LFSideSensorObj10_CRC 312;
BA_ "E2EProfile" SG_ 842 LFSideSensorObj10_CRC "P05";
BA_ "GenSigSendType" SG_ 842 LFSideSensorObj10_LatAccVar 1;
BA_ "GenSigStartValue" SG_ 842 LFSideSensorObj10_LatAccVar 255;
BA_ "GenSigSendType" SG_ 842 LFSideSensorObj10_Height 1;
BA_ "GenSigStartValue" SG_ 842 LFSideSensorObj10_Height 255;
BA_ "GenSigSendType" SG_ 842 LFSideSensorObj10_LatPos 1;
BA_ "GenSigStartValue" SG_ 842 LFSideSensorObj10_LatPos 8191;
BA_ "GenSigSendType" SG_ 841 LFSideSensorObj09_Prioritisation 1;
BA_ "GenSigStartValue" SG_ 841 LFSideSensorObj09_Prioritisation 3;
BA_ "GenSigSendType" SG_ 841 LFSideSensorObj09_TimeStamp 1;
BA_ "GenSigStartValue" SG_ 841 LFSideSensorObj09_TimeStamp 65535;
BA_ "GenSigSendType" SG_ 841 LFSideSensorObj09_CoastIndex 1;
BA_ "GenSigStartValue" SG_ 841 LFSideSensorObj09_CoastIndex 31;
BA_ "GenSigSendType" SG_ 841 LFSideSensorObj09_MOISPrio 1;
BA_ "GenSigSendType" SG_ 841 LFSideSensorObj09_ExistConf 1;
BA_ "GenSigStartValue" SG_ 841 LFSideSensorObj09_ExistConf 127;
BA_ "GenSigSendType" SG_ 841 LFSideSensorObj09_Counter 1;
BA_ "GenSigStartValue" SG_ 841 LFSideSensorObj09_Counter 255;
BA_ "GenSigSendType" SG_ 841 LFSideSensorObj09_TrackStatus 1;
BA_ "GenSigStartValue" SG_ 841 LFSideSensorObj09_TrackStatus 7;
BA_ "GenSigSendType" SG_ 841 LFSideSensorObj09_LongExtFront 1;
BA_ "GenSigStartValue" SG_ 841 LFSideSensorObj09_LongExtFront 1023;
BA_ "GenSigSendType" SG_ 841 LFSideSensorObj09_LatPos 1;
BA_ "GenSigStartValue" SG_ 841 LFSideSensorObj09_LatPos 8191;
BA_ "GenSigSendType" SG_ 841 LFSideSensorObj09_LongExtFrVar 1;
BA_ "GenSigStartValue" SG_ 841 LFSideSensorObj09_LongExtFrVar 255;
BA_ "GenSigSendType" SG_ 841 LFSideSensorObj09_CRC 1;
BA_ "GenSigStartValue" SG_ 841 LFSideSensorObj09_CRC 65535;
BA_ "E2EDataId" SG_ 841 LFSideSensorObj09_CRC 27;
BA_ "E2EDataLength" SG_ 841 LFSideSensorObj09_CRC 312;
BA_ "E2EProfile" SG_ 841 LFSideSensorObj09_CRC "P05";
BA_ "GenSigSendType" SG_ 841 LFSideSensorObj09_LongVelVar 1;
BA_ "GenSigStartValue" SG_ 841 LFSideSensorObj09_LongVelVar 255;
BA_ "GenSigSendType" SG_ 841 LFSideSensorObj09_LongPosVar 1;
BA_ "GenSigStartValue" SG_ 841 LFSideSensorObj09_LongPosVar 255;
BA_ "GenSigSendType" SG_ 841 LFSideSensorObj09_LongExtBkVar 1;
BA_ "GenSigStartValue" SG_ 841 LFSideSensorObj09_LongExtBkVar 255;
BA_ "GenSigSendType" SG_ 841 LFSideSensorObj09_LongPos 1;
BA_ "GenSigStartValue" SG_ 841 LFSideSensorObj09_LongPos 8191;
BA_ "GenSigSendType" SG_ 841 LFSideSensorObj09_LatVelVar 1;
BA_ "GenSigStartValue" SG_ 841 LFSideSensorObj09_LatVelVar 255;
BA_ "GenSigSendType" SG_ 841 LFSideSensorObj09_LatExtRtVar 1;
BA_ "GenSigStartValue" SG_ 841 LFSideSensorObj09_LatExtRtVar 255;
BA_ "GenSigSendType" SG_ 841 LFSideSensorObj09_ObjClassConf 1;
BA_ "GenSigStartValue" SG_ 841 LFSideSensorObj09_ObjClassConf 15;
BA_ "GenSigSendType" SG_ 841 LFSideSensorObj09_Height 1;
BA_ "GenSigStartValue" SG_ 841 LFSideSensorObj09_Height 255;
BA_ "GenSigSendType" SG_ 841 LFSideSensorObj09_LatVel 1;
BA_ "GenSigStartValue" SG_ 841 LFSideSensorObj09_LatVel 8191;
BA_ "GenSigSendType" SG_ 841 LFSideSensorObj09_ObjDynClass 1;
BA_ "GenSigStartValue" SG_ 841 LFSideSensorObj09_ObjDynClass 3;
BA_ "GenSigSendType" SG_ 841 LFSideSensorObj09_LongExtBack 1;
BA_ "GenSigStartValue" SG_ 841 LFSideSensorObj09_LongExtBack 1023;
BA_ "GenSigSendType" SG_ 841 LFSideSensorObj09_LatExtLeftVar 1;
BA_ "GenSigStartValue" SG_ 841 LFSideSensorObj09_LatExtLeftVar 255;
BA_ "GenSigSendType" SG_ 841 LFSideSensorObj09_HeadingVar 1;
BA_ "GenSigStartValue" SG_ 841 LFSideSensorObj09_HeadingVar 255;
BA_ "GenSigSendType" SG_ 841 LFSideSensorObj09_LatExtLeft 1;
BA_ "GenSigStartValue" SG_ 841 LFSideSensorObj09_LatExtLeft 127;
BA_ "GenSigSendType" SG_ 841 LFSideSensorObj09_LongAccVar 1;
BA_ "GenSigStartValue" SG_ 841 LFSideSensorObj09_LongAccVar 255;
BA_ "GenSigSendType" SG_ 841 LFSideSensorObj09_LifeTime 1;
BA_ "GenSigStartValue" SG_ 841 LFSideSensorObj09_LifeTime 65535;
BA_ "GenSigSendType" SG_ 841 LFSideSensorObj09_LongVel 1;
BA_ "GenSigStartValue" SG_ 841 LFSideSensorObj09_LongVel 8191;
BA_ "GenSigSendType" SG_ 841 LFSideSensorObj09_Heading 1;
BA_ "GenSigStartValue" SG_ 841 LFSideSensorObj09_Heading 2047;
BA_ "GenSigSendType" SG_ 841 LFSideSensorObj09_LatPosVar 1;
BA_ "GenSigStartValue" SG_ 841 LFSideSensorObj09_LatPosVar 255;
BA_ "GenSigSendType" SG_ 841 LFSideSensorObj09_ObjID 1;
BA_ "GenSigStartValue" SG_ 841 LFSideSensorObj09_ObjID 63;
BA_ "GenSigSendType" SG_ 841 LFSideSensorObj09_LatAccVar 1;
BA_ "GenSigStartValue" SG_ 841 LFSideSensorObj09_LatAccVar 255;
BA_ "GenSigSendType" SG_ 841 LFSideSensorObj09_LatExtRight 1;
BA_ "GenSigStartValue" SG_ 841 LFSideSensorObj09_LatExtRight 127;
BA_ "GenSigSendType" SG_ 841 LFSideSensorObj09_LongAcc 1;
BA_ "GenSigStartValue" SG_ 841 LFSideSensorObj09_LongAcc 511;
BA_ "GenSigSendType" SG_ 841 LFSideSensorObj09_LatAcc 1;
BA_ "GenSigStartValue" SG_ 841 LFSideSensorObj09_LatAcc 511;
BA_ "GenSigSendType" SG_ 841 LFSideSensorObj09_ObjClass 1;
BA_ "GenSigStartValue" SG_ 841 LFSideSensorObj09_ObjClass 15;
BA_ "GenSigSendType" SG_ 841 LFSideSensorObj09_ObstacleConf 1;
BA_ "GenSigStartValue" SG_ 841 LFSideSensorObj09_ObstacleConf 127;
BA_ "GenSigSendType" SG_ 840 LFSideSensorObj08_CoastIndex 1;
BA_ "GenSigStartValue" SG_ 840 LFSideSensorObj08_CoastIndex 31;
BA_ "GenSigSendType" SG_ 840 LFSideSensorObj08_LatExtLeftVar 1;
BA_ "GenSigStartValue" SG_ 840 LFSideSensorObj08_LatExtLeftVar 255;
BA_ "GenSigSendType" SG_ 840 LFSideSensorObj08_LongExtFront 1;
BA_ "GenSigStartValue" SG_ 840 LFSideSensorObj08_LongExtFront 1023;
BA_ "GenSigSendType" SG_ 840 LFSideSensorObj08_LatExtLeft 1;
BA_ "GenSigStartValue" SG_ 840 LFSideSensorObj08_LatExtLeft 127;
BA_ "GenSigSendType" SG_ 840 LFSideSensorObj08_LatAcc 1;
BA_ "GenSigStartValue" SG_ 840 LFSideSensorObj08_LatAcc 511;
BA_ "GenSigSendType" SG_ 840 LFSideSensorObj08_LongExtBkVar 1;
BA_ "GenSigStartValue" SG_ 840 LFSideSensorObj08_LongExtBkVar 255;
BA_ "GenSigSendType" SG_ 840 LFSideSensorObj08_LifeTime 1;
BA_ "GenSigStartValue" SG_ 840 LFSideSensorObj08_LifeTime 65535;
BA_ "GenSigSendType" SG_ 840 LFSideSensorObj08_LatPos 1;
BA_ "GenSigStartValue" SG_ 840 LFSideSensorObj08_LatPos 8191;
BA_ "GenSigSendType" SG_ 840 LFSideSensorObj08_ObjID 1;
BA_ "GenSigStartValue" SG_ 840 LFSideSensorObj08_ObjID 63;
BA_ "GenSigSendType" SG_ 840 LFSideSensorObj08_Prioritisation 1;
BA_ "GenSigStartValue" SG_ 840 LFSideSensorObj08_Prioritisation 3;
BA_ "GenSigSendType" SG_ 840 LFSideSensorObj08_ExistConf 1;
BA_ "GenSigStartValue" SG_ 840 LFSideSensorObj08_ExistConf 127;
BA_ "GenSigSendType" SG_ 840 LFSideSensorObj08_LongExtFrVar 1;
BA_ "GenSigStartValue" SG_ 840 LFSideSensorObj08_LongExtFrVar 255;
BA_ "GenSigSendType" SG_ 840 LFSideSensorObj08_MOISPrio 1;
BA_ "GenSigSendType" SG_ 840 LFSideSensorObj08_LongPosVar 1;
BA_ "GenSigStartValue" SG_ 840 LFSideSensorObj08_LongPosVar 255;
BA_ "GenSigSendType" SG_ 840 LFSideSensorObj08_LongVel 1;
BA_ "GenSigStartValue" SG_ 840 LFSideSensorObj08_LongVel 8191;
BA_ "GenSigSendType" SG_ 840 LFSideSensorObj08_TrackStatus 1;
BA_ "GenSigStartValue" SG_ 840 LFSideSensorObj08_TrackStatus 7;
BA_ "GenSigSendType" SG_ 840 LFSideSensorObj08_Counter 1;
BA_ "GenSigStartValue" SG_ 840 LFSideSensorObj08_Counter 255;
BA_ "GenSigSendType" SG_ 840 LFSideSensorObj08_CRC 1;
BA_ "GenSigStartValue" SG_ 840 LFSideSensorObj08_CRC 65535;
BA_ "E2EDataId" SG_ 840 LFSideSensorObj08_CRC 26;
BA_ "E2EDataLength" SG_ 840 LFSideSensorObj08_CRC 312;
BA_ "E2EProfile" SG_ 840 LFSideSensorObj08_CRC "P05";
BA_ "GenSigSendType" SG_ 840 LFSideSensorObj08_LatExtRight 1;
BA_ "GenSigStartValue" SG_ 840 LFSideSensorObj08_LatExtRight 127;
BA_ "GenSigSendType" SG_ 840 LFSideSensorObj08_LongVelVar 1;
BA_ "GenSigStartValue" SG_ 840 LFSideSensorObj08_LongVelVar 255;
BA_ "GenSigSendType" SG_ 840 LFSideSensorObj08_LongAcc 1;
BA_ "GenSigStartValue" SG_ 840 LFSideSensorObj08_LongAcc 511;
BA_ "GenSigSendType" SG_ 840 LFSideSensorObj08_Heading 1;
BA_ "GenSigStartValue" SG_ 840 LFSideSensorObj08_Heading 2047;
BA_ "GenSigSendType" SG_ 840 LFSideSensorObj08_LongExtBack 1;
BA_ "GenSigStartValue" SG_ 840 LFSideSensorObj08_LongExtBack 1023;
BA_ "GenSigSendType" SG_ 840 LFSideSensorObj08_LatExtRtVar 1;
BA_ "GenSigStartValue" SG_ 840 LFSideSensorObj08_LatExtRtVar 255;
BA_ "GenSigSendType" SG_ 840 LFSideSensorObj08_LatVelVar 1;
BA_ "GenSigStartValue" SG_ 840 LFSideSensorObj08_LatVelVar 255;
BA_ "GenSigSendType" SG_ 840 LFSideSensorObj08_HeadingVar 1;
BA_ "GenSigStartValue" SG_ 840 LFSideSensorObj08_HeadingVar 255;
BA_ "GenSigSendType" SG_ 840 LFSideSensorObj08_ObjClass 1;
BA_ "GenSigStartValue" SG_ 840 LFSideSensorObj08_ObjClass 15;
BA_ "GenSigSendType" SG_ 840 LFSideSensorObj08_ObjClassConf 1;
BA_ "GenSigStartValue" SG_ 840 LFSideSensorObj08_ObjClassConf 15;
BA_ "GenSigSendType" SG_ 840 LFSideSensorObj08_LatPosVar 1;
BA_ "GenSigStartValue" SG_ 840 LFSideSensorObj08_LatPosVar 255;
BA_ "GenSigSendType" SG_ 840 LFSideSensorObj08_LongPos 1;
BA_ "GenSigStartValue" SG_ 840 LFSideSensorObj08_LongPos 8191;
BA_ "GenSigSendType" SG_ 840 LFSideSensorObj08_LatAccVar 1;
BA_ "GenSigStartValue" SG_ 840 LFSideSensorObj08_LatAccVar 255;
BA_ "GenSigSendType" SG_ 840 LFSideSensorObj08_Height 1;
BA_ "GenSigStartValue" SG_ 840 LFSideSensorObj08_Height 255;
BA_ "GenSigSendType" SG_ 840 LFSideSensorObj08_TimeStamp 1;
BA_ "GenSigStartValue" SG_ 840 LFSideSensorObj08_TimeStamp 65535;
BA_ "GenSigSendType" SG_ 840 LFSideSensorObj08_LongAccVar 1;
BA_ "GenSigStartValue" SG_ 840 LFSideSensorObj08_LongAccVar 255;
BA_ "GenSigSendType" SG_ 840 LFSideSensorObj08_LatVel 1;
BA_ "GenSigStartValue" SG_ 840 LFSideSensorObj08_LatVel 8191;
BA_ "GenSigSendType" SG_ 840 LFSideSensorObj08_ObjDynClass 1;
BA_ "GenSigStartValue" SG_ 840 LFSideSensorObj08_ObjDynClass 3;
BA_ "GenSigSendType" SG_ 840 LFSideSensorObj08_ObstacleConf 1;
BA_ "GenSigStartValue" SG_ 840 LFSideSensorObj08_ObstacleConf 127;
BA_ "GenSigSendType" SG_ 839 LFSideSensorObj07_LatAcc 1;
BA_ "GenSigStartValue" SG_ 839 LFSideSensorObj07_LatAcc 511;
BA_ "GenSigSendType" SG_ 839 LFSideSensorObj07_LongPosVar 1;
BA_ "GenSigStartValue" SG_ 839 LFSideSensorObj07_LongPosVar 255;
BA_ "GenSigSendType" SG_ 839 LFSideSensorObj07_ObjClassConf 1;
BA_ "GenSigStartValue" SG_ 839 LFSideSensorObj07_ObjClassConf 15;
BA_ "GenSigSendType" SG_ 839 LFSideSensorObj07_LatPosVar 1;
BA_ "GenSigStartValue" SG_ 839 LFSideSensorObj07_LatPosVar 255;
BA_ "GenSigSendType" SG_ 839 LFSideSensorObj07_ExistConf 1;
BA_ "GenSigStartValue" SG_ 839 LFSideSensorObj07_ExistConf 127;
BA_ "GenSigSendType" SG_ 839 LFSideSensorObj07_LifeTime 1;
BA_ "GenSigStartValue" SG_ 839 LFSideSensorObj07_LifeTime 65535;
BA_ "GenSigSendType" SG_ 839 LFSideSensorObj07_ObstacleConf 1;
BA_ "GenSigStartValue" SG_ 839 LFSideSensorObj07_ObstacleConf 127;
BA_ "GenSigSendType" SG_ 839 LFSideSensorObj07_MOISPrio 1;
BA_ "GenSigSendType" SG_ 839 LFSideSensorObj07_ObjDynClass 1;
BA_ "GenSigStartValue" SG_ 839 LFSideSensorObj07_ObjDynClass 3;
BA_ "GenSigSendType" SG_ 839 LFSideSensorObj07_Height 1;
BA_ "GenSigStartValue" SG_ 839 LFSideSensorObj07_Height 255;
BA_ "GenSigSendType" SG_ 839 LFSideSensorObj07_HeadingVar 1;
BA_ "GenSigStartValue" SG_ 839 LFSideSensorObj07_HeadingVar 255;
BA_ "GenSigSendType" SG_ 839 LFSideSensorObj07_Heading 1;
BA_ "GenSigStartValue" SG_ 839 LFSideSensorObj07_Heading 2047;
BA_ "GenSigSendType" SG_ 839 LFSideSensorObj07_LatExtLeftVar 1;
BA_ "GenSigStartValue" SG_ 839 LFSideSensorObj07_LatExtLeftVar 255;
BA_ "GenSigSendType" SG_ 839 LFSideSensorObj07_LatVel 1;
BA_ "GenSigStartValue" SG_ 839 LFSideSensorObj07_LatVel 8191;
BA_ "GenSigSendType" SG_ 839 LFSideSensorObj07_Counter 1;
BA_ "GenSigStartValue" SG_ 839 LFSideSensorObj07_Counter 255;
BA_ "GenSigSendType" SG_ 839 LFSideSensorObj07_TrackStatus 1;
BA_ "GenSigStartValue" SG_ 839 LFSideSensorObj07_TrackStatus 7;
BA_ "GenSigSendType" SG_ 839 LFSideSensorObj07_LongExtBack 1;
BA_ "GenSigStartValue" SG_ 839 LFSideSensorObj07_LongExtBack 1023;
BA_ "GenSigSendType" SG_ 839 LFSideSensorObj07_LatVelVar 1;
BA_ "GenSigStartValue" SG_ 839 LFSideSensorObj07_LatVelVar 255;
BA_ "GenSigSendType" SG_ 839 LFSideSensorObj07_TimeStamp 1;
BA_ "GenSigStartValue" SG_ 839 LFSideSensorObj07_TimeStamp 65535;
BA_ "GenSigSendType" SG_ 839 LFSideSensorObj07_LongAccVar 1;
BA_ "GenSigStartValue" SG_ 839 LFSideSensorObj07_LongAccVar 255;
BA_ "GenSigSendType" SG_ 839 LFSideSensorObj07_LongVelVar 1;
BA_ "GenSigStartValue" SG_ 839 LFSideSensorObj07_LongVelVar 255;
BA_ "GenSigSendType" SG_ 839 LFSideSensorObj07_LatExtLeft 1;
BA_ "GenSigStartValue" SG_ 839 LFSideSensorObj07_LatExtLeft 127;
BA_ "GenSigSendType" SG_ 839 LFSideSensorObj07_LongPos 1;
BA_ "GenSigStartValue" SG_ 839 LFSideSensorObj07_LongPos 8191;
BA_ "GenSigSendType" SG_ 839 LFSideSensorObj07_LongVel 1;
BA_ "GenSigStartValue" SG_ 839 LFSideSensorObj07_LongVel 8191;
BA_ "GenSigSendType" SG_ 839 LFSideSensorObj07_LongExtFrVar 1;
BA_ "GenSigStartValue" SG_ 839 LFSideSensorObj07_LongExtFrVar 255;
BA_ "GenSigSendType" SG_ 839 LFSideSensorObj07_LatExtRtVar 1;
BA_ "GenSigStartValue" SG_ 839 LFSideSensorObj07_LatExtRtVar 255;
BA_ "GenSigSendType" SG_ 839 LFSideSensorObj07_LatAccVar 1;
BA_ "GenSigStartValue" SG_ 839 LFSideSensorObj07_LatAccVar 255;
BA_ "GenSigSendType" SG_ 839 LFSideSensorObj07_Prioritisation 1;
BA_ "GenSigStartValue" SG_ 839 LFSideSensorObj07_Prioritisation 3;
BA_ "GenSigSendType" SG_ 839 LFSideSensorObj07_ObjClass 1;
BA_ "GenSigStartValue" SG_ 839 LFSideSensorObj07_ObjClass 15;
BA_ "GenSigSendType" SG_ 839 LFSideSensorObj07_CoastIndex 1;
BA_ "GenSigStartValue" SG_ 839 LFSideSensorObj07_CoastIndex 31;
BA_ "GenSigSendType" SG_ 839 LFSideSensorObj07_LatPos 1;
BA_ "GenSigStartValue" SG_ 839 LFSideSensorObj07_LatPos 8191;
BA_ "GenSigSendType" SG_ 839 LFSideSensorObj07_LongExtBkVar 1;
BA_ "GenSigStartValue" SG_ 839 LFSideSensorObj07_LongExtBkVar 255;
BA_ "GenSigSendType" SG_ 839 LFSideSensorObj07_ObjID 1;
BA_ "GenSigStartValue" SG_ 839 LFSideSensorObj07_ObjID 63;
BA_ "GenSigSendType" SG_ 839 LFSideSensorObj07_LongExtFront 1;
BA_ "GenSigStartValue" SG_ 839 LFSideSensorObj07_LongExtFront 1023;
BA_ "GenSigSendType" SG_ 839 LFSideSensorObj07_CRC 1;
BA_ "GenSigStartValue" SG_ 839 LFSideSensorObj07_CRC 65535;
BA_ "E2EDataId" SG_ 839 LFSideSensorObj07_CRC 25;
BA_ "E2EDataLength" SG_ 839 LFSideSensorObj07_CRC 312;
BA_ "E2EProfile" SG_ 839 LFSideSensorObj07_CRC "P05";
BA_ "GenSigSendType" SG_ 839 LFSideSensorObj07_LatExtRight 1;
BA_ "GenSigStartValue" SG_ 839 LFSideSensorObj07_LatExtRight 127;
BA_ "GenSigSendType" SG_ 839 LFSideSensorObj07_LongAcc 1;
BA_ "GenSigStartValue" SG_ 839 LFSideSensorObj07_LongAcc 511;
BA_ "GenSigSendType" SG_ 838 LFSideSensorObj06_MOISPrio 1;
BA_ "GenSigSendType" SG_ 838 LFSideSensorObj06_ObstacleConf 1;
BA_ "GenSigStartValue" SG_ 838 LFSideSensorObj06_ObstacleConf 127;
BA_ "GenSigSendType" SG_ 838 LFSideSensorObj06_LongVel 1;
BA_ "GenSigStartValue" SG_ 838 LFSideSensorObj06_LongVel 8191;
BA_ "GenSigSendType" SG_ 838 LFSideSensorObj06_LongExtFront 1;
BA_ "GenSigStartValue" SG_ 838 LFSideSensorObj06_LongExtFront 1023;
BA_ "GenSigSendType" SG_ 838 LFSideSensorObj06_Counter 1;
BA_ "GenSigStartValue" SG_ 838 LFSideSensorObj06_Counter 255;
BA_ "GenSigSendType" SG_ 838 LFSideSensorObj06_LongVelVar 1;
BA_ "GenSigStartValue" SG_ 838 LFSideSensorObj06_LongVelVar 255;
BA_ "GenSigSendType" SG_ 838 LFSideSensorObj06_LongPos 1;
BA_ "GenSigStartValue" SG_ 838 LFSideSensorObj06_LongPos 8191;
BA_ "GenSigSendType" SG_ 838 LFSideSensorObj06_LongExtFrVar 1;
BA_ "GenSigStartValue" SG_ 838 LFSideSensorObj06_LongExtFrVar 255;
BA_ "GenSigSendType" SG_ 838 LFSideSensorObj06_LatExtLeft 1;
BA_ "GenSigStartValue" SG_ 838 LFSideSensorObj06_LatExtLeft 127;
BA_ "GenSigSendType" SG_ 838 LFSideSensorObj06_Prioritisation 1;
BA_ "GenSigStartValue" SG_ 838 LFSideSensorObj06_Prioritisation 3;
BA_ "GenSigSendType" SG_ 838 LFSideSensorObj06_CoastIndex 1;
BA_ "GenSigStartValue" SG_ 838 LFSideSensorObj06_CoastIndex 31;
BA_ "GenSigSendType" SG_ 838 LFSideSensorObj06_HeadingVar 1;
BA_ "GenSigStartValue" SG_ 838 LFSideSensorObj06_HeadingVar 255;
BA_ "GenSigSendType" SG_ 838 LFSideSensorObj06_LatAcc 1;
BA_ "GenSigStartValue" SG_ 838 LFSideSensorObj06_LatAcc 511;
BA_ "GenSigSendType" SG_ 838 LFSideSensorObj06_LongExtBkVar 1;
BA_ "GenSigStartValue" SG_ 838 LFSideSensorObj06_LongExtBkVar 255;
BA_ "GenSigSendType" SG_ 838 LFSideSensorObj06_LongAccVar 1;
BA_ "GenSigStartValue" SG_ 838 LFSideSensorObj06_LongAccVar 255;
BA_ "GenSigSendType" SG_ 838 LFSideSensorObj06_LongExtBack 1;
BA_ "GenSigStartValue" SG_ 838 LFSideSensorObj06_LongExtBack 1023;
BA_ "GenSigSendType" SG_ 838 LFSideSensorObj06_Heading 1;
BA_ "GenSigStartValue" SG_ 838 LFSideSensorObj06_Heading 2047;
BA_ "GenSigSendType" SG_ 838 LFSideSensorObj06_ExistConf 1;
BA_ "GenSigStartValue" SG_ 838 LFSideSensorObj06_ExistConf 127;
BA_ "GenSigSendType" SG_ 838 LFSideSensorObj06_LatVelVar 1;
BA_ "GenSigStartValue" SG_ 838 LFSideSensorObj06_LatVelVar 255;
BA_ "GenSigSendType" SG_ 838 LFSideSensorObj06_LifeTime 1;
BA_ "GenSigStartValue" SG_ 838 LFSideSensorObj06_LifeTime 65535;
BA_ "GenSigSendType" SG_ 838 LFSideSensorObj06_LatVel 1;
BA_ "GenSigStartValue" SG_ 838 LFSideSensorObj06_LatVel 8191;
BA_ "GenSigSendType" SG_ 838 LFSideSensorObj06_TimeStamp 1;
BA_ "GenSigStartValue" SG_ 838 LFSideSensorObj06_TimeStamp 65535;
BA_ "GenSigSendType" SG_ 838 LFSideSensorObj06_ObjDynClass 1;
BA_ "GenSigStartValue" SG_ 838 LFSideSensorObj06_ObjDynClass 3;
BA_ "GenSigSendType" SG_ 838 LFSideSensorObj06_ObjClass 1;
BA_ "GenSigStartValue" SG_ 838 LFSideSensorObj06_ObjClass 15;
BA_ "GenSigSendType" SG_ 838 LFSideSensorObj06_TrackStatus 1;
BA_ "GenSigStartValue" SG_ 838 LFSideSensorObj06_TrackStatus 7;
BA_ "GenSigSendType" SG_ 838 LFSideSensorObj06_LatExtLeftVar 1;
BA_ "GenSigStartValue" SG_ 838 LFSideSensorObj06_LatExtLeftVar 255;
BA_ "GenSigSendType" SG_ 838 LFSideSensorObj06_ObjClassConf 1;
BA_ "GenSigStartValue" SG_ 838 LFSideSensorObj06_ObjClassConf 15;
BA_ "GenSigSendType" SG_ 838 LFSideSensorObj06_LongPosVar 1;
BA_ "GenSigStartValue" SG_ 838 LFSideSensorObj06_LongPosVar 255;
BA_ "GenSigSendType" SG_ 838 LFSideSensorObj06_LatExtRtVar 1;
BA_ "GenSigStartValue" SG_ 838 LFSideSensorObj06_LatExtRtVar 255;
BA_ "GenSigSendType" SG_ 838 LFSideSensorObj06_CRC 1;
BA_ "GenSigStartValue" SG_ 838 LFSideSensorObj06_CRC 65535;
BA_ "E2EDataId" SG_ 838 LFSideSensorObj06_CRC 24;
BA_ "E2EDataLength" SG_ 838 LFSideSensorObj06_CRC 312;
BA_ "E2EProfile" SG_ 838 LFSideSensorObj06_CRC "P05";
BA_ "GenSigSendType" SG_ 838 LFSideSensorObj06_LatPosVar 1;
BA_ "GenSigStartValue" SG_ 838 LFSideSensorObj06_LatPosVar 255;
BA_ "GenSigSendType" SG_ 838 LFSideSensorObj06_LatPos 1;
BA_ "GenSigStartValue" SG_ 838 LFSideSensorObj06_LatPos 8191;
BA_ "GenSigSendType" SG_ 838 LFSideSensorObj06_ObjID 1;
BA_ "GenSigStartValue" SG_ 838 LFSideSensorObj06_ObjID 63;
BA_ "GenSigSendType" SG_ 838 LFSideSensorObj06_LongAcc 1;
BA_ "GenSigStartValue" SG_ 838 LFSideSensorObj06_LongAcc 511;
BA_ "GenSigSendType" SG_ 838 LFSideSensorObj06_LatExtRight 1;
BA_ "GenSigStartValue" SG_ 838 LFSideSensorObj06_LatExtRight 127;
BA_ "GenSigSendType" SG_ 838 LFSideSensorObj06_LatAccVar 1;
BA_ "GenSigStartValue" SG_ 838 LFSideSensorObj06_LatAccVar 255;
BA_ "GenSigSendType" SG_ 838 LFSideSensorObj06_Height 1;
BA_ "GenSigStartValue" SG_ 838 LFSideSensorObj06_Height 255;
BA_ "GenSigSendType" SG_ 837 LFSideSensorObj05_Height 1;
BA_ "GenSigStartValue" SG_ 837 LFSideSensorObj05_Height 255;
BA_ "GenSigSendType" SG_ 837 LFSideSensorObj05_LatPosVar 1;
BA_ "GenSigStartValue" SG_ 837 LFSideSensorObj05_LatPosVar 255;
BA_ "GenSigSendType" SG_ 837 LFSideSensorObj05_MOISPrio 1;
BA_ "GenSigSendType" SG_ 837 LFSideSensorObj05_LatExtLeftVar 1;
BA_ "GenSigStartValue" SG_ 837 LFSideSensorObj05_LatExtLeftVar 255;
BA_ "GenSigSendType" SG_ 837 LFSideSensorObj05_LongPosVar 1;
BA_ "GenSigStartValue" SG_ 837 LFSideSensorObj05_LongPosVar 255;
BA_ "GenSigSendType" SG_ 837 LFSideSensorObj05_LatAccVar 1;
BA_ "GenSigStartValue" SG_ 837 LFSideSensorObj05_LatAccVar 255;
BA_ "GenSigSendType" SG_ 837 LFSideSensorObj05_LongExtBkVar 1;
BA_ "GenSigStartValue" SG_ 837 LFSideSensorObj05_LongExtBkVar 255;
BA_ "GenSigSendType" SG_ 837 LFSideSensorObj05_LongAcc 1;
BA_ "GenSigStartValue" SG_ 837 LFSideSensorObj05_LongAcc 511;
BA_ "GenSigSendType" SG_ 837 LFSideSensorObj05_LatExtRight 1;
BA_ "GenSigStartValue" SG_ 837 LFSideSensorObj05_LatExtRight 127;
BA_ "GenSigSendType" SG_ 837 LFSideSensorObj05_LatExtLeft 1;
BA_ "GenSigStartValue" SG_ 837 LFSideSensorObj05_LatExtLeft 127;
BA_ "GenSigSendType" SG_ 837 LFSideSensorObj05_LongExtFront 1;
BA_ "GenSigStartValue" SG_ 837 LFSideSensorObj05_LongExtFront 1023;
BA_ "GenSigSendType" SG_ 837 LFSideSensorObj05_ObjClassConf 1;
BA_ "GenSigStartValue" SG_ 837 LFSideSensorObj05_ObjClassConf 15;
BA_ "GenSigSendType" SG_ 837 LFSideSensorObj05_ObjID 1;
BA_ "GenSigStartValue" SG_ 837 LFSideSensorObj05_ObjID 63;
BA_ "GenSigSendType" SG_ 837 LFSideSensorObj05_LatPos 1;
BA_ "GenSigStartValue" SG_ 837 LFSideSensorObj05_LatPos 8191;
BA_ "GenSigSendType" SG_ 837 LFSideSensorObj05_LongExtBack 1;
BA_ "GenSigStartValue" SG_ 837 LFSideSensorObj05_LongExtBack 1023;
BA_ "GenSigSendType" SG_ 837 LFSideSensorObj05_Heading 1;
BA_ "GenSigStartValue" SG_ 837 LFSideSensorObj05_Heading 2047;
BA_ "GenSigSendType" SG_ 837 LFSideSensorObj05_CRC 1;
BA_ "GenSigStartValue" SG_ 837 LFSideSensorObj05_CRC 65535;
BA_ "E2EDataId" SG_ 837 LFSideSensorObj05_CRC 23;
BA_ "E2EDataLength" SG_ 837 LFSideSensorObj05_CRC 312;
BA_ "E2EProfile" SG_ 837 LFSideSensorObj05_CRC "P05";
BA_ "GenSigSendType" SG_ 837 LFSideSensorObj05_LongAccVar 1;
BA_ "GenSigStartValue" SG_ 837 LFSideSensorObj05_LongAccVar 255;
BA_ "GenSigSendType" SG_ 837 LFSideSensorObj05_LatExtRtVar 1;
BA_ "GenSigStartValue" SG_ 837 LFSideSensorObj05_LatExtRtVar 255;
BA_ "GenSigSendType" SG_ 837 LFSideSensorObj05_ExistConf 1;
BA_ "GenSigStartValue" SG_ 837 LFSideSensorObj05_ExistConf 127;
BA_ "GenSigSendType" SG_ 837 LFSideSensorObj05_LatAcc 1;
BA_ "GenSigStartValue" SG_ 837 LFSideSensorObj05_LatAcc 511;
BA_ "GenSigSendType" SG_ 837 LFSideSensorObj05_CoastIndex 1;
BA_ "GenSigStartValue" SG_ 837 LFSideSensorObj05_CoastIndex 31;
BA_ "GenSigSendType" SG_ 837 LFSideSensorObj05_LongPos 1;
BA_ "GenSigStartValue" SG_ 837 LFSideSensorObj05_LongPos 8191;
BA_ "GenSigSendType" SG_ 837 LFSideSensorObj05_LongVel 1;
BA_ "GenSigStartValue" SG_ 837 LFSideSensorObj05_LongVel 8191;
BA_ "GenSigSendType" SG_ 837 LFSideSensorObj05_LongVelVar 1;
BA_ "GenSigStartValue" SG_ 837 LFSideSensorObj05_LongVelVar 255;
BA_ "GenSigSendType" SG_ 837 LFSideSensorObj05_TrackStatus 1;
BA_ "GenSigStartValue" SG_ 837 LFSideSensorObj05_TrackStatus 7;
BA_ "GenSigSendType" SG_ 837 LFSideSensorObj05_LifeTime 1;
BA_ "GenSigStartValue" SG_ 837 LFSideSensorObj05_LifeTime 65535;
BA_ "GenSigSendType" SG_ 837 LFSideSensorObj05_ObjClass 1;
BA_ "GenSigStartValue" SG_ 837 LFSideSensorObj05_ObjClass 15;
BA_ "GenSigSendType" SG_ 837 LFSideSensorObj05_HeadingVar 1;
BA_ "GenSigStartValue" SG_ 837 LFSideSensorObj05_HeadingVar 255;
BA_ "GenSigSendType" SG_ 837 LFSideSensorObj05_Prioritisation 1;
BA_ "GenSigStartValue" SG_ 837 LFSideSensorObj05_Prioritisation 3;
BA_ "GenSigSendType" SG_ 837 LFSideSensorObj05_Counter 1;
BA_ "GenSigStartValue" SG_ 837 LFSideSensorObj05_Counter 255;
BA_ "GenSigSendType" SG_ 837 LFSideSensorObj05_LatVel 1;
BA_ "GenSigStartValue" SG_ 837 LFSideSensorObj05_LatVel 8191;
BA_ "GenSigSendType" SG_ 837 LFSideSensorObj05_LongExtFrVar 1;
BA_ "GenSigStartValue" SG_ 837 LFSideSensorObj05_LongExtFrVar 255;
BA_ "GenSigSendType" SG_ 837 LFSideSensorObj05_ObjDynClass 1;
BA_ "GenSigStartValue" SG_ 837 LFSideSensorObj05_ObjDynClass 3;
BA_ "GenSigSendType" SG_ 837 LFSideSensorObj05_TimeStamp 1;
BA_ "GenSigStartValue" SG_ 837 LFSideSensorObj05_TimeStamp 65535;
BA_ "GenSigSendType" SG_ 837 LFSideSensorObj05_ObstacleConf 1;
BA_ "GenSigStartValue" SG_ 837 LFSideSensorObj05_ObstacleConf 127;
BA_ "GenSigSendType" SG_ 837 LFSideSensorObj05_LatVelVar 1;
BA_ "GenSigStartValue" SG_ 837 LFSideSensorObj05_LatVelVar 255;
BA_ "GenSigSendType" SG_ 836 LFSideSensorObj04_TrackStatus 1;
BA_ "GenSigStartValue" SG_ 836 LFSideSensorObj04_TrackStatus 7;
BA_ "GenSigSendType" SG_ 836 LFSideSensorObj04_LongAcc 1;
BA_ "GenSigStartValue" SG_ 836 LFSideSensorObj04_LongAcc 511;
BA_ "GenSigSendType" SG_ 836 LFSideSensorObj04_LatExtRight 1;
BA_ "GenSigStartValue" SG_ 836 LFSideSensorObj04_LatExtRight 127;
BA_ "GenSigSendType" SG_ 836 LFSideSensorObj04_Heading 1;
BA_ "GenSigStartValue" SG_ 836 LFSideSensorObj04_Heading 2047;
BA_ "GenSigSendType" SG_ 836 LFSideSensorObj04_ObjDynClass 1;
BA_ "GenSigStartValue" SG_ 836 LFSideSensorObj04_ObjDynClass 3;
BA_ "GenSigSendType" SG_ 836 LFSideSensorObj04_CRC 1;
BA_ "GenSigStartValue" SG_ 836 LFSideSensorObj04_CRC 65535;
BA_ "E2EDataId" SG_ 836 LFSideSensorObj04_CRC 22;
BA_ "E2EDataLength" SG_ 836 LFSideSensorObj04_CRC 312;
BA_ "E2EProfile" SG_ 836 LFSideSensorObj04_CRC "P05";
BA_ "GenSigSendType" SG_ 836 LFSideSensorObj04_ExistConf 1;
BA_ "GenSigStartValue" SG_ 836 LFSideSensorObj04_ExistConf 127;
BA_ "GenSigSendType" SG_ 836 LFSideSensorObj04_LongAccVar 1;
BA_ "GenSigStartValue" SG_ 836 LFSideSensorObj04_LongAccVar 255;
BA_ "GenSigSendType" SG_ 836 LFSideSensorObj04_TimeStamp 1;
BA_ "GenSigStartValue" SG_ 836 LFSideSensorObj04_TimeStamp 65535;
BA_ "GenSigSendType" SG_ 836 LFSideSensorObj04_Counter 1;
BA_ "GenSigStartValue" SG_ 836 LFSideSensorObj04_Counter 255;
BA_ "GenSigSendType" SG_ 836 LFSideSensorObj04_LatPos 1;
BA_ "GenSigStartValue" SG_ 836 LFSideSensorObj04_LatPos 8191;
BA_ "GenSigSendType" SG_ 836 LFSideSensorObj04_CoastIndex 1;
BA_ "GenSigStartValue" SG_ 836 LFSideSensorObj04_CoastIndex 31;
BA_ "GenSigSendType" SG_ 836 LFSideSensorObj04_LongPos 1;
BA_ "GenSigStartValue" SG_ 836 LFSideSensorObj04_LongPos 8191;
BA_ "GenSigSendType" SG_ 836 LFSideSensorObj04_LongExtBkVar 1;
BA_ "GenSigStartValue" SG_ 836 LFSideSensorObj04_LongExtBkVar 255;
BA_ "GenSigSendType" SG_ 836 LFSideSensorObj04_LatVelVar 1;
BA_ "GenSigStartValue" SG_ 836 LFSideSensorObj04_LatVelVar 255;
BA_ "GenSigSendType" SG_ 836 LFSideSensorObj04_LatAccVar 1;
BA_ "GenSigStartValue" SG_ 836 LFSideSensorObj04_LatAccVar 255;
BA_ "GenSigSendType" SG_ 836 LFSideSensorObj04_LifeTime 1;
BA_ "GenSigStartValue" SG_ 836 LFSideSensorObj04_LifeTime 65535;
BA_ "GenSigSendType" SG_ 836 LFSideSensorObj04_LongExtFront 1;
BA_ "GenSigStartValue" SG_ 836 LFSideSensorObj04_LongExtFront 1023;
BA_ "GenSigSendType" SG_ 836 LFSideSensorObj04_Prioritisation 1;
BA_ "GenSigStartValue" SG_ 836 LFSideSensorObj04_Prioritisation 3;
BA_ "GenSigSendType" SG_ 836 LFSideSensorObj04_ObjID 1;
BA_ "GenSigStartValue" SG_ 836 LFSideSensorObj04_ObjID 63;
BA_ "GenSigSendType" SG_ 836 LFSideSensorObj04_LongPosVar 1;
BA_ "GenSigStartValue" SG_ 836 LFSideSensorObj04_LongPosVar 255;
BA_ "GenSigSendType" SG_ 836 LFSideSensorObj04_LongVel 1;
BA_ "GenSigStartValue" SG_ 836 LFSideSensorObj04_LongVel 8191;
BA_ "GenSigSendType" SG_ 836 LFSideSensorObj04_ObjClassConf 1;
BA_ "GenSigStartValue" SG_ 836 LFSideSensorObj04_ObjClassConf 15;
BA_ "GenSigSendType" SG_ 836 LFSideSensorObj04_LatExtLeft 1;
BA_ "GenSigStartValue" SG_ 836 LFSideSensorObj04_LatExtLeft 127;
BA_ "GenSigSendType" SG_ 836 LFSideSensorObj04_LatVel 1;
BA_ "GenSigStartValue" SG_ 836 LFSideSensorObj04_LatVel 8191;
BA_ "GenSigSendType" SG_ 836 LFSideSensorObj04_LongExtBack 1;
BA_ "GenSigStartValue" SG_ 836 LFSideSensorObj04_LongExtBack 1023;
BA_ "GenSigSendType" SG_ 836 LFSideSensorObj04_LatAcc 1;
BA_ "GenSigStartValue" SG_ 836 LFSideSensorObj04_LatAcc 511;
BA_ "GenSigSendType" SG_ 836 LFSideSensorObj04_MOISPrio 1;
BA_ "GenSigSendType" SG_ 836 LFSideSensorObj04_ObstacleConf 1;
BA_ "GenSigStartValue" SG_ 836 LFSideSensorObj04_ObstacleConf 127;
BA_ "GenSigSendType" SG_ 836 LFSideSensorObj04_LatPosVar 1;
BA_ "GenSigStartValue" SG_ 836 LFSideSensorObj04_LatPosVar 255;
BA_ "GenSigSendType" SG_ 836 LFSideSensorObj04_HeadingVar 1;
BA_ "GenSigStartValue" SG_ 836 LFSideSensorObj04_HeadingVar 255;
BA_ "GenSigSendType" SG_ 836 LFSideSensorObj04_LongExtFrVar 1;
BA_ "GenSigStartValue" SG_ 836 LFSideSensorObj04_LongExtFrVar 255;
BA_ "GenSigSendType" SG_ 836 LFSideSensorObj04_LatExtLeftVar 1;
BA_ "GenSigStartValue" SG_ 836 LFSideSensorObj04_LatExtLeftVar 255;
BA_ "GenSigSendType" SG_ 836 LFSideSensorObj04_Height 1;
BA_ "GenSigStartValue" SG_ 836 LFSideSensorObj04_Height 255;
BA_ "GenSigSendType" SG_ 836 LFSideSensorObj04_LongVelVar 1;
BA_ "GenSigStartValue" SG_ 836 LFSideSensorObj04_LongVelVar 255;
BA_ "GenSigSendType" SG_ 836 LFSideSensorObj04_ObjClass 1;
BA_ "GenSigStartValue" SG_ 836 LFSideSensorObj04_ObjClass 15;
BA_ "GenSigSendType" SG_ 836 LFSideSensorObj04_LatExtRtVar 1;
BA_ "GenSigStartValue" SG_ 836 LFSideSensorObj04_LatExtRtVar 255;
BA_ "GenSigSendType" SG_ 835 LFSideSensorObj03_ObjDynClass 1;
BA_ "GenSigStartValue" SG_ 835 LFSideSensorObj03_ObjDynClass 3;
BA_ "GenSigSendType" SG_ 835 LFSideSensorObj03_TrackStatus 1;
BA_ "GenSigStartValue" SG_ 835 LFSideSensorObj03_TrackStatus 7;
BA_ "GenSigSendType" SG_ 835 LFSideSensorObj03_Counter 1;
BA_ "GenSigStartValue" SG_ 835 LFSideSensorObj03_Counter 255;
BA_ "GenSigSendType" SG_ 835 LFSideSensorObj03_LatVel 1;
BA_ "GenSigStartValue" SG_ 835 LFSideSensorObj03_LatVel 8191;
BA_ "GenSigSendType" SG_ 835 LFSideSensorObj03_LatVelVar 1;
BA_ "GenSigStartValue" SG_ 835 LFSideSensorObj03_LatVelVar 255;
BA_ "GenSigSendType" SG_ 835 LFSideSensorObj03_ExistConf 1;
BA_ "GenSigStartValue" SG_ 835 LFSideSensorObj03_ExistConf 127;
BA_ "GenSigSendType" SG_ 835 LFSideSensorObj03_ObjClass 1;
BA_ "GenSigStartValue" SG_ 835 LFSideSensorObj03_ObjClass 15;
BA_ "GenSigSendType" SG_ 835 LFSideSensorObj03_ObstacleConf 1;
BA_ "GenSigStartValue" SG_ 835 LFSideSensorObj03_ObstacleConf 127;
BA_ "GenSigSendType" SG_ 835 LFSideSensorObj03_LongAcc 1;
BA_ "GenSigStartValue" SG_ 835 LFSideSensorObj03_LongAcc 511;
BA_ "GenSigSendType" SG_ 835 LFSideSensorObj03_LatAccVar 1;
BA_ "GenSigStartValue" SG_ 835 LFSideSensorObj03_LatAccVar 255;
BA_ "GenSigSendType" SG_ 835 LFSideSensorObj03_CRC 1;
BA_ "GenSigStartValue" SG_ 835 LFSideSensorObj03_CRC 65535;
BA_ "E2EDataId" SG_ 835 LFSideSensorObj03_CRC 21;
BA_ "E2EDataLength" SG_ 835 LFSideSensorObj03_CRC 312;
BA_ "E2EProfile" SG_ 835 LFSideSensorObj03_CRC "P05";
BA_ "GenSigSendType" SG_ 835 LFSideSensorObj03_MOISPrio 1;
BA_ "GenSigSendType" SG_ 835 LFSideSensorObj03_ObjClassConf 1;
BA_ "GenSigStartValue" SG_ 835 LFSideSensorObj03_ObjClassConf 15;
BA_ "GenSigSendType" SG_ 835 LFSideSensorObj03_LongPos 1;
BA_ "GenSigStartValue" SG_ 835 LFSideSensorObj03_LongPos 8191;
BA_ "GenSigSendType" SG_ 835 LFSideSensorObj03_LatPosVar 1;
BA_ "GenSigStartValue" SG_ 835 LFSideSensorObj03_LatPosVar 255;
BA_ "GenSigSendType" SG_ 835 LFSideSensorObj03_ObjID 1;
BA_ "GenSigStartValue" SG_ 835 LFSideSensorObj03_ObjID 63;
BA_ "GenSigSendType" SG_ 835 LFSideSensorObj03_LongVel 1;
BA_ "GenSigStartValue" SG_ 835 LFSideSensorObj03_LongVel 8191;
BA_ "GenSigSendType" SG_ 835 LFSideSensorObj03_Height 1;
BA_ "GenSigStartValue" SG_ 835 LFSideSensorObj03_Height 255;
BA_ "GenSigSendType" SG_ 835 LFSideSensorObj03_LatExtLeftVar 1;
BA_ "GenSigStartValue" SG_ 835 LFSideSensorObj03_LatExtLeftVar 255;
BA_ "GenSigSendType" SG_ 835 LFSideSensorObj03_Prioritisation 1;
BA_ "GenSigStartValue" SG_ 835 LFSideSensorObj03_Prioritisation 3;
BA_ "GenSigSendType" SG_ 835 LFSideSensorObj03_HeadingVar 1;
BA_ "GenSigStartValue" SG_ 835 LFSideSensorObj03_HeadingVar 255;
BA_ "GenSigSendType" SG_ 835 LFSideSensorObj03_LifeTime 1;
BA_ "GenSigStartValue" SG_ 835 LFSideSensorObj03_LifeTime 65535;
BA_ "GenSigSendType" SG_ 835 LFSideSensorObj03_LatExtLeft 1;
BA_ "GenSigStartValue" SG_ 835 LFSideSensorObj03_LatExtLeft 127;
BA_ "GenSigSendType" SG_ 835 LFSideSensorObj03_Heading 1;
BA_ "GenSigStartValue" SG_ 835 LFSideSensorObj03_Heading 2047;
BA_ "GenSigSendType" SG_ 835 LFSideSensorObj03_LongPosVar 1;
BA_ "GenSigStartValue" SG_ 835 LFSideSensorObj03_LongPosVar 255;
BA_ "GenSigSendType" SG_ 835 LFSideSensorObj03_LongExtFrVar 1;
BA_ "GenSigStartValue" SG_ 835 LFSideSensorObj03_LongExtFrVar 255;
BA_ "GenSigSendType" SG_ 835 LFSideSensorObj03_LongExtBack 1;
BA_ "GenSigStartValue" SG_ 835 LFSideSensorObj03_LongExtBack 1023;
BA_ "GenSigSendType" SG_ 835 LFSideSensorObj03_LatExtRtVar 1;
BA_ "GenSigStartValue" SG_ 835 LFSideSensorObj03_LatExtRtVar 255;
BA_ "GenSigSendType" SG_ 835 LFSideSensorObj03_TimeStamp 1;
BA_ "GenSigStartValue" SG_ 835 LFSideSensorObj03_TimeStamp 65535;
BA_ "GenSigSendType" SG_ 835 LFSideSensorObj03_LongExtBkVar 1;
BA_ "GenSigStartValue" SG_ 835 LFSideSensorObj03_LongExtBkVar 255;
BA_ "GenSigSendType" SG_ 835 LFSideSensorObj03_LatAcc 1;
BA_ "GenSigStartValue" SG_ 835 LFSideSensorObj03_LatAcc 511;
BA_ "GenSigSendType" SG_ 835 LFSideSensorObj03_LatPos 1;
BA_ "GenSigStartValue" SG_ 835 LFSideSensorObj03_LatPos 8191;
BA_ "GenSigSendType" SG_ 835 LFSideSensorObj03_LongVelVar 1;
BA_ "GenSigStartValue" SG_ 835 LFSideSensorObj03_LongVelVar 255;
BA_ "GenSigSendType" SG_ 835 LFSideSensorObj03_CoastIndex 1;
BA_ "GenSigStartValue" SG_ 835 LFSideSensorObj03_CoastIndex 31;
BA_ "GenSigSendType" SG_ 835 LFSideSensorObj03_LatExtRight 1;
BA_ "GenSigStartValue" SG_ 835 LFSideSensorObj03_LatExtRight 127;
BA_ "GenSigSendType" SG_ 835 LFSideSensorObj03_LongExtFront 1;
BA_ "GenSigStartValue" SG_ 835 LFSideSensorObj03_LongExtFront 1023;
BA_ "GenSigSendType" SG_ 835 LFSideSensorObj03_LongAccVar 1;
BA_ "GenSigStartValue" SG_ 835 LFSideSensorObj03_LongAccVar 255;
BA_ "GenSigSendType" SG_ 834 LFSideSensorObj02_LatVelVar 1;
BA_ "GenSigStartValue" SG_ 834 LFSideSensorObj02_LatVelVar 255;
BA_ "GenSigSendType" SG_ 834 LFSideSensorObj02_LatExtLeftVar 1;
BA_ "GenSigStartValue" SG_ 834 LFSideSensorObj02_LatExtLeftVar 255;
BA_ "GenSigSendType" SG_ 834 LFSideSensorObj02_ObstacleConf 1;
BA_ "GenSigStartValue" SG_ 834 LFSideSensorObj02_ObstacleConf 127;
BA_ "GenSigSendType" SG_ 834 LFSideSensorObj02_LatExtRtVar 1;
BA_ "GenSigStartValue" SG_ 834 LFSideSensorObj02_LatExtRtVar 255;
BA_ "GenSigSendType" SG_ 834 LFSideSensorObj02_Height 1;
BA_ "GenSigStartValue" SG_ 834 LFSideSensorObj02_Height 255;
BA_ "GenSigSendType" SG_ 834 LFSideSensorObj02_LongVelVar 1;
BA_ "GenSigStartValue" SG_ 834 LFSideSensorObj02_LongVelVar 255;
BA_ "GenSigSendType" SG_ 834 LFSideSensorObj02_Prioritisation 1;
BA_ "GenSigStartValue" SG_ 834 LFSideSensorObj02_Prioritisation 3;
BA_ "GenSigSendType" SG_ 834 LFSideSensorObj02_ExistConf 1;
BA_ "GenSigStartValue" SG_ 834 LFSideSensorObj02_ExistConf 127;
BA_ "GenSigSendType" SG_ 834 LFSideSensorObj02_CRC 1;
BA_ "GenSigStartValue" SG_ 834 LFSideSensorObj02_CRC 65535;
BA_ "E2EDataId" SG_ 834 LFSideSensorObj02_CRC 20;
BA_ "E2EDataLength" SG_ 834 LFSideSensorObj02_CRC 312;
BA_ "E2EProfile" SG_ 834 LFSideSensorObj02_CRC "P05";
BA_ "GenSigSendType" SG_ 834 LFSideSensorObj02_LongVel 1;
BA_ "GenSigStartValue" SG_ 834 LFSideSensorObj02_LongVel 8191;
BA_ "GenSigSendType" SG_ 834 LFSideSensorObj02_LongAcc 1;
BA_ "GenSigStartValue" SG_ 834 LFSideSensorObj02_LongAcc 511;
BA_ "GenSigSendType" SG_ 834 LFSideSensorObj02_LifeTime 1;
BA_ "GenSigStartValue" SG_ 834 LFSideSensorObj02_LifeTime 65535;
BA_ "GenSigSendType" SG_ 834 LFSideSensorObj02_LatAcc 1;
BA_ "GenSigStartValue" SG_ 834 LFSideSensorObj02_LatAcc 511;
BA_ "GenSigSendType" SG_ 834 LFSideSensorObj02_ObjClassConf 1;
BA_ "GenSigStartValue" SG_ 834 LFSideSensorObj02_ObjClassConf 15;
BA_ "GenSigSendType" SG_ 834 LFSideSensorObj02_LatPos 1;
BA_ "GenSigStartValue" SG_ 834 LFSideSensorObj02_LatPos 8191;
BA_ "GenSigSendType" SG_ 834 LFSideSensorObj02_ObjID 1;
BA_ "GenSigStartValue" SG_ 834 LFSideSensorObj02_ObjID 63;
BA_ "GenSigSendType" SG_ 834 LFSideSensorObj02_LongPos 1;
BA_ "GenSigStartValue" SG_ 834 LFSideSensorObj02_LongPos 8191;
BA_ "GenSigSendType" SG_ 834 LFSideSensorObj02_LatVel 1;
BA_ "GenSigStartValue" SG_ 834 LFSideSensorObj02_LatVel 8191;
BA_ "GenSigSendType" SG_ 834 LFSideSensorObj02_Heading 1;
BA_ "GenSigStartValue" SG_ 834 LFSideSensorObj02_Heading 2047;
BA_ "GenSigSendType" SG_ 834 LFSideSensorObj02_LongExtFront 1;
BA_ "GenSigStartValue" SG_ 834 LFSideSensorObj02_LongExtFront 1023;
BA_ "GenSigSendType" SG_ 834 LFSideSensorObj02_MOISPrio 1;
BA_ "GenSigSendType" SG_ 834 LFSideSensorObj02_LatAccVar 1;
BA_ "GenSigStartValue" SG_ 834 LFSideSensorObj02_LatAccVar 255;
BA_ "GenSigSendType" SG_ 834 LFSideSensorObj02_TimeStamp 1;
BA_ "GenSigStartValue" SG_ 834 LFSideSensorObj02_TimeStamp 65535;
BA_ "GenSigSendType" SG_ 834 LFSideSensorObj02_LongExtFrVar 1;
BA_ "GenSigStartValue" SG_ 834 LFSideSensorObj02_LongExtFrVar 255;
BA_ "GenSigSendType" SG_ 834 LFSideSensorObj02_LatExtLeft 1;
BA_ "GenSigStartValue" SG_ 834 LFSideSensorObj02_LatExtLeft 127;
BA_ "GenSigSendType" SG_ 834 LFSideSensorObj02_LongExtBack 1;
BA_ "GenSigStartValue" SG_ 834 LFSideSensorObj02_LongExtBack 1023;
BA_ "GenSigSendType" SG_ 834 LFSideSensorObj02_ObjDynClass 1;
BA_ "GenSigStartValue" SG_ 834 LFSideSensorObj02_ObjDynClass 3;
BA_ "GenSigSendType" SG_ 834 LFSideSensorObj02_HeadingVar 1;
BA_ "GenSigStartValue" SG_ 834 LFSideSensorObj02_HeadingVar 255;
BA_ "GenSigSendType" SG_ 834 LFSideSensorObj02_LongPosVar 1;
BA_ "GenSigStartValue" SG_ 834 LFSideSensorObj02_LongPosVar 255;
BA_ "GenSigSendType" SG_ 834 LFSideSensorObj02_LatPosVar 1;
BA_ "GenSigStartValue" SG_ 834 LFSideSensorObj02_LatPosVar 255;
BA_ "GenSigSendType" SG_ 834 LFSideSensorObj02_LatExtRight 1;
BA_ "GenSigStartValue" SG_ 834 LFSideSensorObj02_LatExtRight 127;
BA_ "GenSigSendType" SG_ 834 LFSideSensorObj02_LongAccVar 1;
BA_ "GenSigStartValue" SG_ 834 LFSideSensorObj02_LongAccVar 255;
BA_ "GenSigSendType" SG_ 834 LFSideSensorObj02_CoastIndex 1;
BA_ "GenSigStartValue" SG_ 834 LFSideSensorObj02_CoastIndex 31;
BA_ "GenSigSendType" SG_ 834 LFSideSensorObj02_Counter 1;
BA_ "GenSigStartValue" SG_ 834 LFSideSensorObj02_Counter 255;
BA_ "GenSigSendType" SG_ 834 LFSideSensorObj02_ObjClass 1;
BA_ "GenSigStartValue" SG_ 834 LFSideSensorObj02_ObjClass 15;
BA_ "GenSigSendType" SG_ 834 LFSideSensorObj02_LongExtBkVar 1;
BA_ "GenSigStartValue" SG_ 834 LFSideSensorObj02_LongExtBkVar 255;
BA_ "GenSigSendType" SG_ 834 LFSideSensorObj02_TrackStatus 1;
BA_ "GenSigStartValue" SG_ 834 LFSideSensorObj02_TrackStatus 7;
BA_ "GenSigSendType" SG_ 833 LFSideSensorObj01_LatAcc 1;
BA_ "GenSigStartValue" SG_ 833 LFSideSensorObj01_LatAcc 511;
BA_ "GenSigSendType" SG_ 833 LFSideSensorObj01_ExistConf 1;
BA_ "GenSigStartValue" SG_ 833 LFSideSensorObj01_ExistConf 127;
BA_ "GenSigSendType" SG_ 833 LFSideSensorObj01_ObjDynClass 1;
BA_ "GenSigStartValue" SG_ 833 LFSideSensorObj01_ObjDynClass 3;
BA_ "GenSigSendType" SG_ 833 LFSideSensorObj01_LongAcc 1;
BA_ "GenSigStartValue" SG_ 833 LFSideSensorObj01_LongAcc 511;
BA_ "GenSigSendType" SG_ 833 LFSideSensorObj01_LatExtRtVar 1;
BA_ "GenSigStartValue" SG_ 833 LFSideSensorObj01_LatExtRtVar 255;
BA_ "GenSigSendType" SG_ 833 LFSideSensorObj01_CRC 1;
BA_ "GenSigStartValue" SG_ 833 LFSideSensorObj01_CRC 65535;
BA_ "E2EDataId" SG_ 833 LFSideSensorObj01_CRC 19;
BA_ "E2EDataLength" SG_ 833 LFSideSensorObj01_CRC 312;
BA_ "E2EProfile" SG_ 833 LFSideSensorObj01_CRC "P05";
BA_ "GenSigSendType" SG_ 833 LFSideSensorObj01_LatVel 1;
BA_ "GenSigStartValue" SG_ 833 LFSideSensorObj01_LatVel 8191;
BA_ "GenSigSendType" SG_ 833 LFSideSensorObj01_LongExtBack 1;
BA_ "GenSigStartValue" SG_ 833 LFSideSensorObj01_LongExtBack 1023;
BA_ "GenSigSendType" SG_ 833 LFSideSensorObj01_LongAccVar 1;
BA_ "GenSigStartValue" SG_ 833 LFSideSensorObj01_LongAccVar 255;
BA_ "GenSigSendType" SG_ 833 LFSideSensorObj01_Counter 1;
BA_ "GenSigStartValue" SG_ 833 LFSideSensorObj01_Counter 255;
BA_ "GenSigSendType" SG_ 833 LFSideSensorObj01_Heading 1;
BA_ "GenSigStartValue" SG_ 833 LFSideSensorObj01_Heading 2047;
BA_ "GenSigSendType" SG_ 833 LFSideSensorObj01_ObjID 1;
BA_ "GenSigStartValue" SG_ 833 LFSideSensorObj01_ObjID 63;
BA_ "GenSigSendType" SG_ 833 LFSideSensorObj01_LatPosVar 1;
BA_ "GenSigStartValue" SG_ 833 LFSideSensorObj01_LatPosVar 255;
BA_ "GenSigSendType" SG_ 833 LFSideSensorObj01_LongVel 1;
BA_ "GenSigStartValue" SG_ 833 LFSideSensorObj01_LongVel 8191;
BA_ "GenSigSendType" SG_ 833 LFSideSensorObj01_ObjClass 1;
BA_ "GenSigStartValue" SG_ 833 LFSideSensorObj01_ObjClass 15;
BA_ "GenSigSendType" SG_ 833 LFSideSensorObj01_MOISPrio 1;
BA_ "GenSigSendType" SG_ 833 LFSideSensorObj01_LongPos 1;
BA_ "GenSigStartValue" SG_ 833 LFSideSensorObj01_LongPos 8191;
BA_ "GenSigSendType" SG_ 833 LFSideSensorObj01_LatExtRight 1;
BA_ "GenSigStartValue" SG_ 833 LFSideSensorObj01_LatExtRight 127;
BA_ "GenSigSendType" SG_ 833 LFSideSensorObj01_LatExtLeftVar 1;
BA_ "GenSigStartValue" SG_ 833 LFSideSensorObj01_LatExtLeftVar 255;
BA_ "GenSigSendType" SG_ 833 LFSideSensorObj01_LongExtFrVar 1;
BA_ "GenSigStartValue" SG_ 833 LFSideSensorObj01_LongExtFrVar 255;
BA_ "GenSigSendType" SG_ 833 LFSideSensorObj01_LatExtLeft 1;
BA_ "GenSigStartValue" SG_ 833 LFSideSensorObj01_LatExtLeft 127;
BA_ "GenSigSendType" SG_ 833 LFSideSensorObj01_Prioritisation 1;
BA_ "GenSigStartValue" SG_ 833 LFSideSensorObj01_Prioritisation 3;
BA_ "GenSigSendType" SG_ 833 LFSideSensorObj01_Height 1;
BA_ "GenSigStartValue" SG_ 833 LFSideSensorObj01_Height 255;
BA_ "GenSigSendType" SG_ 833 LFSideSensorObj01_HeadingVar 1;
BA_ "GenSigStartValue" SG_ 833 LFSideSensorObj01_HeadingVar 255;
BA_ "GenSigSendType" SG_ 833 LFSideSensorObj01_CoastIndex 1;
BA_ "GenSigStartValue" SG_ 833 LFSideSensorObj01_CoastIndex 31;
BA_ "GenSigSendType" SG_ 833 LFSideSensorObj01_ObjClassConf 1;
BA_ "GenSigStartValue" SG_ 833 LFSideSensorObj01_ObjClassConf 15;
BA_ "GenSigSendType" SG_ 833 LFSideSensorObj01_LongExtBkVar 1;
BA_ "GenSigStartValue" SG_ 833 LFSideSensorObj01_LongExtBkVar 255;
BA_ "GenSigSendType" SG_ 833 LFSideSensorObj01_LifeTime 1;
BA_ "GenSigStartValue" SG_ 833 LFSideSensorObj01_LifeTime 65535;
BA_ "GenSigSendType" SG_ 833 LFSideSensorObj01_LongPosVar 1;
BA_ "GenSigStartValue" SG_ 833 LFSideSensorObj01_LongPosVar 255;
BA_ "GenSigSendType" SG_ 833 LFSideSensorObj01_LatPos 1;
BA_ "GenSigStartValue" SG_ 833 LFSideSensorObj01_LatPos 8191;
BA_ "GenSigSendType" SG_ 833 LFSideSensorObj01_LongVelVar 1;
BA_ "GenSigStartValue" SG_ 833 LFSideSensorObj01_LongVelVar 255;
BA_ "GenSigSendType" SG_ 833 LFSideSensorObj01_LongExtFront 1;
BA_ "GenSigStartValue" SG_ 833 LFSideSensorObj01_LongExtFront 1023;
BA_ "GenSigSendType" SG_ 833 LFSideSensorObj01_ObstacleConf 1;
BA_ "GenSigStartValue" SG_ 833 LFSideSensorObj01_ObstacleConf 127;
BA_ "GenSigSendType" SG_ 833 LFSideSensorObj01_TrackStatus 1;
BA_ "GenSigStartValue" SG_ 833 LFSideSensorObj01_TrackStatus 7;
BA_ "GenSigSendType" SG_ 833 LFSideSensorObj01_TimeStamp 1;
BA_ "GenSigStartValue" SG_ 833 LFSideSensorObj01_TimeStamp 65535;
BA_ "GenSigSendType" SG_ 833 LFSideSensorObj01_LatAccVar 1;
BA_ "GenSigStartValue" SG_ 833 LFSideSensorObj01_LatAccVar 255;
BA_ "GenSigSendType" SG_ 833 LFSideSensorObj01_LatVelVar 1;
BA_ "GenSigStartValue" SG_ 833 LFSideSensorObj01_LatVelVar 255;
BA_ "GenSigSendType" SG_ 832 LFSideSensorObj00_LongAccVar 1;
BA_ "GenSigStartValue" SG_ 832 LFSideSensorObj00_LongAccVar 255;
BA_ "GenSigSendType" SG_ 832 LFSideSensorObj00_LongVelVar 1;
BA_ "GenSigStartValue" SG_ 832 LFSideSensorObj00_LongVelVar 255;
BA_ "GenSigSendType" SG_ 832 LFSideSensorObj00_Prioritisation 1;
BA_ "GenSigStartValue" SG_ 832 LFSideSensorObj00_Prioritisation 3;
BA_ "GenSigSendType" SG_ 832 LFSideSensorObj00_LatAcc 1;
BA_ "GenSigStartValue" SG_ 832 LFSideSensorObj00_LatAcc 511;
BA_ "GenSigSendType" SG_ 832 LFSideSensorObj00_MOISPrio 1;
BA_ "GenSigSendType" SG_ 832 LFSideSensorObj00_Heading 1;
BA_ "GenSigStartValue" SG_ 832 LFSideSensorObj00_Heading 2047;
BA_ "GenSigSendType" SG_ 832 LFSideSensorObj00_LongAcc 1;
BA_ "GenSigStartValue" SG_ 832 LFSideSensorObj00_LongAcc 511;
BA_ "GenSigSendType" SG_ 832 LFSideSensorObj00_LongPos 1;
BA_ "GenSigStartValue" SG_ 832 LFSideSensorObj00_LongPos 8191;
BA_ "GenSigSendType" SG_ 832 LFSideSensorObj00_ObjID 1;
BA_ "GenSigStartValue" SG_ 832 LFSideSensorObj00_ObjID 63;
BA_ "GenSigSendType" SG_ 832 LFSideSensorObj00_LongPosVar 1;
BA_ "GenSigStartValue" SG_ 832 LFSideSensorObj00_LongPosVar 255;
BA_ "GenSigSendType" SG_ 832 LFSideSensorObj00_HeadingVar 1;
BA_ "GenSigStartValue" SG_ 832 LFSideSensorObj00_HeadingVar 255;
BA_ "GenSigSendType" SG_ 832 LFSideSensorObj00_LongExtFrVar 1;
BA_ "GenSigStartValue" SG_ 832 LFSideSensorObj00_LongExtFrVar 255;
BA_ "GenSigSendType" SG_ 832 LFSideSensorObj00_LatVelVar 1;
BA_ "GenSigStartValue" SG_ 832 LFSideSensorObj00_LatVelVar 255;
BA_ "GenSigSendType" SG_ 832 LFSideSensorObj00_LatPosVar 1;
BA_ "GenSigStartValue" SG_ 832 LFSideSensorObj00_LatPosVar 255;
BA_ "GenSigSendType" SG_ 832 LFSideSensorObj00_ObjDynClass 1;
BA_ "GenSigStartValue" SG_ 832 LFSideSensorObj00_ObjDynClass 3;
BA_ "GenSigSendType" SG_ 832 LFSideSensorObj00_CRC 1;
BA_ "GenSigStartValue" SG_ 832 LFSideSensorObj00_CRC 65535;
BA_ "E2EDataId" SG_ 832 LFSideSensorObj00_CRC 18;
BA_ "E2EDataLength" SG_ 832 LFSideSensorObj00_CRC 312;
BA_ "E2EProfile" SG_ 832 LFSideSensorObj00_CRC "P05";
BA_ "GenSigSendType" SG_ 832 LFSideSensorObj00_ExistConf 1;
BA_ "GenSigStartValue" SG_ 832 LFSideSensorObj00_ExistConf 127;
BA_ "GenSigSendType" SG_ 832 LFSideSensorObj00_Height 1;
BA_ "GenSigStartValue" SG_ 832 LFSideSensorObj00_Height 255;
BA_ "GenSigSendType" SG_ 832 LFSideSensorObj00_LongVel 1;
BA_ "GenSigStartValue" SG_ 832 LFSideSensorObj00_LongVel 8191;
BA_ "GenSigSendType" SG_ 832 LFSideSensorObj00_LongExtBkVar 1;
BA_ "GenSigStartValue" SG_ 832 LFSideSensorObj00_LongExtBkVar 255;
BA_ "GenSigSendType" SG_ 832 LFSideSensorObj00_LatPos 1;
BA_ "GenSigStartValue" SG_ 832 LFSideSensorObj00_LatPos 8191;
BA_ "GenSigSendType" SG_ 832 LFSideSensorObj00_Counter 1;
BA_ "GenSigStartValue" SG_ 832 LFSideSensorObj00_Counter 255;
BA_ "GenSigSendType" SG_ 832 LFSideSensorObj00_ObjClass 1;
BA_ "GenSigStartValue" SG_ 832 LFSideSensorObj00_ObjClass 15;
BA_ "GenSigSendType" SG_ 832 LFSideSensorObj00_LatAccVar 1;
BA_ "GenSigStartValue" SG_ 832 LFSideSensorObj00_LatAccVar 255;
BA_ "GenSigSendType" SG_ 832 LFSideSensorObj00_TrackStatus 1;
BA_ "GenSigStartValue" SG_ 832 LFSideSensorObj00_TrackStatus 7;
BA_ "GenSigSendType" SG_ 832 LFSideSensorObj00_LatExtRtVar 1;
BA_ "GenSigStartValue" SG_ 832 LFSideSensorObj00_LatExtRtVar 255;
BA_ "GenSigSendType" SG_ 832 LFSideSensorObj00_ObstacleConf 1;
BA_ "GenSigStartValue" SG_ 832 LFSideSensorObj00_ObstacleConf 127;
BA_ "GenSigSendType" SG_ 832 LFSideSensorObj00_LongExtBack 1;
BA_ "GenSigStartValue" SG_ 832 LFSideSensorObj00_LongExtBack 1023;
BA_ "GenSigSendType" SG_ 832 LFSideSensorObj00_ObjClassConf 1;
BA_ "GenSigStartValue" SG_ 832 LFSideSensorObj00_ObjClassConf 15;
BA_ "GenSigSendType" SG_ 832 LFSideSensorObj00_LatExtLeftVar 1;
BA_ "GenSigStartValue" SG_ 832 LFSideSensorObj00_LatExtLeftVar 255;
BA_ "GenSigSendType" SG_ 832 LFSideSensorObj00_LifeTime 1;
BA_ "GenSigStartValue" SG_ 832 LFSideSensorObj00_LifeTime 65535;
BA_ "GenSigSendType" SG_ 832 LFSideSensorObj00_LatExtLeft 1;
BA_ "GenSigStartValue" SG_ 832 LFSideSensorObj00_LatExtLeft 127;
BA_ "GenSigSendType" SG_ 832 LFSideSensorObj00_TimeStamp 1;
BA_ "GenSigStartValue" SG_ 832 LFSideSensorObj00_TimeStamp 65535;
BA_ "GenSigSendType" SG_ 832 LFSideSensorObj00_LatVel 1;
BA_ "GenSigStartValue" SG_ 832 LFSideSensorObj00_LatVel 8191;
BA_ "GenSigSendType" SG_ 832 LFSideSensorObj00_LongExtFront 1;
BA_ "GenSigStartValue" SG_ 832 LFSideSensorObj00_LongExtFront 1023;
BA_ "GenSigSendType" SG_ 832 LFSideSensorObj00_LatExtRight 1;
BA_ "GenSigStartValue" SG_ 832 LFSideSensorObj00_LatExtRight 127;
BA_ "GenSigSendType" SG_ 832 LFSideSensorObj00_CoastIndex 1;
BA_ "GenSigStartValue" SG_ 832 LFSideSensorObj00_CoastIndex 31;
BA_ "GenSigCycleTime" SG_ 1556 LFSRSwVersion_Substring6 100;
BA_ "GenSigCycleTimeActive" SG_ 1556 LFSRSwVersion_Substring6 100;
BA_ "GenSigCycleTime" SG_ 1556 LFSRSwVersion_Substring2 100;
BA_ "GenSigCycleTimeActive" SG_ 1556 LFSRSwVersion_Substring2 100;
BA_ "GenSigCycleTime" SG_ 1556 LFSRSwVersion_Substring1 100;
BA_ "GenSigCycleTimeActive" SG_ 1556 LFSRSwVersion_Substring1 100;
BA_ "GenSigCycleTime" SG_ 1556 LFSRSwVersion_Substring0 100;
BA_ "GenSigCycleTimeActive" SG_ 1556 LFSRSwVersion_Substring0 100;
BA_ "GenSigCycleTime" SG_ 1556 LFSRSwVersion_Substring3 100;
BA_ "GenSigCycleTimeActive" SG_ 1556 LFSRSwVersion_Substring3 100;
BA_ "GenSigCycleTime" SG_ 1556 LFSRSwVersion_Substring5 100;
BA_ "GenSigCycleTimeActive" SG_ 1556 LFSRSwVersion_Substring5 100;
BA_ "GenSigCycleTime" SG_ 1556 LFSRSwVersion_Substring4 100;
BA_ "GenSigCycleTimeActive" SG_ 1556 LFSRSwVersion_Substring4 100;
BA_ "GenSigCycleTime" SG_ 1556 LFSRSwVersion_Substring7 100;
BA_ "GenSigCycleTimeActive" SG_ 1556 LFSRSwVersion_Substring7 100;
BA_ "GenSigSendType" SG_ 847 LFSRRaisedEdge_LifeTime 1;
BA_ "GenSigStartValue" SG_ 847 LFSRRaisedEdge_LifeTime 65535;
BA_ "GenSigSendType" SG_ 847 LFSRRaisedEdge_HeadingAngle 1;
BA_ "GenSigStartValue" SG_ 847 LFSRRaisedEdge_HeadingAngle 8191;
BA_ "GenSigSendType" SG_ 847 LFSRRaisedEdge_Curvature 1;
BA_ "GenSigStartValue" SG_ 847 LFSRRaisedEdge_Curvature 262143;
BA_ "GenSigSendType" SG_ 847 LFSRRaisedEdge_CoastIndex 1;
BA_ "GenSigStartValue" SG_ 847 LFSRRaisedEdge_CoastIndex 31;
BA_ "GenSigSendType" SG_ 847 LFSRRaisedEdge_Confidence 1;
BA_ "GenSigStartValue" SG_ 847 LFSRRaisedEdge_Confidence 127;
BA_ "GenSigSendType" SG_ 847 LFSRRaisedEdge_DxEnd 1;
BA_ "GenSigStartValue" SG_ 847 LFSRRaisedEdge_DxEnd 255;
BA_ "GenSigSendType" SG_ 847 LFSRRaisedEdge_Type 1;
BA_ "GenSigStartValue" SG_ 847 LFSRRaisedEdge_Type 7;
BA_ "GenSigSendType" SG_ 847 LFSRRaisedEdge_CurvatureRate 1;
BA_ "GenSigStartValue" SG_ 847 LFSRRaisedEdge_CurvatureRate 2047;
BA_ "GenSigSendType" SG_ 847 LFSRRaisedEdge_Counter 1;
BA_ "GenSigStartValue" SG_ 847 LFSRRaisedEdge_Counter 255;
BA_ "GenSigSendType" SG_ 847 LFSRRaisedEdge_LatDist 1;
BA_ "GenSigStartValue" SG_ 847 LFSRRaisedEdge_LatDist 4095;
BA_ "GenSigSendType" SG_ 847 LFSRRaisedEdge_DxStart 1;
BA_ "GenSigStartValue" SG_ 847 LFSRRaisedEdge_DxStart 255;
BA_ "GenSigSendType" SG_ 847 LFSRRaisedEdge_TimeStamp 1;
BA_ "GenSigStartValue" SG_ 847 LFSRRaisedEdge_TimeStamp 65535;
BA_ "GenSigSendType" SG_ 847 LFSRRaisedEdge_CRC 1;
BA_ "GenSigStartValue" SG_ 847 LFSRRaisedEdge_CRC 65535;
BA_ "E2EDataId" SG_ 847 LFSRRaisedEdge_CRC 111;
BA_ "E2EDataLength" SG_ 847 LFSRRaisedEdge_CRC 152;
BA_ "E2EProfile" SG_ 847 LFSRRaisedEdge_CRC "P05";
BA_ "GenSigSendType" SG_ 847 LFSRRaisedEdge_TrackStatus 1;
BA_ "GenSigStartValue" SG_ 847 LFSRRaisedEdge_TrackStatus 7;
BA_ "GenSigSendType" SG_ 847 LFSRRaisedEdge_LatDistVar 1;
BA_ "GenSigStartValue" SG_ 847 LFSRRaisedEdge_LatDistVar 255;
BA_ "GenSigSendType" SG_ 846 LFSREgoAssumpt_EgoLongVel 1;
BA_ "GenSigStartValue" SG_ 846 LFSREgoAssumpt_EgoLongVel 65535;
BA_ "GenSigSendType" SG_ 846 LFSREgoAssumpt_EgoRoadEnd 1;
BA_ "GenSigStartValue" SG_ 846 LFSREgoAssumpt_EgoRoadEnd 255;
BA_ "GenSigSendType" SG_ 846 LFSREgoAssumpt_EgoLongAcc 1;
BA_ "GenSigStartValue" SG_ 846 LFSREgoAssumpt_EgoLongAcc 65535;
BA_ "GenSigSendType" SG_ 846 LFSREgoAssumpt_EgoRoadCurvature 1;
BA_ "GenSigStartValue" SG_ 846 LFSREgoAssumpt_EgoRoadCurvature 262143;
BA_ "GenSigSendType" SG_ 846 LFSREgoAssumpt_EgoRoadCurvRate 1;
BA_ "GenSigStartValue" SG_ 846 LFSREgoAssumpt_EgoRoadCurvRate 2047;
BA_ "GenSigSendType" SG_ 846 LFSREgoAssumpt_EgoYawRate 1;
BA_ "GenSigStartValue" SG_ 846 LFSREgoAssumpt_EgoYawRate 65535;
BA_ "GenSigSendType" SG_ 846 LFSREgoAssumpt_VelCorrFactor 1;
BA_ "GenSigStartValue" SG_ 846 LFSREgoAssumpt_VelCorrFactor 255;
BA_ "GenSigSendType" SG_ 846 LFSREgoAssumpt_EgoRoadHeading 1;
BA_ "GenSigStartValue" SG_ 846 LFSREgoAssumpt_EgoRoadHeading 8191;
BA_ "GenSigSendType" SG_ 846 LFSREgoAssumpt_TimeStamp 1;
BA_ "GenSigStartValue" SG_ 846 LFSREgoAssumpt_TimeStamp 65535;
BA_ "GenSigSendType" SG_ 2671902708 FuncDiagDataIntTesterTGW2 7;
BA_ "Platform_VMCU1_Sig" SG_ 2671902708 FuncDiagDataIntTesterTGW2 1;
BA_ "GenSigSendType" SG_ 2671964779 DiagUUDTRespSig_F2_6B 7;
BA_ "GenSigSendType" SG_ 2671964778 DiagUUDTRespSig_F2_6A 7;
BA_ "GenSigSendType" SG_ 2671964777 DiagUUDTRespSig_F2_69 7;
BA_ "GenSigSendType" SG_ 2671964776 DiagUUDTRespSig_F2_68 7;
BA_ "GenSigSendType" SG_ 2671834219 InternalTesterDiagSig_F4_6B 7;
BA_ "GenSigSendType" SG_ 2671834218 InternalTesterDiagSig_F4_6A 7;
BA_ "GenSigSendType" SG_ 2671834217 InternalTesterDiagSig_F4_69 7;
BA_ "GenSigSendType" SG_ 2671834216 InternalTesterDiagSig_F4_68 7;
BA_ "GenSigSendType" SG_ 2671833963 InternalTesterDiagSig_F3_6B 7;
BA_ "GenSigSendType" SG_ 2671833962 InternalTesterDiagSig_F3_6A 7;
BA_ "GenSigSendType" SG_ 2671833961 InternalTesterDiagSig_F3_69 7;
BA_ "GenSigSendType" SG_ 2671833960 InternalTesterDiagSig_F3_68 7;
BA_ "GenSigSendType" SG_ 2671799284 InternalTesterDiagSig_6B_F4 7;
BA_ "GenSigSendType" SG_ 2671799028 InternalTesterDiagSig_6A_F4 7;
BA_ "GenSigSendType" SG_ 2671798772 InternalTesterDiagSig_69_F4 7;
BA_ "GenSigSendType" SG_ 2671798516 InternalTesterDiagSig_68_F4 7;
BA_ "GenSigSendType" SG_ 2671799283 InternalTesterDiagSig_6B_F3 7;
BA_ "GenSigSendType" SG_ 2671799027 InternalTesterDiagSig_6A_F3 7;
BA_ "GenSigSendType" SG_ 2671798771 InternalTesterDiagSig_69_F3 7;
BA_ "GenSigSendType" SG_ 2671798515 InternalTesterDiagSig_68_F3 7;
BA_ "GenSigSendType" SG_ 1523 DiagFaultStat_SRRR_sg_UB 7;
BA_ "GenSigSendType" SG_ 1523 DiagFaultStat_SRRR_DtcIdA 3;
BA_ "NeedsUpdateBit" SG_ 1523 DiagFaultStat_SRRR_DtcIdA 1;
BA_ "GenSigSendType" SG_ 1523 DiagFaultStat_SRRR_FailTB 3;
BA_ "NeedsUpdateBit" SG_ 1523 DiagFaultStat_SRRR_FailTB 1;
BA_ "GenSigSendType" SG_ 1523 DiagFaultStat_SRRR_DtcIdB 3;
BA_ "NeedsUpdateBit" SG_ 1523 DiagFaultStat_SRRR_DtcIdB 1;
BA_ "GenSigSendType" SG_ 1523 DiagFaultStat_SRRR_FailTA 3;
BA_ "NeedsUpdateBit" SG_ 1523 DiagFaultStat_SRRR_FailTA 1;
BA_ "GenSigSendType" SG_ 1523 DiagFaultStat_SRRR_EcuAdr 3;
BA_ "GenSigStartValue" SG_ 1523 DiagFaultStat_SRRR_EcuAdr 106;
BA_ "NeedsUpdateBit" SG_ 1523 DiagFaultStat_SRRR_EcuAdr 1;
BA_ "GenSigSendType" SG_ 1522 DiagFaultStat_SRRF_FailTA 3;
BA_ "NeedsUpdateBit" SG_ 1522 DiagFaultStat_SRRF_FailTA 1;
BA_ "GenSigSendType" SG_ 1522 DiagFaultStat_SRRF_DtcIdA 3;
BA_ "NeedsUpdateBit" SG_ 1522 DiagFaultStat_SRRF_DtcIdA 1;
BA_ "GenSigSendType" SG_ 1522 DiagFaultStat_SRRF_FailTB 3;
BA_ "NeedsUpdateBit" SG_ 1522 DiagFaultStat_SRRF_FailTB 1;
BA_ "GenSigSendType" SG_ 1522 DiagFaultStat_SRRF_EcuAdr 3;
BA_ "GenSigStartValue" SG_ 1522 DiagFaultStat_SRRF_EcuAdr 107;
BA_ "NeedsUpdateBit" SG_ 1522 DiagFaultStat_SRRF_EcuAdr 1;
BA_ "GenSigSendType" SG_ 1522 DiagFaultStat_SRRF_DtcIdB 3;
BA_ "NeedsUpdateBit" SG_ 1522 DiagFaultStat_SRRF_DtcIdB 1;
BA_ "GenSigSendType" SG_ 1522 DiagFaultStat_SRRF_sg_UB 7;
BA_ "GenSigSendType" SG_ 1521 DiagFaultStat_SRLR_FailTA 3;
BA_ "NeedsUpdateBit" SG_ 1521 DiagFaultStat_SRLR_FailTA 1;
BA_ "GenSigSendType" SG_ 1521 DiagFaultStat_SRLR_FailTB 3;
BA_ "NeedsUpdateBit" SG_ 1521 DiagFaultStat_SRLR_FailTB 1;
BA_ "GenSigSendType" SG_ 1521 DiagFaultStat_SRLR_EcuAdr 3;
BA_ "GenSigStartValue" SG_ 1521 DiagFaultStat_SRLR_EcuAdr 104;
BA_ "NeedsUpdateBit" SG_ 1521 DiagFaultStat_SRLR_EcuAdr 1;
BA_ "GenSigSendType" SG_ 1521 DiagFaultStat_SRLR_sg_UB 7;
BA_ "GenSigSendType" SG_ 1521 DiagFaultStat_SRLR_DtcIdA 3;
BA_ "NeedsUpdateBit" SG_ 1521 DiagFaultStat_SRLR_DtcIdA 1;
BA_ "GenSigSendType" SG_ 1521 DiagFaultStat_SRLR_DtcIdB 3;
BA_ "NeedsUpdateBit" SG_ 1521 DiagFaultStat_SRLR_DtcIdB 1;
BA_ "GenSigSendType" SG_ 1524 DiagFaultStat_SRLF_DtcIdA 3;
BA_ "NeedsUpdateBit" SG_ 1524 DiagFaultStat_SRLF_DtcIdA 1;
BA_ "GenSigSendType" SG_ 1524 DiagFaultStat_SRLF_FailTA 3;
BA_ "NeedsUpdateBit" SG_ 1524 DiagFaultStat_SRLF_FailTA 1;
BA_ "GenSigSendType" SG_ 1524 DiagFaultStat_SRLF_FailTB 3;
BA_ "NeedsUpdateBit" SG_ 1524 DiagFaultStat_SRLF_FailTB 1;
BA_ "GenSigSendType" SG_ 1524 DiagFaultStat_SRLF_sg_UB 7;
BA_ "GenSigSendType" SG_ 1524 DiagFaultStat_SRLF_DtcIdB 3;
BA_ "NeedsUpdateBit" SG_ 1524 DiagFaultStat_SRLF_DtcIdB 1;
BA_ "GenSigSendType" SG_ 1524 DiagFaultStat_SRLF_EcuAdr 3;
BA_ "GenSigStartValue" SG_ 1524 DiagFaultStat_SRLF_EcuAdr 105;
BA_ "NeedsUpdateBit" SG_ 1524 DiagFaultStat_SRLF_EcuAdr 1;
BA_ "GenSigSendType" SG_ 257 DACUTimeSync_TimeDomain 1;
BA_ "GenSigStartValue" SG_ 257 DACUTimeSync_TimeDomain 15;
BA_ "GenSigSendType" SG_ 257 DACUTimeSync_SeqCnt 1;
BA_ "GenSigStartValue" SG_ 257 DACUTimeSync_SeqCnt 15;
BA_ "GenSigSendType" SG_ 257 DACUTimeSync_Time 1;
BA_ "GenSigSendType" SG_ 257 DACUTimeSync_Type 1;
BA_ "GenSigSendType" SG_ 257 DACUTimeSync_UserByte 1;
BA_ "GenSigSendType" SG_ 257 DACUTimeSync_CRC 1;
BA_ "GenSigSendType" SG_ 761 DACUTimeSyncOFS_TimeDomain 1;
BA_ "GenSigStartValue" SG_ 761 DACUTimeSyncOFS_TimeDomain 15;
BA_ "GenSigSendType" SG_ 761 DACUTimeSyncOFS_OfsTimeSec 1;
BA_ "GenSigSendType" SG_ 761 DACUTimeSyncOFS_TypeOFS 1;
BA_ "GenSigSendType" SG_ 761 DACUTimeSyncOFS_SeqCnt 1;
BA_ "GenSigStartValue" SG_ 761 DACUTimeSyncOFS_SeqCnt 15;
BA_ "GenSigSendType" SG_ 761 DACUTimeSyncOFS_UserByte0 1;
BA_ "GenSigSendType" SG_ 761 DACUTimeSyncOFS_CRCOFS 1;
BA_ "GenSigSendType" SG_ 760 DACUTimeSyncOFNS_CRCOFNS 1;
BA_ "GenSigSendType" SG_ 760 DACUTimeSyncOFNS_TypeOFNS 1;
BA_ "GenSigSendType" SG_ 760 DACUTimeSyncOFNS_TimeDomain 1;
BA_ "GenSigStartValue" SG_ 760 DACUTimeSyncOFNS_TimeDomain 15;
BA_ "GenSigSendType" SG_ 760 DACUTimeSyncOFNS_SGW 1;
BA_ "GenSigSendType" SG_ 760 DACUTimeSyncOFNS_OfsTimeNsec 1;
BA_ "GenSigSendType" SG_ 760 DACUTimeSyncOFNS_SeqCnt 1;
BA_ "GenSigStartValue" SG_ 760 DACUTimeSyncOFNS_SeqCnt 15;
BA_ "GenSigCycleTime" SG_ 279 EgoPathPrediction_DxEnd 100;
BA_ "GenSigCycleTimeActive" SG_ 279 EgoPathPrediction_DxEnd 100;
BA_ "GenSigStartValue" SG_ 279 EgoPathPrediction_DxEnd 255;
BA_ "GenSigCycleTime" SG_ 279 EgoPathPrediction_ConfCoeffA1 100;
BA_ "GenSigCycleTimeActive" SG_ 279 EgoPathPrediction_ConfCoeffA1 100;
BA_ "GenSigStartValue" SG_ 279 EgoPathPrediction_ConfCoeffA1 65535;
BA_ "GenSigCycleTime" SG_ 279 EgoPathPrediction_ConfCoeffA0 100;
BA_ "GenSigCycleTimeActive" SG_ 279 EgoPathPrediction_ConfCoeffA0 100;
BA_ "GenSigStartValue" SG_ 279 EgoPathPrediction_ConfCoeffA0 65535;
BA_ "GenSigCycleTime" SG_ 279 EgoPathPrediction_ConfCoeffA2 100;
BA_ "GenSigCycleTimeActive" SG_ 279 EgoPathPrediction_ConfCoeffA2 100;
BA_ "GenSigStartValue" SG_ 279 EgoPathPrediction_ConfCoeffA2 65535;
BA_ "GenSigCycleTime" SG_ 279 EgoPathPrediction_Curvature 100;
BA_ "GenSigCycleTimeActive" SG_ 279 EgoPathPrediction_Curvature 100;
BA_ "GenSigStartValue" SG_ 279 EgoPathPrediction_Curvature 262143;
BA_ "GenSigCycleTime" SG_ 279 EgoPathPrediction_HeadingAngle 100;
BA_ "GenSigCycleTimeActive" SG_ 279 EgoPathPrediction_HeadingAngle 100;
BA_ "GenSigStartValue" SG_ 279 EgoPathPrediction_HeadingAngle 8191;
BA_ "GenSigCycleTime" SG_ 279 EgoPathPrediction_ConfCoeffA3 100;
BA_ "GenSigCycleTimeActive" SG_ 279 EgoPathPrediction_ConfCoeffA3 100;
BA_ "GenSigStartValue" SG_ 279 EgoPathPrediction_ConfCoeffA3 65535;
BA_ "GenSigCycleTime" SG_ 279 EgoPathPrediction_CurvatureRate 100;
BA_ "GenSigCycleTimeActive" SG_ 279 EgoPathPrediction_CurvatureRate 100;
BA_ "GenSigStartValue" SG_ 279 EgoPathPrediction_CurvatureRate 2047;
BA_ "GenSigSendType" SG_ 275 EgoMotionXYplane_LateralAcc 1;
BA_ "GenSigStartValue" SG_ 275 EgoMotionXYplane_LateralAcc 65535;
BA_ "GenSigSendType" SG_ 275 EgoMotionXYplane_LongAcc 1;
BA_ "GenSigStartValue" SG_ 275 EgoMotionXYplane_LongAcc 65535;
BA_ "GenSigSendType" SG_ 275 EgoMotionXYplane_LongSpeed 1;
BA_ "GenSigStartValue" SG_ 275 EgoMotionXYplane_LongSpeed 65535;
BA_ "GenSigSendType" SG_ 275 EgoMotionXYplane_LongMotDirConf 1;
BA_ "GenSigStartValue" SG_ 275 EgoMotionXYplane_LongMotDirConf 15;
BA_ "GenSigSendType" SG_ 275 EgoMotionXYplane_Curvature 1;
BA_ "GenSigStartValue" SG_ 275 EgoMotionXYplane_Curvature 2097151;
BA_ "GenSigSendType" SG_ 275 EgoMotionXYplane_EffectiveWheelB 1;
BA_ "GenSigStartValue" SG_ 275 EgoMotionXYplane_EffectiveWheelB 1023;
BA_ "GenSigSendType" SG_ 275 EgoMotionXYplane_LongMotionDir 1;
BA_ "GenSigStartValue" SG_ 275 EgoMotionXYplane_LongMotionDir 7;
BA_ "GenSigSendType" SG_ 275 EgoMotionXYplane_LongSpeedVar 1;
BA_ "GenSigStartValue" SG_ 275 EgoMotionXYplane_LongSpeedVar 65535;
BA_ "GenSigSendType" SG_ 275 EgoMotionXYplane_Counter 1;
BA_ "GenSigStartValue" SG_ 275 EgoMotionXYplane_Counter 255;
BA_ "GenSigSendType" SG_ 275 EgoMotionXYplane_LatencyEst 1;
BA_ "GenSigStartValue" SG_ 275 EgoMotionXYplane_LatencyEst 255;
BA_ "GenSigSendType" SG_ 275 EgoMotionXYplane_LatAccVariance 1;
BA_ "GenSigStartValue" SG_ 275 EgoMotionXYplane_LatAccVariance 63;
BA_ "GenSigSendType" SG_ 275 EgoMotionXYplane_CRC 1;
BA_ "GenSigStartValue" SG_ 275 EgoMotionXYplane_CRC 65535;
BA_ "E2EDataId" SG_ 275 EgoMotionXYplane_CRC 17;
BA_ "E2EDataLength" SG_ 275 EgoMotionXYplane_CRC 240;
BA_ "E2EProfile" SG_ 275 EgoMotionXYplane_CRC "P05";
BA_ "GenSigSendType" SG_ 275 EgoMotionXYplane_ReferencePointX 1;
BA_ "GenSigStartValue" SG_ 275 EgoMotionXYplane_ReferencePointX 65535;
BA_ "GenSigSendType" SG_ 275 EgoMotionXYplane_LateralSpeed 1;
BA_ "GenSigStartValue" SG_ 275 EgoMotionXYplane_LateralSpeed 65535;
BA_ "GenSigSendType" SG_ 275 EgoMotionXYplane_LatSpeedVar 1;
BA_ "GenSigStartValue" SG_ 275 EgoMotionXYplane_LatSpeedVar 65535;
BA_ "GenSigSendType" SG_ 275 EgoMotionXYplane_YawRateComp 1;
BA_ "GenSigStartValue" SG_ 275 EgoMotionXYplane_YawRateComp 65535;
BA_ "GenSigSendType" SG_ 275 EgoMotionXYplane_ChassisDynPitch 1;
BA_ "GenSigStartValue" SG_ 275 EgoMotionXYplane_ChassisDynPitch 255;
BA_ "GenSigSendType" SG_ 275 EgoMotionXYplane_YawRateVariance 1;
BA_ "GenSigStartValue" SG_ 275 EgoMotionXYplane_YawRateVariance 65535;
BA_ "GenSigSendType" SG_ 275 EgoMotionXYplane_LongAccVariance 1;
BA_ "GenSigStartValue" SG_ 275 EgoMotionXYplane_LongAccVariance 63;
BA_REL_ "GenSigFirstTimeoutTime" BU_SG_REL_ DACU SG_ 1556 LFSRSwVersion_Substring6 60000;
BA_REL_ "GenSigTimeoutTime" BU_SG_REL_ DACU SG_ 1556 LFSRSwVersion_Substring6 60000;
BA_REL_ "GenSigFirstTimeoutTime" BU_SG_REL_ DACU SG_ 1556 LFSRSwVersion_Substring2 60000;
BA_REL_ "GenSigTimeoutTime" BU_SG_REL_ DACU SG_ 1556 LFSRSwVersion_Substring2 60000;
BA_REL_ "GenSigFirstTimeoutTime" BU_SG_REL_ DACU SG_ 1556 LFSRSwVersion_Substring1 60000;
BA_REL_ "GenSigTimeoutTime" BU_SG_REL_ DACU SG_ 1556 LFSRSwVersion_Substring1 60000;
BA_REL_ "GenSigFirstTimeoutTime" BU_SG_REL_ DACU SG_ 1556 LFSRSwVersion_Substring0 60000;
BA_REL_ "GenSigTimeoutTime" BU_SG_REL_ DACU SG_ 1556 LFSRSwVersion_Substring0 60000;
BA_REL_ "GenSigFirstTimeoutTime" BU_SG_REL_ DACU SG_ 1556 LFSRSwVersion_Substring3 60000;
BA_REL_ "GenSigTimeoutTime" BU_SG_REL_ DACU SG_ 1556 LFSRSwVersion_Substring3 60000;
BA_REL_ "GenSigFirstTimeoutTime" BU_SG_REL_ DACU SG_ 1556 LFSRSwVersion_Substring5 60000;
BA_REL_ "GenSigTimeoutTime" BU_SG_REL_ DACU SG_ 1556 LFSRSwVersion_Substring5 60000;
BA_REL_ "GenSigFirstTimeoutTime" BU_SG_REL_ DACU SG_ 1556 LFSRSwVersion_Substring4 60000;
BA_REL_ "GenSigTimeoutTime" BU_SG_REL_ DACU SG_ 1556 LFSRSwVersion_Substring4 60000;
BA_REL_ "GenSigFirstTimeoutTime" BU_SG_REL_ DACU SG_ 1556 LFSRSwVersion_Substring7 60000;
BA_REL_ "GenSigTimeoutTime" BU_SG_REL_ DACU SG_ 1556 LFSRSwVersion_Substring7 60000;
BA_REL_ "GenSigFirstTimeoutTime" BU_SG_REL_ DACU SG_ 847 LFSRRaisedEdge_LifeTime 3000;
BA_REL_ "GenSigTimeoutTime" BU_SG_REL_ DACU SG_ 847 LFSRRaisedEdge_LifeTime 300;
BA_REL_ "GenSigFirstTimeoutTime" BU_SG_REL_ DACU SG_ 847 LFSRRaisedEdge_HeadingAngle 3000;
BA_REL_ "GenSigTimeoutTime" BU_SG_REL_ DACU SG_ 847 LFSRRaisedEdge_HeadingAngle 300;
BA_REL_ "GenSigFirstTimeoutTime" BU_SG_REL_ DACU SG_ 847 LFSRRaisedEdge_Curvature 3000;
BA_REL_ "GenSigTimeoutTime" BU_SG_REL_ DACU SG_ 847 LFSRRaisedEdge_Curvature 300;
BA_REL_ "GenSigFirstTimeoutTime" BU_SG_REL_ DACU SG_ 847 LFSRRaisedEdge_CoastIndex 3000;
BA_REL_ "GenSigTimeoutTime" BU_SG_REL_ DACU SG_ 847 LFSRRaisedEdge_CoastIndex 300;
BA_REL_ "GenSigFirstTimeoutTime" BU_SG_REL_ DACU SG_ 847 LFSRRaisedEdge_Confidence 3000;
BA_REL_ "GenSigTimeoutTime" BU_SG_REL_ DACU SG_ 847 LFSRRaisedEdge_Confidence 300;
BA_REL_ "GenSigFirstTimeoutTime" BU_SG_REL_ DACU SG_ 847 LFSRRaisedEdge_DxEnd 3000;
BA_REL_ "GenSigTimeoutTime" BU_SG_REL_ DACU SG_ 847 LFSRRaisedEdge_DxEnd 300;
BA_REL_ "GenSigFirstTimeoutTime" BU_SG_REL_ DACU SG_ 847 LFSRRaisedEdge_Type 3000;
BA_REL_ "GenSigTimeoutTime" BU_SG_REL_ DACU SG_ 847 LFSRRaisedEdge_Type 300;
BA_REL_ "GenSigFirstTimeoutTime" BU_SG_REL_ DACU SG_ 847 LFSRRaisedEdge_CurvatureRate 3000;
BA_REL_ "GenSigTimeoutTime" BU_SG_REL_ DACU SG_ 847 LFSRRaisedEdge_CurvatureRate 300;
BA_REL_ "GenSigFirstTimeoutTime" BU_SG_REL_ DACU SG_ 847 LFSRRaisedEdge_Counter 3000;
BA_REL_ "GenSigTimeoutTime" BU_SG_REL_ DACU SG_ 847 LFSRRaisedEdge_Counter 300;
BA_REL_ "GenSigFirstTimeoutTime" BU_SG_REL_ DACU SG_ 847 LFSRRaisedEdge_LatDist 3000;
BA_REL_ "GenSigTimeoutTime" BU_SG_REL_ DACU SG_ 847 LFSRRaisedEdge_LatDist 300;
BA_REL_ "GenSigFirstTimeoutTime" BU_SG_REL_ DACU SG_ 847 LFSRRaisedEdge_DxStart 3000;
BA_REL_ "GenSigTimeoutTime" BU_SG_REL_ DACU SG_ 847 LFSRRaisedEdge_DxStart 300;
BA_REL_ "GenSigFirstTimeoutTime" BU_SG_REL_ DACU SG_ 847 LFSRRaisedEdge_TimeStamp 3000;
BA_REL_ "GenSigTimeoutTime" BU_SG_REL_ DACU SG_ 847 LFSRRaisedEdge_TimeStamp 300;
BA_REL_ "GenSigFirstTimeoutTime" BU_SG_REL_ DACU SG_ 847 LFSRRaisedEdge_CRC 3000;
BA_REL_ "GenSigTimeoutTime" BU_SG_REL_ DACU SG_ 847 LFSRRaisedEdge_CRC 300;
BA_REL_ "GenSigFirstTimeoutTime" BU_SG_REL_ DACU SG_ 847 LFSRRaisedEdge_TrackStatus 3000;
BA_REL_ "GenSigTimeoutTime" BU_SG_REL_ DACU SG_ 847 LFSRRaisedEdge_TrackStatus 300;
BA_REL_ "GenSigFirstTimeoutTime" BU_SG_REL_ DACU SG_ 847 LFSRRaisedEdge_LatDistVar 3000;
BA_REL_ "GenSigTimeoutTime" BU_SG_REL_ DACU SG_ 847 LFSRRaisedEdge_LatDistVar 300;
BA_REL_ "GenSigFirstTimeoutTime" BU_SG_REL_ DACU SG_ 846 LFSREgoAssumpt_EgoLongVel 3000;
BA_REL_ "GenSigTimeoutTime" BU_SG_REL_ DACU SG_ 846 LFSREgoAssumpt_EgoLongVel 300;
BA_REL_ "GenSigFirstTimeoutTime" BU_SG_REL_ DACU SG_ 846 LFSREgoAssumpt_EgoRoadEnd 3000;
BA_REL_ "GenSigTimeoutTime" BU_SG_REL_ DACU SG_ 846 LFSREgoAssumpt_EgoRoadEnd 300;
BA_REL_ "GenSigFirstTimeoutTime" BU_SG_REL_ DACU SG_ 846 LFSREgoAssumpt_EgoLongAcc 3000;
BA_REL_ "GenSigTimeoutTime" BU_SG_REL_ DACU SG_ 846 LFSREgoAssumpt_EgoLongAcc 300;
BA_REL_ "GenSigFirstTimeoutTime" BU_SG_REL_ DACU SG_ 846 LFSREgoAssumpt_EgoRoadCurvature 3000;
BA_REL_ "GenSigTimeoutTime" BU_SG_REL_ DACU SG_ 846 LFSREgoAssumpt_EgoRoadCurvature 300;
BA_REL_ "GenSigFirstTimeoutTime" BU_SG_REL_ DACU SG_ 846 LFSREgoAssumpt_EgoRoadCurvRate 3000;
BA_REL_ "GenSigTimeoutTime" BU_SG_REL_ DACU SG_ 846 LFSREgoAssumpt_EgoRoadCurvRate 300;
BA_REL_ "GenSigFirstTimeoutTime" BU_SG_REL_ DACU SG_ 846 LFSREgoAssumpt_EgoYawRate 3000;
BA_REL_ "GenSigTimeoutTime" BU_SG_REL_ DACU SG_ 846 LFSREgoAssumpt_EgoYawRate 300;
BA_REL_ "GenSigFirstTimeoutTime" BU_SG_REL_ DACU SG_ 846 LFSREgoAssumpt_VelCorrFactor 3000;
BA_REL_ "GenSigTimeoutTime" BU_SG_REL_ DACU SG_ 846 LFSREgoAssumpt_VelCorrFactor 300;
BA_REL_ "GenSigFirstTimeoutTime" BU_SG_REL_ DACU SG_ 846 LFSREgoAssumpt_EgoRoadHeading 3000;
BA_REL_ "GenSigTimeoutTime" BU_SG_REL_ DACU SG_ 846 LFSREgoAssumpt_EgoRoadHeading 300;
BA_REL_ "GenSigFirstTimeoutTime" BU_SG_REL_ DACU SG_ 846 LFSREgoAssumpt_TimeStamp 3000;
BA_REL_ "GenSigTimeoutTime" BU_SG_REL_ DACU SG_ 846 LFSREgoAssumpt_TimeStamp 300;
BA_REL_ "GenSigFirstTimeoutTime" BU_SG_REL_ DACU SG_ 1523 DiagFaultStat_SRRR_DtcIdA 24000;
BA_REL_ "GenSigTimeoutTime" BU_SG_REL_ DACU SG_ 1523 DiagFaultStat_SRRR_DtcIdA 6000;
BA_REL_ "GenSigFirstTimeoutTime" BU_SG_REL_ DACU SG_ 1523 DiagFaultStat_SRRR_FailTB 24000;
BA_REL_ "GenSigTimeoutTime" BU_SG_REL_ DACU SG_ 1523 DiagFaultStat_SRRR_FailTB 6000;
BA_REL_ "GenSigFirstTimeoutTime" BU_SG_REL_ DACU SG_ 1523 DiagFaultStat_SRRR_DtcIdB 24000;
BA_REL_ "GenSigTimeoutTime" BU_SG_REL_ DACU SG_ 1523 DiagFaultStat_SRRR_DtcIdB 6000;
BA_REL_ "GenSigFirstTimeoutTime" BU_SG_REL_ DACU SG_ 1523 DiagFaultStat_SRRR_FailTA 24000;
BA_REL_ "GenSigTimeoutTime" BU_SG_REL_ DACU SG_ 1523 DiagFaultStat_SRRR_FailTA 6000;
BA_REL_ "GenSigFirstTimeoutTime" BU_SG_REL_ DACU SG_ 1523 DiagFaultStat_SRRR_EcuAdr 24000;
BA_REL_ "GenSigTimeoutTime" BU_SG_REL_ DACU SG_ 1523 DiagFaultStat_SRRR_EcuAdr 6000;
BA_REL_ "GenSigFirstTimeoutTime" BU_SG_REL_ DACU SG_ 1522 DiagFaultStat_SRRF_FailTA 24000;
BA_REL_ "GenSigTimeoutTime" BU_SG_REL_ DACU SG_ 1522 DiagFaultStat_SRRF_FailTA 6000;
BA_REL_ "GenSigFirstTimeoutTime" BU_SG_REL_ DACU SG_ 1522 DiagFaultStat_SRRF_DtcIdA 24000;
BA_REL_ "GenSigTimeoutTime" BU_SG_REL_ DACU SG_ 1522 DiagFaultStat_SRRF_DtcIdA 6000;
BA_REL_ "GenSigFirstTimeoutTime" BU_SG_REL_ DACU SG_ 1522 DiagFaultStat_SRRF_FailTB 24000;
BA_REL_ "GenSigTimeoutTime" BU_SG_REL_ DACU SG_ 1522 DiagFaultStat_SRRF_FailTB 6000;
BA_REL_ "GenSigFirstTimeoutTime" BU_SG_REL_ DACU SG_ 1522 DiagFaultStat_SRRF_EcuAdr 24000;
BA_REL_ "GenSigTimeoutTime" BU_SG_REL_ DACU SG_ 1522 DiagFaultStat_SRRF_EcuAdr 6000;
BA_REL_ "GenSigFirstTimeoutTime" BU_SG_REL_ DACU SG_ 1522 DiagFaultStat_SRRF_DtcIdB 24000;
BA_REL_ "GenSigTimeoutTime" BU_SG_REL_ DACU SG_ 1522 DiagFaultStat_SRRF_DtcIdB 6000;
BA_REL_ "GenSigFirstTimeoutTime" BU_SG_REL_ DACU SG_ 1521 DiagFaultStat_SRLR_FailTA 24000;
BA_REL_ "GenSigTimeoutTime" BU_SG_REL_ DACU SG_ 1521 DiagFaultStat_SRLR_FailTA 6000;
BA_REL_ "GenSigFirstTimeoutTime" BU_SG_REL_ DACU SG_ 1521 DiagFaultStat_SRLR_FailTB 24000;
BA_REL_ "GenSigTimeoutTime" BU_SG_REL_ DACU SG_ 1521 DiagFaultStat_SRLR_FailTB 6000;
BA_REL_ "GenSigFirstTimeoutTime" BU_SG_REL_ DACU SG_ 1521 DiagFaultStat_SRLR_EcuAdr 24000;
BA_REL_ "GenSigTimeoutTime" BU_SG_REL_ DACU SG_ 1521 DiagFaultStat_SRLR_EcuAdr 6000;
BA_REL_ "GenSigFirstTimeoutTime" BU_SG_REL_ DACU SG_ 1521 DiagFaultStat_SRLR_DtcIdA 24000;
BA_REL_ "GenSigTimeoutTime" BU_SG_REL_ DACU SG_ 1521 DiagFaultStat_SRLR_DtcIdA 6000;
BA_REL_ "GenSigFirstTimeoutTime" BU_SG_REL_ DACU SG_ 1521 DiagFaultStat_SRLR_DtcIdB 24000;
BA_REL_ "GenSigTimeoutTime" BU_SG_REL_ DACU SG_ 1521 DiagFaultStat_SRLR_DtcIdB 6000;
BA_REL_ "GenSigFirstTimeoutTime" BU_SG_REL_ DACU SG_ 1524 DiagFaultStat_SRLF_DtcIdA 24000;
BA_REL_ "GenSigTimeoutTime" BU_SG_REL_ DACU SG_ 1524 DiagFaultStat_SRLF_DtcIdA 6000;
BA_REL_ "GenSigFirstTimeoutTime" BU_SG_REL_ DACU SG_ 1524 DiagFaultStat_SRLF_FailTA 24000;
BA_REL_ "GenSigTimeoutTime" BU_SG_REL_ DACU SG_ 1524 DiagFaultStat_SRLF_FailTA 6000;
BA_REL_ "GenSigFirstTimeoutTime" BU_SG_REL_ DACU SG_ 1524 DiagFaultStat_SRLF_FailTB 24000;
BA_REL_ "GenSigTimeoutTime" BU_SG_REL_ DACU SG_ 1524 DiagFaultStat_SRLF_FailTB 6000;
BA_REL_ "GenSigFirstTimeoutTime" BU_SG_REL_ DACU SG_ 1524 DiagFaultStat_SRLF_DtcIdB 24000;
BA_REL_ "GenSigTimeoutTime" BU_SG_REL_ DACU SG_ 1524 DiagFaultStat_SRLF_DtcIdB 6000;
BA_REL_ "GenSigFirstTimeoutTime" BU_SG_REL_ DACU SG_ 1524 DiagFaultStat_SRLF_EcuAdr 24000;
BA_REL_ "GenSigTimeoutTime" BU_SG_REL_ DACU SG_ 1524 DiagFaultStat_SRLF_EcuAdr 6000;
BA_REL_ "GenSigFirstTimeoutTime" BU_SG_REL_ SR_RR SG_ 279 EgoPathPrediction_DxEnd 3000;
BA_REL_ "GenSigTimeoutTime" BU_SG_REL_ SR_RR SG_ 279 EgoPathPrediction_DxEnd 600;
BA_REL_ "GenSigFirstTimeoutTime" BU_SG_REL_ SR_LF SG_ 279 EgoPathPrediction_DxEnd 3000;
BA_REL_ "GenSigTimeoutTime" BU_SG_REL_ SR_LF SG_ 279 EgoPathPrediction_DxEnd 600;
BA_REL_ "GenSigFirstTimeoutTime" BU_SG_REL_ SR_RF SG_ 279 EgoPathPrediction_DxEnd 3000;
BA_REL_ "GenSigTimeoutTime" BU_SG_REL_ SR_RF SG_ 279 EgoPathPrediction_DxEnd 600;
BA_REL_ "GenSigFirstTimeoutTime" BU_SG_REL_ SR_LR SG_ 279 EgoPathPrediction_DxEnd 3000;
BA_REL_ "GenSigTimeoutTime" BU_SG_REL_ SR_LR SG_ 279 EgoPathPrediction_DxEnd 600;
BA_REL_ "GenSigFirstTimeoutTime" BU_SG_REL_ SR_RR SG_ 279 EgoPathPrediction_ConfCoeffA1 3000;
BA_REL_ "GenSigTimeoutTime" BU_SG_REL_ SR_RR SG_ 279 EgoPathPrediction_ConfCoeffA1 600;
BA_REL_ "GenSigFirstTimeoutTime" BU_SG_REL_ SR_LR SG_ 279 EgoPathPrediction_ConfCoeffA1 3000;
BA_REL_ "GenSigTimeoutTime" BU_SG_REL_ SR_LR SG_ 279 EgoPathPrediction_ConfCoeffA1 600;
BA_REL_ "GenSigFirstTimeoutTime" BU_SG_REL_ SR_RF SG_ 279 EgoPathPrediction_ConfCoeffA1 3000;
BA_REL_ "GenSigTimeoutTime" BU_SG_REL_ SR_RF SG_ 279 EgoPathPrediction_ConfCoeffA1 600;
BA_REL_ "GenSigFirstTimeoutTime" BU_SG_REL_ SR_LF SG_ 279 EgoPathPrediction_ConfCoeffA1 3000;
BA_REL_ "GenSigTimeoutTime" BU_SG_REL_ SR_LF SG_ 279 EgoPathPrediction_ConfCoeffA1 600;
BA_REL_ "GenSigFirstTimeoutTime" BU_SG_REL_ SR_LF SG_ 279 EgoPathPrediction_ConfCoeffA0 3000;
BA_REL_ "GenSigTimeoutTime" BU_SG_REL_ SR_LF SG_ 279 EgoPathPrediction_ConfCoeffA0 600;
BA_REL_ "GenSigFirstTimeoutTime" BU_SG_REL_ SR_LR SG_ 279 EgoPathPrediction_ConfCoeffA0 3000;
BA_REL_ "GenSigTimeoutTime" BU_SG_REL_ SR_LR SG_ 279 EgoPathPrediction_ConfCoeffA0 600;
BA_REL_ "GenSigFirstTimeoutTime" BU_SG_REL_ SR_RR SG_ 279 EgoPathPrediction_ConfCoeffA0 3000;
BA_REL_ "GenSigTimeoutTime" BU_SG_REL_ SR_RR SG_ 279 EgoPathPrediction_ConfCoeffA0 600;
BA_REL_ "GenSigFirstTimeoutTime" BU_SG_REL_ SR_RF SG_ 279 EgoPathPrediction_ConfCoeffA0 3000;
BA_REL_ "GenSigTimeoutTime" BU_SG_REL_ SR_RF SG_ 279 EgoPathPrediction_ConfCoeffA0 600;
BA_REL_ "GenSigFirstTimeoutTime" BU_SG_REL_ SR_LR SG_ 279 EgoPathPrediction_ConfCoeffA2 3000;
BA_REL_ "GenSigTimeoutTime" BU_SG_REL_ SR_LR SG_ 279 EgoPathPrediction_ConfCoeffA2 600;
BA_REL_ "GenSigFirstTimeoutTime" BU_SG_REL_ SR_RF SG_ 279 EgoPathPrediction_ConfCoeffA2 3000;
BA_REL_ "GenSigTimeoutTime" BU_SG_REL_ SR_RF SG_ 279 EgoPathPrediction_ConfCoeffA2 600;
BA_REL_ "GenSigFirstTimeoutTime" BU_SG_REL_ SR_LF SG_ 279 EgoPathPrediction_ConfCoeffA2 3000;
BA_REL_ "GenSigTimeoutTime" BU_SG_REL_ SR_LF SG_ 279 EgoPathPrediction_ConfCoeffA2 600;
BA_REL_ "GenSigFirstTimeoutTime" BU_SG_REL_ SR_RR SG_ 279 EgoPathPrediction_ConfCoeffA2 3000;
BA_REL_ "GenSigTimeoutTime" BU_SG_REL_ SR_RR SG_ 279 EgoPathPrediction_ConfCoeffA2 600;
BA_REL_ "GenSigFirstTimeoutTime" BU_SG_REL_ SR_RF SG_ 279 EgoPathPrediction_Curvature 3000;
BA_REL_ "GenSigTimeoutTime" BU_SG_REL_ SR_RF SG_ 279 EgoPathPrediction_Curvature 600;
BA_REL_ "GenSigFirstTimeoutTime" BU_SG_REL_ SR_LR SG_ 279 EgoPathPrediction_Curvature 3000;
BA_REL_ "GenSigTimeoutTime" BU_SG_REL_ SR_LR SG_ 279 EgoPathPrediction_Curvature 600;
BA_REL_ "GenSigFirstTimeoutTime" BU_SG_REL_ SR_RR SG_ 279 EgoPathPrediction_Curvature 3000;
BA_REL_ "GenSigTimeoutTime" BU_SG_REL_ SR_RR SG_ 279 EgoPathPrediction_Curvature 600;
BA_REL_ "GenSigFirstTimeoutTime" BU_SG_REL_ SR_LF SG_ 279 EgoPathPrediction_Curvature 3000;
BA_REL_ "GenSigTimeoutTime" BU_SG_REL_ SR_LF SG_ 279 EgoPathPrediction_Curvature 600;
BA_REL_ "GenSigFirstTimeoutTime" BU_SG_REL_ SR_LF SG_ 279 EgoPathPrediction_HeadingAngle 3000;
BA_REL_ "GenSigTimeoutTime" BU_SG_REL_ SR_LF SG_ 279 EgoPathPrediction_HeadingAngle 600;
BA_REL_ "GenSigFirstTimeoutTime" BU_SG_REL_ SR_LR SG_ 279 EgoPathPrediction_HeadingAngle 3000;
BA_REL_ "GenSigTimeoutTime" BU_SG_REL_ SR_LR SG_ 279 EgoPathPrediction_HeadingAngle 600;
BA_REL_ "GenSigFirstTimeoutTime" BU_SG_REL_ SR_RF SG_ 279 EgoPathPrediction_HeadingAngle 3000;
BA_REL_ "GenSigTimeoutTime" BU_SG_REL_ SR_RF SG_ 279 EgoPathPrediction_HeadingAngle 600;
BA_REL_ "GenSigFirstTimeoutTime" BU_SG_REL_ SR_RR SG_ 279 EgoPathPrediction_HeadingAngle 3000;
BA_REL_ "GenSigTimeoutTime" BU_SG_REL_ SR_RR SG_ 279 EgoPathPrediction_HeadingAngle 600;
BA_REL_ "GenSigFirstTimeoutTime" BU_SG_REL_ SR_RR SG_ 279 EgoPathPrediction_ConfCoeffA3 3000;
BA_REL_ "GenSigTimeoutTime" BU_SG_REL_ SR_RR SG_ 279 EgoPathPrediction_ConfCoeffA3 600;
BA_REL_ "GenSigFirstTimeoutTime" BU_SG_REL_ SR_RF SG_ 279 EgoPathPrediction_ConfCoeffA3 3000;
BA_REL_ "GenSigTimeoutTime" BU_SG_REL_ SR_RF SG_ 279 EgoPathPrediction_ConfCoeffA3 600;
BA_REL_ "GenSigFirstTimeoutTime" BU_SG_REL_ SR_LR SG_ 279 EgoPathPrediction_ConfCoeffA3 3000;
BA_REL_ "GenSigTimeoutTime" BU_SG_REL_ SR_LR SG_ 279 EgoPathPrediction_ConfCoeffA3 600;
BA_REL_ "GenSigFirstTimeoutTime" BU_SG_REL_ SR_LF SG_ 279 EgoPathPrediction_ConfCoeffA3 3000;
BA_REL_ "GenSigTimeoutTime" BU_SG_REL_ SR_LF SG_ 279 EgoPathPrediction_ConfCoeffA3 600;
BA_REL_ "GenSigFirstTimeoutTime" BU_SG_REL_ SR_RF SG_ 279 EgoPathPrediction_CurvatureRate 3000;
BA_REL_ "GenSigTimeoutTime" BU_SG_REL_ SR_RF SG_ 279 EgoPathPrediction_CurvatureRate 600;
BA_REL_ "GenSigFirstTimeoutTime" BU_SG_REL_ SR_RR SG_ 279 EgoPathPrediction_CurvatureRate 3000;
BA_REL_ "GenSigTimeoutTime" BU_SG_REL_ SR_RR SG_ 279 EgoPathPrediction_CurvatureRate 600;
BA_REL_ "GenSigFirstTimeoutTime" BU_SG_REL_ SR_LR SG_ 279 EgoPathPrediction_CurvatureRate 3000;
BA_REL_ "GenSigTimeoutTime" BU_SG_REL_ SR_LR SG_ 279 EgoPathPrediction_CurvatureRate 600;
BA_REL_ "GenSigFirstTimeoutTime" BU_SG_REL_ SR_LF SG_ 279 EgoPathPrediction_CurvatureRate 3000;
BA_REL_ "GenSigTimeoutTime" BU_SG_REL_ SR_LF SG_ 279 EgoPathPrediction_CurvatureRate 600;
BA_REL_ "GenSigFirstTimeoutTime" BU_SG_REL_ SR_LR SG_ 275 EgoMotionXYplane_LateralAcc 3000;
BA_REL_ "GenSigTimeoutTime" BU_SG_REL_ SR_LR SG_ 275 EgoMotionXYplane_LateralAcc 100;
BA_REL_ "GenSigFirstTimeoutTime" BU_SG_REL_ SR_RR SG_ 275 EgoMotionXYplane_LateralAcc 3000;
BA_REL_ "GenSigTimeoutTime" BU_SG_REL_ SR_RR SG_ 275 EgoMotionXYplane_LateralAcc 100;
BA_REL_ "GenSigFirstTimeoutTime" BU_SG_REL_ SR_RF SG_ 275 EgoMotionXYplane_LateralAcc 3000;
BA_REL_ "GenSigTimeoutTime" BU_SG_REL_ SR_RF SG_ 275 EgoMotionXYplane_LateralAcc 100;
BA_REL_ "GenSigFirstTimeoutTime" BU_SG_REL_ SR_LF SG_ 275 EgoMotionXYplane_LateralAcc 3000;
BA_REL_ "GenSigTimeoutTime" BU_SG_REL_ SR_LF SG_ 275 EgoMotionXYplane_LateralAcc 100;
BA_REL_ "GenSigFirstTimeoutTime" BU_SG_REL_ SR_LF SG_ 275 EgoMotionXYplane_LongAcc 3000;
BA_REL_ "GenSigTimeoutTime" BU_SG_REL_ SR_LF SG_ 275 EgoMotionXYplane_LongAcc 100;
BA_REL_ "GenSigFirstTimeoutTime" BU_SG_REL_ SR_LR SG_ 275 EgoMotionXYplane_LongAcc 3000;
BA_REL_ "GenSigTimeoutTime" BU_SG_REL_ SR_LR SG_ 275 EgoMotionXYplane_LongAcc 100;
BA_REL_ "GenSigFirstTimeoutTime" BU_SG_REL_ SR_RR SG_ 275 EgoMotionXYplane_LongAcc 3000;
BA_REL_ "GenSigTimeoutTime" BU_SG_REL_ SR_RR SG_ 275 EgoMotionXYplane_LongAcc 100;
BA_REL_ "GenSigFirstTimeoutTime" BU_SG_REL_ SR_RF SG_ 275 EgoMotionXYplane_LongAcc 3000;
BA_REL_ "GenSigTimeoutTime" BU_SG_REL_ SR_RF SG_ 275 EgoMotionXYplane_LongAcc 100;
BA_REL_ "GenSigFirstTimeoutTime" BU_SG_REL_ SR_RF SG_ 275 EgoMotionXYplane_LongSpeed 3000;
BA_REL_ "GenSigTimeoutTime" BU_SG_REL_ SR_RF SG_ 275 EgoMotionXYplane_LongSpeed 100;
BA_REL_ "GenSigFirstTimeoutTime" BU_SG_REL_ SR_LR SG_ 275 EgoMotionXYplane_LongSpeed 3000;
BA_REL_ "GenSigTimeoutTime" BU_SG_REL_ SR_LR SG_ 275 EgoMotionXYplane_LongSpeed 100;
BA_REL_ "GenSigFirstTimeoutTime" BU_SG_REL_ SR_LF SG_ 275 EgoMotionXYplane_LongSpeed 3000;
BA_REL_ "GenSigTimeoutTime" BU_SG_REL_ SR_LF SG_ 275 EgoMotionXYplane_LongSpeed 100;
BA_REL_ "GenSigFirstTimeoutTime" BU_SG_REL_ SR_RR SG_ 275 EgoMotionXYplane_LongSpeed 3000;
BA_REL_ "GenSigTimeoutTime" BU_SG_REL_ SR_RR SG_ 275 EgoMotionXYplane_LongSpeed 100;
BA_REL_ "GenSigFirstTimeoutTime" BU_SG_REL_ SR_LF SG_ 275 EgoMotionXYplane_LongMotDirConf 3000;
BA_REL_ "GenSigTimeoutTime" BU_SG_REL_ SR_LF SG_ 275 EgoMotionXYplane_LongMotDirConf 100;
BA_REL_ "GenSigFirstTimeoutTime" BU_SG_REL_ SR_RR SG_ 275 EgoMotionXYplane_LongMotDirConf 3000;
BA_REL_ "GenSigTimeoutTime" BU_SG_REL_ SR_RR SG_ 275 EgoMotionXYplane_LongMotDirConf 100;
BA_REL_ "GenSigFirstTimeoutTime" BU_SG_REL_ SR_LR SG_ 275 EgoMotionXYplane_LongMotDirConf 3000;
BA_REL_ "GenSigTimeoutTime" BU_SG_REL_ SR_LR SG_ 275 EgoMotionXYplane_LongMotDirConf 100;
BA_REL_ "GenSigFirstTimeoutTime" BU_SG_REL_ SR_RF SG_ 275 EgoMotionXYplane_LongMotDirConf 3000;
BA_REL_ "GenSigTimeoutTime" BU_SG_REL_ SR_RF SG_ 275 EgoMotionXYplane_LongMotDirConf 100;
BA_REL_ "GenSigFirstTimeoutTime" BU_SG_REL_ SR_RR SG_ 275 EgoMotionXYplane_Curvature 3000;
BA_REL_ "GenSigTimeoutTime" BU_SG_REL_ SR_RR SG_ 275 EgoMotionXYplane_Curvature 100;
BA_REL_ "GenSigFirstTimeoutTime" BU_SG_REL_ SR_LR SG_ 275 EgoMotionXYplane_Curvature 3000;
BA_REL_ "GenSigTimeoutTime" BU_SG_REL_ SR_LR SG_ 275 EgoMotionXYplane_Curvature 100;
BA_REL_ "GenSigFirstTimeoutTime" BU_SG_REL_ SR_LF SG_ 275 EgoMotionXYplane_Curvature 3000;
BA_REL_ "GenSigTimeoutTime" BU_SG_REL_ SR_LF SG_ 275 EgoMotionXYplane_Curvature 100;
BA_REL_ "GenSigFirstTimeoutTime" BU_SG_REL_ SR_RF SG_ 275 EgoMotionXYplane_Curvature 3000;
BA_REL_ "GenSigTimeoutTime" BU_SG_REL_ SR_RF SG_ 275 EgoMotionXYplane_Curvature 100;
BA_REL_ "GenSigFirstTimeoutTime" BU_SG_REL_ SR_RF SG_ 275 EgoMotionXYplane_EffectiveWheelB 3000;
BA_REL_ "GenSigTimeoutTime" BU_SG_REL_ SR_RF SG_ 275 EgoMotionXYplane_EffectiveWheelB 100;
BA_REL_ "GenSigFirstTimeoutTime" BU_SG_REL_ SR_RR SG_ 275 EgoMotionXYplane_EffectiveWheelB 3000;
BA_REL_ "GenSigTimeoutTime" BU_SG_REL_ SR_RR SG_ 275 EgoMotionXYplane_EffectiveWheelB 100;
BA_REL_ "GenSigFirstTimeoutTime" BU_SG_REL_ SR_LF SG_ 275 EgoMotionXYplane_EffectiveWheelB 3000;
BA_REL_ "GenSigTimeoutTime" BU_SG_REL_ SR_LF SG_ 275 EgoMotionXYplane_EffectiveWheelB 100;
BA_REL_ "GenSigFirstTimeoutTime" BU_SG_REL_ SR_LR SG_ 275 EgoMotionXYplane_EffectiveWheelB 3000;
BA_REL_ "GenSigTimeoutTime" BU_SG_REL_ SR_LR SG_ 275 EgoMotionXYplane_EffectiveWheelB 100;
BA_REL_ "GenSigFirstTimeoutTime" BU_SG_REL_ SR_RR SG_ 275 EgoMotionXYplane_LongMotionDir 3000;
BA_REL_ "GenSigTimeoutTime" BU_SG_REL_ SR_RR SG_ 275 EgoMotionXYplane_LongMotionDir 100;
BA_REL_ "GenSigFirstTimeoutTime" BU_SG_REL_ SR_LF SG_ 275 EgoMotionXYplane_LongMotionDir 3000;
BA_REL_ "GenSigTimeoutTime" BU_SG_REL_ SR_LF SG_ 275 EgoMotionXYplane_LongMotionDir 100;
BA_REL_ "GenSigFirstTimeoutTime" BU_SG_REL_ SR_LR SG_ 275 EgoMotionXYplane_LongMotionDir 3000;
BA_REL_ "GenSigTimeoutTime" BU_SG_REL_ SR_LR SG_ 275 EgoMotionXYplane_LongMotionDir 100;
BA_REL_ "GenSigFirstTimeoutTime" BU_SG_REL_ SR_RF SG_ 275 EgoMotionXYplane_LongMotionDir 3000;
BA_REL_ "GenSigTimeoutTime" BU_SG_REL_ SR_RF SG_ 275 EgoMotionXYplane_LongMotionDir 100;
BA_REL_ "GenSigFirstTimeoutTime" BU_SG_REL_ SR_RR SG_ 275 EgoMotionXYplane_LongSpeedVar 3000;
BA_REL_ "GenSigTimeoutTime" BU_SG_REL_ SR_RR SG_ 275 EgoMotionXYplane_LongSpeedVar 100;
BA_REL_ "GenSigFirstTimeoutTime" BU_SG_REL_ SR_LF SG_ 275 EgoMotionXYplane_LongSpeedVar 3000;
BA_REL_ "GenSigTimeoutTime" BU_SG_REL_ SR_LF SG_ 275 EgoMotionXYplane_LongSpeedVar 100;
BA_REL_ "GenSigFirstTimeoutTime" BU_SG_REL_ SR_RF SG_ 275 EgoMotionXYplane_LongSpeedVar 3000;
BA_REL_ "GenSigTimeoutTime" BU_SG_REL_ SR_RF SG_ 275 EgoMotionXYplane_LongSpeedVar 100;
BA_REL_ "GenSigFirstTimeoutTime" BU_SG_REL_ SR_LR SG_ 275 EgoMotionXYplane_LongSpeedVar 3000;
BA_REL_ "GenSigTimeoutTime" BU_SG_REL_ SR_LR SG_ 275 EgoMotionXYplane_LongSpeedVar 100;
BA_REL_ "GenSigFirstTimeoutTime" BU_SG_REL_ SR_RF SG_ 275 EgoMotionXYplane_Counter 3000;
BA_REL_ "GenSigTimeoutTime" BU_SG_REL_ SR_RF SG_ 275 EgoMotionXYplane_Counter 100;
BA_REL_ "GenSigFirstTimeoutTime" BU_SG_REL_ SR_LF SG_ 275 EgoMotionXYplane_Counter 3000;
BA_REL_ "GenSigTimeoutTime" BU_SG_REL_ SR_LF SG_ 275 EgoMotionXYplane_Counter 100;
BA_REL_ "GenSigFirstTimeoutTime" BU_SG_REL_ SR_LR SG_ 275 EgoMotionXYplane_Counter 3000;
BA_REL_ "GenSigTimeoutTime" BU_SG_REL_ SR_LR SG_ 275 EgoMotionXYplane_Counter 100;
BA_REL_ "GenSigFirstTimeoutTime" BU_SG_REL_ SR_RR SG_ 275 EgoMotionXYplane_Counter 3000;
BA_REL_ "GenSigTimeoutTime" BU_SG_REL_ SR_RR SG_ 275 EgoMotionXYplane_Counter 100;
BA_REL_ "GenSigFirstTimeoutTime" BU_SG_REL_ SR_LF SG_ 275 EgoMotionXYplane_LatencyEst 3000;
BA_REL_ "GenSigTimeoutTime" BU_SG_REL_ SR_LF SG_ 275 EgoMotionXYplane_LatencyEst 100;
BA_REL_ "GenSigFirstTimeoutTime" BU_SG_REL_ SR_RF SG_ 275 EgoMotionXYplane_LatencyEst 3000;
BA_REL_ "GenSigTimeoutTime" BU_SG_REL_ SR_RF SG_ 275 EgoMotionXYplane_LatencyEst 100;
BA_REL_ "GenSigFirstTimeoutTime" BU_SG_REL_ SR_RR SG_ 275 EgoMotionXYplane_LatencyEst 3000;
BA_REL_ "GenSigTimeoutTime" BU_SG_REL_ SR_RR SG_ 275 EgoMotionXYplane_LatencyEst 100;
BA_REL_ "GenSigFirstTimeoutTime" BU_SG_REL_ SR_LR SG_ 275 EgoMotionXYplane_LatencyEst 3000;
BA_REL_ "GenSigTimeoutTime" BU_SG_REL_ SR_LR SG_ 275 EgoMotionXYplane_LatencyEst 100;
BA_REL_ "GenSigFirstTimeoutTime" BU_SG_REL_ SR_LF SG_ 275 EgoMotionXYplane_LatAccVariance 3000;
BA_REL_ "GenSigTimeoutTime" BU_SG_REL_ SR_LF SG_ 275 EgoMotionXYplane_LatAccVariance 100;
BA_REL_ "GenSigFirstTimeoutTime" BU_SG_REL_ SR_RR SG_ 275 EgoMotionXYplane_LatAccVariance 3000;
BA_REL_ "GenSigTimeoutTime" BU_SG_REL_ SR_RR SG_ 275 EgoMotionXYplane_LatAccVariance 100;
BA_REL_ "GenSigFirstTimeoutTime" BU_SG_REL_ SR_RF SG_ 275 EgoMotionXYplane_LatAccVariance 3000;
BA_REL_ "GenSigTimeoutTime" BU_SG_REL_ SR_RF SG_ 275 EgoMotionXYplane_LatAccVariance 100;
BA_REL_ "GenSigFirstTimeoutTime" BU_SG_REL_ SR_LR SG_ 275 EgoMotionXYplane_LatAccVariance 3000;
BA_REL_ "GenSigTimeoutTime" BU_SG_REL_ SR_LR SG_ 275 EgoMotionXYplane_LatAccVariance 100;
BA_REL_ "GenSigFirstTimeoutTime" BU_SG_REL_ SR_RF SG_ 275 EgoMotionXYplane_CRC 3000;
BA_REL_ "GenSigTimeoutTime" BU_SG_REL_ SR_RF SG_ 275 EgoMotionXYplane_CRC 100;
BA_REL_ "GenSigFirstTimeoutTime" BU_SG_REL_ SR_LR SG_ 275 EgoMotionXYplane_CRC 3000;
BA_REL_ "GenSigTimeoutTime" BU_SG_REL_ SR_LR SG_ 275 EgoMotionXYplane_CRC 100;
BA_REL_ "GenSigFirstTimeoutTime" BU_SG_REL_ SR_LF SG_ 275 EgoMotionXYplane_CRC 3000;
BA_REL_ "GenSigTimeoutTime" BU_SG_REL_ SR_LF SG_ 275 EgoMotionXYplane_CRC 100;
BA_REL_ "GenSigFirstTimeoutTime" BU_SG_REL_ SR_RR SG_ 275 EgoMotionXYplane_CRC 3000;
BA_REL_ "GenSigTimeoutTime" BU_SG_REL_ SR_RR SG_ 275 EgoMotionXYplane_CRC 100;
BA_REL_ "GenSigFirstTimeoutTime" BU_SG_REL_ SR_RR SG_ 275 EgoMotionXYplane_ReferencePointX 3000;
BA_REL_ "GenSigTimeoutTime" BU_SG_REL_ SR_RR SG_ 275 EgoMotionXYplane_ReferencePointX 100;
BA_REL_ "GenSigFirstTimeoutTime" BU_SG_REL_ SR_LF SG_ 275 EgoMotionXYplane_ReferencePointX 3000;
BA_REL_ "GenSigTimeoutTime" BU_SG_REL_ SR_LF SG_ 275 EgoMotionXYplane_ReferencePointX 100;
BA_REL_ "GenSigFirstTimeoutTime" BU_SG_REL_ SR_RF SG_ 275 EgoMotionXYplane_ReferencePointX 3000;
BA_REL_ "GenSigTimeoutTime" BU_SG_REL_ SR_RF SG_ 275 EgoMotionXYplane_ReferencePointX 100;
BA_REL_ "GenSigFirstTimeoutTime" BU_SG_REL_ SR_LR SG_ 275 EgoMotionXYplane_ReferencePointX 3000;
BA_REL_ "GenSigTimeoutTime" BU_SG_REL_ SR_LR SG_ 275 EgoMotionXYplane_ReferencePointX 100;
BA_REL_ "GenSigFirstTimeoutTime" BU_SG_REL_ SR_LF SG_ 275 EgoMotionXYplane_LateralSpeed 3000;
BA_REL_ "GenSigTimeoutTime" BU_SG_REL_ SR_LF SG_ 275 EgoMotionXYplane_LateralSpeed 100;
BA_REL_ "GenSigFirstTimeoutTime" BU_SG_REL_ SR_RR SG_ 275 EgoMotionXYplane_LateralSpeed 3000;
BA_REL_ "GenSigTimeoutTime" BU_SG_REL_ SR_RR SG_ 275 EgoMotionXYplane_LateralSpeed 100;
BA_REL_ "GenSigFirstTimeoutTime" BU_SG_REL_ SR_RF SG_ 275 EgoMotionXYplane_LateralSpeed 3000;
BA_REL_ "GenSigTimeoutTime" BU_SG_REL_ SR_RF SG_ 275 EgoMotionXYplane_LateralSpeed 100;
BA_REL_ "GenSigFirstTimeoutTime" BU_SG_REL_ SR_LR SG_ 275 EgoMotionXYplane_LateralSpeed 3000;
BA_REL_ "GenSigTimeoutTime" BU_SG_REL_ SR_LR SG_ 275 EgoMotionXYplane_LateralSpeed 100;
BA_REL_ "GenSigFirstTimeoutTime" BU_SG_REL_ SR_RF SG_ 275 EgoMotionXYplane_LatSpeedVar 3000;
BA_REL_ "GenSigTimeoutTime" BU_SG_REL_ SR_RF SG_ 275 EgoMotionXYplane_LatSpeedVar 100;
BA_REL_ "GenSigFirstTimeoutTime" BU_SG_REL_ SR_LF SG_ 275 EgoMotionXYplane_LatSpeedVar 3000;
BA_REL_ "GenSigTimeoutTime" BU_SG_REL_ SR_LF SG_ 275 EgoMotionXYplane_LatSpeedVar 100;
BA_REL_ "GenSigFirstTimeoutTime" BU_SG_REL_ SR_LR SG_ 275 EgoMotionXYplane_LatSpeedVar 3000;
BA_REL_ "GenSigTimeoutTime" BU_SG_REL_ SR_LR SG_ 275 EgoMotionXYplane_LatSpeedVar 100;
BA_REL_ "GenSigFirstTimeoutTime" BU_SG_REL_ SR_RR SG_ 275 EgoMotionXYplane_LatSpeedVar 3000;
BA_REL_ "GenSigTimeoutTime" BU_SG_REL_ SR_RR SG_ 275 EgoMotionXYplane_LatSpeedVar 100;
BA_REL_ "GenSigFirstTimeoutTime" BU_SG_REL_ SR_LR SG_ 275 EgoMotionXYplane_YawRateComp 3000;
BA_REL_ "GenSigTimeoutTime" BU_SG_REL_ SR_LR SG_ 275 EgoMotionXYplane_YawRateComp 100;
BA_REL_ "GenSigFirstTimeoutTime" BU_SG_REL_ SR_RR SG_ 275 EgoMotionXYplane_YawRateComp 3000;
BA_REL_ "GenSigTimeoutTime" BU_SG_REL_ SR_RR SG_ 275 EgoMotionXYplane_YawRateComp 100;
BA_REL_ "GenSigFirstTimeoutTime" BU_SG_REL_ SR_RF SG_ 275 EgoMotionXYplane_YawRateComp 3000;
BA_REL_ "GenSigTimeoutTime" BU_SG_REL_ SR_RF SG_ 275 EgoMotionXYplane_YawRateComp 100;
BA_REL_ "GenSigFirstTimeoutTime" BU_SG_REL_ SR_LF SG_ 275 EgoMotionXYplane_YawRateComp 3000;
BA_REL_ "GenSigTimeoutTime" BU_SG_REL_ SR_LF SG_ 275 EgoMotionXYplane_YawRateComp 100;
BA_REL_ "GenSigFirstTimeoutTime" BU_SG_REL_ SR_RF SG_ 275 EgoMotionXYplane_ChassisDynPitch 3000;
BA_REL_ "GenSigTimeoutTime" BU_SG_REL_ SR_RF SG_ 275 EgoMotionXYplane_ChassisDynPitch 100;
BA_REL_ "GenSigFirstTimeoutTime" BU_SG_REL_ SR_RR SG_ 275 EgoMotionXYplane_ChassisDynPitch 3000;
BA_REL_ "GenSigTimeoutTime" BU_SG_REL_ SR_RR SG_ 275 EgoMotionXYplane_ChassisDynPitch 100;
BA_REL_ "GenSigFirstTimeoutTime" BU_SG_REL_ SR_LR SG_ 275 EgoMotionXYplane_ChassisDynPitch 3000;
BA_REL_ "GenSigTimeoutTime" BU_SG_REL_ SR_LR SG_ 275 EgoMotionXYplane_ChassisDynPitch 100;
BA_REL_ "GenSigFirstTimeoutTime" BU_SG_REL_ SR_LF SG_ 275 EgoMotionXYplane_ChassisDynPitch 3000;
BA_REL_ "GenSigTimeoutTime" BU_SG_REL_ SR_LF SG_ 275 EgoMotionXYplane_ChassisDynPitch 100;
BA_REL_ "GenSigFirstTimeoutTime" BU_SG_REL_ SR_LF SG_ 275 EgoMotionXYplane_YawRateVariance 3000;
BA_REL_ "GenSigTimeoutTime" BU_SG_REL_ SR_LF SG_ 275 EgoMotionXYplane_YawRateVariance 100;
BA_REL_ "GenSigFirstTimeoutTime" BU_SG_REL_ SR_LR SG_ 275 EgoMotionXYplane_YawRateVariance 3000;
BA_REL_ "GenSigTimeoutTime" BU_SG_REL_ SR_LR SG_ 275 EgoMotionXYplane_YawRateVariance 100;
BA_REL_ "GenSigFirstTimeoutTime" BU_SG_REL_ SR_RR SG_ 275 EgoMotionXYplane_YawRateVariance 3000;
BA_REL_ "GenSigTimeoutTime" BU_SG_REL_ SR_RR SG_ 275 EgoMotionXYplane_YawRateVariance 100;
BA_REL_ "GenSigFirstTimeoutTime" BU_SG_REL_ SR_RF SG_ 275 EgoMotionXYplane_YawRateVariance 3000;
BA_REL_ "GenSigTimeoutTime" BU_SG_REL_ SR_RF SG_ 275 EgoMotionXYplane_YawRateVariance 100;
BA_REL_ "GenSigFirstTimeoutTime" BU_SG_REL_ SR_LF SG_ 275 EgoMotionXYplane_LongAccVariance 3000;
BA_REL_ "GenSigTimeoutTime" BU_SG_REL_ SR_LF SG_ 275 EgoMotionXYplane_LongAccVariance 100;
BA_REL_ "GenSigFirstTimeoutTime" BU_SG_REL_ SR_RR SG_ 275 EgoMotionXYplane_LongAccVariance 3000;
BA_REL_ "GenSigTimeoutTime" BU_SG_REL_ SR_RR SG_ 275 EgoMotionXYplane_LongAccVariance 100;
BA_REL_ "GenSigFirstTimeoutTime" BU_SG_REL_ SR_LR SG_ 275 EgoMotionXYplane_LongAccVariance 3000;
BA_REL_ "GenSigTimeoutTime" BU_SG_REL_ SR_LR SG_ 275 EgoMotionXYplane_LongAccVariance 100;
BA_REL_ "GenSigFirstTimeoutTime" BU_SG_REL_ SR_RF SG_ 275 EgoMotionXYplane_LongAccVariance 3000;
BA_REL_ "GenSigTimeoutTime" BU_SG_REL_ SR_RF SG_ 275 EgoMotionXYplane_LongAccVariance 100;
VAL_ 842 LFSideSensorObj10_Prioritisation 3 "Prioritisation_NotAvailable" 2 "Prioritisation_StaticPrioritisation" 1 "Prioritisation_VolvoPrioritisation" 0 "Prioritisation_BoschPrioritisation" ;
VAL_ 842 LFSideSensorObj10_ObjDynClass 3 "ObjDynClass_Error" 2 "ObjDynClass_Movable" 1 "ObjDynClass_Stationary" 0 "ObjDynClass_Reserved" ;
VAL_ 842 LFSideSensorObj10_TrackStatus 7 "TrackStatus_NotAvailable" 6 "TrackStatus_Error" 5 "TrackStatus_Spare3" 4 "TrackStatus_Spare2" 3 "TrackStatus_Spare1" 2 "TrackStatus_Invalid" 1 "TrackStatus_Predicted" 0 "TrackStatus_Tracked" ;
VAL_ 842 LFSideSensorObj10_ObjClass 15 "ObjClassSideS_NotAvailable" 14 "ObjClassSideS_Error" 13 "ObjClassSideS_Spare4" 12 "ObjClassSideS_Spare3" 11 "ObjClassSideS_Motorcycle" 10 "ObjClassSideS_Bicycle" 9 "ObjClassSideS_UnidentifiedMovableObject" 8 "ObjClassSideS_UnidentifiedVRU" 7 "ObjClassSideS_UnidentifiedVehicle" 6 "ObjClassSideS_StaticObject" 5 "ObjClassSideS_Pedestrian" 4 "ObjClassSideS_2Wheeler" 3 "ObjClassSideS_HeavyVehicle" 2 "ObjClassSideS_Car" 1 "ObjClassSideS_Obstacle" 0 "ObjClassSideS_Undetermined" ;
VAL_ 841 LFSideSensorObj09_Prioritisation 3 "Prioritisation_NotAvailable" 2 "Prioritisation_StaticPrioritisation" 1 "Prioritisation_VolvoPrioritisation" 0 "Prioritisation_BoschPrioritisation" ;
VAL_ 841 LFSideSensorObj09_TrackStatus 7 "TrackStatus_NotAvailable" 6 "TrackStatus_Error" 5 "TrackStatus_Spare3" 4 "TrackStatus_Spare2" 3 "TrackStatus_Spare1" 2 "TrackStatus_Invalid" 1 "TrackStatus_Predicted" 0 "TrackStatus_Tracked" ;
VAL_ 841 LFSideSensorObj09_ObjDynClass 3 "ObjDynClass_Error" 2 "ObjDynClass_Movable" 1 "ObjDynClass_Stationary" 0 "ObjDynClass_Reserved" ;
VAL_ 841 LFSideSensorObj09_ObjClass 15 "ObjClassSideS_NotAvailable" 14 "ObjClassSideS_Error" 13 "ObjClassSideS_Spare4" 12 "ObjClassSideS_Spare3" 11 "ObjClassSideS_Motorcycle" 10 "ObjClassSideS_Bicycle" 9 "ObjClassSideS_UnidentifiedMovableObject" 8 "ObjClassSideS_UnidentifiedVRU" 7 "ObjClassSideS_UnidentifiedVehicle" 6 "ObjClassSideS_StaticObject" 5 "ObjClassSideS_Pedestrian" 4 "ObjClassSideS_2Wheeler" 3 "ObjClassSideS_HeavyVehicle" 2 "ObjClassSideS_Car" 1 "ObjClassSideS_Obstacle" 0 "ObjClassSideS_Undetermined" ;
VAL_ 840 LFSideSensorObj08_Prioritisation 3 "Prioritisation_NotAvailable" 2 "Prioritisation_StaticPrioritisation" 1 "Prioritisation_VolvoPrioritisation" 0 "Prioritisation_BoschPrioritisation" ;
VAL_ 840 LFSideSensorObj08_TrackStatus 7 "TrackStatus_NotAvailable" 6 "TrackStatus_Error" 5 "TrackStatus_Spare3" 4 "TrackStatus_Spare2" 3 "TrackStatus_Spare1" 2 "TrackStatus_Invalid" 1 "TrackStatus_Predicted" 0 "TrackStatus_Tracked" ;
VAL_ 840 LFSideSensorObj08_ObjClass 15 "ObjClassSideS_NotAvailable" 14 "ObjClassSideS_Error" 13 "ObjClassSideS_Spare4" 12 "ObjClassSideS_Spare3" 11 "ObjClassSideS_Motorcycle" 10 "ObjClassSideS_Bicycle" 9 "ObjClassSideS_UnidentifiedMovableObject" 8 "ObjClassSideS_UnidentifiedVRU" 7 "ObjClassSideS_UnidentifiedVehicle" 6 "ObjClassSideS_StaticObject" 5 "ObjClassSideS_Pedestrian" 4 "ObjClassSideS_2Wheeler" 3 "ObjClassSideS_HeavyVehicle" 2 "ObjClassSideS_Car" 1 "ObjClassSideS_Obstacle" 0 "ObjClassSideS_Undetermined" ;
VAL_ 840 LFSideSensorObj08_ObjDynClass 3 "ObjDynClass_Error" 2 "ObjDynClass_Movable" 1 "ObjDynClass_Stationary" 0 "ObjDynClass_Reserved" ;
VAL_ 839 LFSideSensorObj07_ObjDynClass 3 "ObjDynClass_Error" 2 "ObjDynClass_Movable" 1 "ObjDynClass_Stationary" 0 "ObjDynClass_Reserved" ;
VAL_ 839 LFSideSensorObj07_TrackStatus 7 "TrackStatus_NotAvailable" 6 "TrackStatus_Error" 5 "TrackStatus_Spare3" 4 "TrackStatus_Spare2" 3 "TrackStatus_Spare1" 2 "TrackStatus_Invalid" 1 "TrackStatus_Predicted" 0 "TrackStatus_Tracked" ;
VAL_ 839 LFSideSensorObj07_Prioritisation 3 "Prioritisation_NotAvailable" 2 "Prioritisation_StaticPrioritisation" 1 "Prioritisation_VolvoPrioritisation" 0 "Prioritisation_BoschPrioritisation" ;
VAL_ 839 LFSideSensorObj07_ObjClass 15 "ObjClassSideS_NotAvailable" 14 "ObjClassSideS_Error" 13 "ObjClassSideS_Spare4" 12 "ObjClassSideS_Spare3" 11 "ObjClassSideS_Motorcycle" 10 "ObjClassSideS_Bicycle" 9 "ObjClassSideS_UnidentifiedMovableObject" 8 "ObjClassSideS_UnidentifiedVRU" 7 "ObjClassSideS_UnidentifiedVehicle" 6 "ObjClassSideS_StaticObject" 5 "ObjClassSideS_Pedestrian" 4 "ObjClassSideS_2Wheeler" 3 "ObjClassSideS_HeavyVehicle" 2 "ObjClassSideS_Car" 1 "ObjClassSideS_Obstacle" 0 "ObjClassSideS_Undetermined" ;
VAL_ 838 LFSideSensorObj06_Prioritisation 3 "Prioritisation_NotAvailable" 2 "Prioritisation_StaticPrioritisation" 1 "Prioritisation_VolvoPrioritisation" 0 "Prioritisation_BoschPrioritisation" ;
VAL_ 838 LFSideSensorObj06_ObjDynClass 3 "ObjDynClass_Error" 2 "ObjDynClass_Movable" 1 "ObjDynClass_Stationary" 0 "ObjDynClass_Reserved" ;
VAL_ 838 LFSideSensorObj06_ObjClass 15 "ObjClassSideS_NotAvailable" 14 "ObjClassSideS_Error" 13 "ObjClassSideS_Spare4" 12 "ObjClassSideS_Spare3" 11 "ObjClassSideS_Motorcycle" 10 "ObjClassSideS_Bicycle" 9 "ObjClassSideS_UnidentifiedMovableObject" 8 "ObjClassSideS_UnidentifiedVRU" 7 "ObjClassSideS_UnidentifiedVehicle" 6 "ObjClassSideS_StaticObject" 5 "ObjClassSideS_Pedestrian" 4 "ObjClassSideS_2Wheeler" 3 "ObjClassSideS_HeavyVehicle" 2 "ObjClassSideS_Car" 1 "ObjClassSideS_Obstacle" 0 "ObjClassSideS_Undetermined" ;
VAL_ 838 LFSideSensorObj06_TrackStatus 7 "TrackStatus_NotAvailable" 6 "TrackStatus_Error" 5 "TrackStatus_Spare3" 4 "TrackStatus_Spare2" 3 "TrackStatus_Spare1" 2 "TrackStatus_Invalid" 1 "TrackStatus_Predicted" 0 "TrackStatus_Tracked" ;
VAL_ 837 LFSideSensorObj05_TrackStatus 7 "TrackStatus_NotAvailable" 6 "TrackStatus_Error" 5 "TrackStatus_Spare3" 4 "TrackStatus_Spare2" 3 "TrackStatus_Spare1" 2 "TrackStatus_Invalid" 1 "TrackStatus_Predicted" 0 "TrackStatus_Tracked" ;
VAL_ 837 LFSideSensorObj05_ObjClass 15 "ObjClassSideS_NotAvailable" 14 "ObjClassSideS_Error" 13 "ObjClassSideS_Spare4" 12 "ObjClassSideS_Spare3" 11 "ObjClassSideS_Motorcycle" 10 "ObjClassSideS_Bicycle" 9 "ObjClassSideS_UnidentifiedMovableObject" 8 "ObjClassSideS_UnidentifiedVRU" 7 "ObjClassSideS_UnidentifiedVehicle" 6 "ObjClassSideS_StaticObject" 5 "ObjClassSideS_Pedestrian" 4 "ObjClassSideS_2Wheeler" 3 "ObjClassSideS_HeavyVehicle" 2 "ObjClassSideS_Car" 1 "ObjClassSideS_Obstacle" 0 "ObjClassSideS_Undetermined" ;
VAL_ 837 LFSideSensorObj05_Prioritisation 3 "Prioritisation_NotAvailable" 2 "Prioritisation_StaticPrioritisation" 1 "Prioritisation_VolvoPrioritisation" 0 "Prioritisation_BoschPrioritisation" ;
VAL_ 837 LFSideSensorObj05_ObjDynClass 3 "ObjDynClass_Error" 2 "ObjDynClass_Movable" 1 "ObjDynClass_Stationary" 0 "ObjDynClass_Reserved" ;
VAL_ 836 LFSideSensorObj04_TrackStatus 7 "TrackStatus_NotAvailable" 6 "TrackStatus_Error" 5 "TrackStatus_Spare3" 4 "TrackStatus_Spare2" 3 "TrackStatus_Spare1" 2 "TrackStatus_Invalid" 1 "TrackStatus_Predicted" 0 "TrackStatus_Tracked" ;
VAL_ 836 LFSideSensorObj04_ObjDynClass 3 "ObjDynClass_Error" 2 "ObjDynClass_Movable" 1 "ObjDynClass_Stationary" 0 "ObjDynClass_Reserved" ;
VAL_ 836 LFSideSensorObj04_Prioritisation 3 "Prioritisation_NotAvailable" 2 "Prioritisation_StaticPrioritisation" 1 "Prioritisation_VolvoPrioritisation" 0 "Prioritisation_BoschPrioritisation" ;
VAL_ 836 LFSideSensorObj04_ObjClass 15 "ObjClassSideS_NotAvailable" 14 "ObjClassSideS_Error" 13 "ObjClassSideS_Spare4" 12 "ObjClassSideS_Spare3" 11 "ObjClassSideS_Motorcycle" 10 "ObjClassSideS_Bicycle" 9 "ObjClassSideS_UnidentifiedMovableObject" 8 "ObjClassSideS_UnidentifiedVRU" 7 "ObjClassSideS_UnidentifiedVehicle" 6 "ObjClassSideS_StaticObject" 5 "ObjClassSideS_Pedestrian" 4 "ObjClassSideS_2Wheeler" 3 "ObjClassSideS_HeavyVehicle" 2 "ObjClassSideS_Car" 1 "ObjClassSideS_Obstacle" 0 "ObjClassSideS_Undetermined" ;
VAL_ 835 LFSideSensorObj03_ObjDynClass 3 "ObjDynClass_Error" 2 "ObjDynClass_Movable" 1 "ObjDynClass_Stationary" 0 "ObjDynClass_Reserved" ;
VAL_ 835 LFSideSensorObj03_TrackStatus 7 "TrackStatus_NotAvailable" 6 "TrackStatus_Error" 5 "TrackStatus_Spare3" 4 "TrackStatus_Spare2" 3 "TrackStatus_Spare1" 2 "TrackStatus_Invalid" 1 "TrackStatus_Predicted" 0 "TrackStatus_Tracked" ;
VAL_ 835 LFSideSensorObj03_ObjClass 15 "ObjClassSideS_NotAvailable" 14 "ObjClassSideS_Error" 13 "ObjClassSideS_Spare4" 12 "ObjClassSideS_Spare3" 11 "ObjClassSideS_Motorcycle" 10 "ObjClassSideS_Bicycle" 9 "ObjClassSideS_UnidentifiedMovableObject" 8 "ObjClassSideS_UnidentifiedVRU" 7 "ObjClassSideS_UnidentifiedVehicle" 6 "ObjClassSideS_StaticObject" 5 "ObjClassSideS_Pedestrian" 4 "ObjClassSideS_2Wheeler" 3 "ObjClassSideS_HeavyVehicle" 2 "ObjClassSideS_Car" 1 "ObjClassSideS_Obstacle" 0 "ObjClassSideS_Undetermined" ;
VAL_ 835 LFSideSensorObj03_Prioritisation 3 "Prioritisation_NotAvailable" 2 "Prioritisation_StaticPrioritisation" 1 "Prioritisation_VolvoPrioritisation" 0 "Prioritisation_BoschPrioritisation" ;
VAL_ 834 LFSideSensorObj02_Prioritisation 3 "Prioritisation_NotAvailable" 2 "Prioritisation_StaticPrioritisation" 1 "Prioritisation_VolvoPrioritisation" 0 "Prioritisation_BoschPrioritisation" ;
VAL_ 834 LFSideSensorObj02_ObjDynClass 3 "ObjDynClass_Error" 2 "ObjDynClass_Movable" 1 "ObjDynClass_Stationary" 0 "ObjDynClass_Reserved" ;
VAL_ 834 LFSideSensorObj02_ObjClass 15 "ObjClassSideS_NotAvailable" 14 "ObjClassSideS_Error" 13 "ObjClassSideS_Spare4" 12 "ObjClassSideS_Spare3" 11 "ObjClassSideS_Motorcycle" 10 "ObjClassSideS_Bicycle" 9 "ObjClassSideS_UnidentifiedMovableObject" 8 "ObjClassSideS_UnidentifiedVRU" 7 "ObjClassSideS_UnidentifiedVehicle" 6 "ObjClassSideS_StaticObject" 5 "ObjClassSideS_Pedestrian" 4 "ObjClassSideS_2Wheeler" 3 "ObjClassSideS_HeavyVehicle" 2 "ObjClassSideS_Car" 1 "ObjClassSideS_Obstacle" 0 "ObjClassSideS_Undetermined" ;
VAL_ 834 LFSideSensorObj02_TrackStatus 7 "TrackStatus_NotAvailable" 6 "TrackStatus_Error" 5 "TrackStatus_Spare3" 4 "TrackStatus_Spare2" 3 "TrackStatus_Spare1" 2 "TrackStatus_Invalid" 1 "TrackStatus_Predicted" 0 "TrackStatus_Tracked" ;
VAL_ 833 LFSideSensorObj01_ObjDynClass 3 "ObjDynClass_Error" 2 "ObjDynClass_Movable" 1 "ObjDynClass_Stationary" 0 "ObjDynClass_Reserved" ;
VAL_ 833 LFSideSensorObj01_ObjClass 15 "ObjClassSideS_NotAvailable" 14 "ObjClassSideS_Error" 13 "ObjClassSideS_Spare4" 12 "ObjClassSideS_Spare3" 11 "ObjClassSideS_Motorcycle" 10 "ObjClassSideS_Bicycle" 9 "ObjClassSideS_UnidentifiedMovableObject" 8 "ObjClassSideS_UnidentifiedVRU" 7 "ObjClassSideS_UnidentifiedVehicle" 6 "ObjClassSideS_StaticObject" 5 "ObjClassSideS_Pedestrian" 4 "ObjClassSideS_2Wheeler" 3 "ObjClassSideS_HeavyVehicle" 2 "ObjClassSideS_Car" 1 "ObjClassSideS_Obstacle" 0 "ObjClassSideS_Undetermined" ;
VAL_ 833 LFSideSensorObj01_Prioritisation 3 "Prioritisation_NotAvailable" 2 "Prioritisation_StaticPrioritisation" 1 "Prioritisation_VolvoPrioritisation" 0 "Prioritisation_BoschPrioritisation" ;
VAL_ 833 LFSideSensorObj01_TrackStatus 7 "TrackStatus_NotAvailable" 6 "TrackStatus_Error" 5 "TrackStatus_Spare3" 4 "TrackStatus_Spare2" 3 "TrackStatus_Spare1" 2 "TrackStatus_Invalid" 1 "TrackStatus_Predicted" 0 "TrackStatus_Tracked" ;
VAL_ 832 LFSideSensorObj00_Prioritisation 3 "Prioritisation_NotAvailable" 2 "Prioritisation_StaticPrioritisation" 1 "Prioritisation_VolvoPrioritisation" 0 "Prioritisation_BoschPrioritisation" ;
VAL_ 832 LFSideSensorObj00_ObjDynClass 3 "ObjDynClass_Error" 2 "ObjDynClass_Movable" 1 "ObjDynClass_Stationary" 0 "ObjDynClass_Reserved" ;
VAL_ 832 LFSideSensorObj00_ObjClass 15 "ObjClassSideS_NotAvailable" 14 "ObjClassSideS_Error" 13 "ObjClassSideS_Spare4" 12 "ObjClassSideS_Spare3" 11 "ObjClassSideS_Motorcycle" 10 "ObjClassSideS_Bicycle" 9 "ObjClassSideS_UnidentifiedMovableObject" 8 "ObjClassSideS_UnidentifiedVRU" 7 "ObjClassSideS_UnidentifiedVehicle" 6 "ObjClassSideS_StaticObject" 5 "ObjClassSideS_Pedestrian" 4 "ObjClassSideS_2Wheeler" 3 "ObjClassSideS_HeavyVehicle" 2 "ObjClassSideS_Car" 1 "ObjClassSideS_Obstacle" 0 "ObjClassSideS_Undetermined" ;
VAL_ 832 LFSideSensorObj00_TrackStatus 7 "TrackStatus_NotAvailable" 6 "TrackStatus_Error" 5 "TrackStatus_Spare3" 4 "TrackStatus_Spare2" 3 "TrackStatus_Spare1" 2 "TrackStatus_Invalid" 1 "TrackStatus_Predicted" 0 "TrackStatus_Tracked" ;
VAL_ 847 LFSRRaisedEdge_Type 7 "RaisedEdgeType_NotAvailable" 6 "RaisedEdgeType_Error" 5 "RaisedEdgeType_Spare2" 4 "RaisedEdgeType_Spare1" 3 "RaisedEdgeType_Barrier" 2 "RaisedEdgeType_NonElevatedBoundary" 1 "RaisedEdgeType_ElevatedBoundary" 0 "RaisedEdgeType_Unknown" ;
VAL_ 847 LFSRRaisedEdge_TrackStatus 7 "TrackStatus_NotAvailable" 6 "TrackStatus_Error" 5 "TrackStatus_Spare3" 4 "TrackStatus_Spare2" 3 "TrackStatus_Spare1" 2 "TrackStatus_Invalid" 1 "TrackStatus_Predicted" 0 "TrackStatus_Tracked" ;
VAL_ 275 EgoMotionXYplane_LongMotDirConf 15 "LongMotionDirConf_NotAvailable" 14 "LongMotionDirConf_Error" 13 "LongMotionDirConf_Spare5" 12 "LongMotionDirConf_Spare4" 11 "LongMotionDirConf_Spare3" 10 "LongMotionDirConf_Spare2" 9 "LongMotionDirConf_Spare1" 8 "LongMotionDirConf_MovingVeryHighConfidence" 7 "LongMotionDirConf_MovingHighConfidence" 6 "LongMotionDirConf_MovingMediumConfidence" 5 "LongMotionDirConf_MovingLowConfidence" 4 "LongMotionDirConf_StationaryLowConfidence" 3 "LongMotionDirConf_StationaryMediumConfidence" 2 "LongMotionDirConf_StationaryHighConfidence" 1 "LongMotionDirConf_StationaryVeryHighConfidence" 0 "LongMotionDirConf_StationaryVeryVeryHighConfidence" ;
VAL_ 275 EgoMotionXYplane_LongMotionDir 7 "LongMotionDirection_NotAvailable" 6 "LongMotionDirection_Error" 5 "LongMotionDirection_Spare3" 4 "LongMotionDirection_Spare2" 3 "LongMotionDirection_Undetermined" 2 "LongMotionDirection_Backward" 1 "LongMotionDirection_Forward" 0 "LongMotionDirection_Stationary" ;
SIG_GROUP_ 842 LFSideSensorObj10_sg 1 : LFSideSensorObj10_LatExtLeft LFSideSensorObj10_LatVel LFSideSensorObj10_LatPosVar LFSideSensorObj10_LongAccVar LFSideSensorObj10_LongPos LFSideSensorObj10_ObstacleConf LFSideSensorObj10_LatExtRtVar LFSideSensorObj10_Prioritisation LFSideSensorObj10_HeadingVar LFSideSensorObj10_ExistConf LFSideSensorObj10_Counter LFSideSensorObj10_ObjDynClass LFSideSensorObj10_LatAcc LFSideSensorObj10_TrackStatus LFSideSensorObj10_CoastIndex LFSideSensorObj10_LongVelVar LFSideSensorObj10_LongExtFrVar LFSideSensorObj10_LongExtFront LFSideSensorObj10_LatExtRight LFSideSensorObj10_MOISPrio LFSideSensorObj10_LongAcc LFSideSensorObj10_LongVel LFSideSensorObj10_LongExtBack LFSideSensorObj10_ObjClassConf LFSideSensorObj10_LatVelVar LFSideSensorObj10_TimeStamp LFSideSensorObj10_ObjID LFSideSensorObj10_ObjClass LFSideSensorObj10_LifeTime LFSideSensorObj10_LongPosVar LFSideSensorObj10_LongExtBkVar LFSideSensorObj10_LatExtLeftVar LFSideSensorObj10_Heading LFSideSensorObj10_CRC LFSideSensorObj10_LatAccVar LFSideSensorObj10_Height LFSideSensorObj10_LatPos;
SIG_GROUP_ 841 LFSideSensorObj09_sg 1 : LFSideSensorObj09_Prioritisation LFSideSensorObj09_TimeStamp LFSideSensorObj09_CoastIndex LFSideSensorObj09_MOISPrio LFSideSensorObj09_ExistConf LFSideSensorObj09_Counter LFSideSensorObj09_TrackStatus LFSideSensorObj09_LongExtFront LFSideSensorObj09_LatPos LFSideSensorObj09_LongExtFrVar LFSideSensorObj09_CRC LFSideSensorObj09_LongVelVar LFSideSensorObj09_LongPosVar LFSideSensorObj09_LongExtBkVar LFSideSensorObj09_LongPos LFSideSensorObj09_LatVelVar LFSideSensorObj09_LatExtRtVar LFSideSensorObj09_ObjClassConf LFSideSensorObj09_Height LFSideSensorObj09_LatVel LFSideSensorObj09_ObjDynClass LFSideSensorObj09_LongExtBack LFSideSensorObj09_LatExtLeftVar LFSideSensorObj09_HeadingVar LFSideSensorObj09_LatExtLeft LFSideSensorObj09_LongAccVar LFSideSensorObj09_LifeTime LFSideSensorObj09_LongVel LFSideSensorObj09_Heading LFSideSensorObj09_LatPosVar LFSideSensorObj09_ObjID LFSideSensorObj09_LatAccVar LFSideSensorObj09_LatExtRight LFSideSensorObj09_LongAcc LFSideSensorObj09_LatAcc LFSideSensorObj09_ObjClass LFSideSensorObj09_ObstacleConf;
SIG_GROUP_ 840 LFSideSensorObj08_sg 1 : LFSideSensorObj08_CoastIndex LFSideSensorObj08_LatExtLeftVar LFSideSensorObj08_LongExtFront LFSideSensorObj08_LatExtLeft LFSideSensorObj08_LatAcc LFSideSensorObj08_LongExtBkVar LFSideSensorObj08_LifeTime LFSideSensorObj08_LatPos LFSideSensorObj08_ObjID LFSideSensorObj08_Prioritisation LFSideSensorObj08_ExistConf LFSideSensorObj08_LongExtFrVar LFSideSensorObj08_MOISPrio LFSideSensorObj08_LongPosVar LFSideSensorObj08_LongVel LFSideSensorObj08_TrackStatus LFSideSensorObj08_Counter LFSideSensorObj08_CRC LFSideSensorObj08_LatExtRight LFSideSensorObj08_LongVelVar LFSideSensorObj08_LongAcc LFSideSensorObj08_Heading LFSideSensorObj08_LongExtBack LFSideSensorObj08_LatExtRtVar LFSideSensorObj08_LatVelVar LFSideSensorObj08_HeadingVar LFSideSensorObj08_ObjClass LFSideSensorObj08_ObjClassConf LFSideSensorObj08_LatPosVar LFSideSensorObj08_LongPos LFSideSensorObj08_LatAccVar LFSideSensorObj08_Height LFSideSensorObj08_TimeStamp LFSideSensorObj08_LongAccVar LFSideSensorObj08_LatVel LFSideSensorObj08_ObjDynClass LFSideSensorObj08_ObstacleConf;
SIG_GROUP_ 839 LFSideSensorObj07_sg 1 : LFSideSensorObj07_LatAcc LFSideSensorObj07_LongPosVar LFSideSensorObj07_ObjClassConf LFSideSensorObj07_LatPosVar LFSideSensorObj07_ExistConf LFSideSensorObj07_LifeTime LFSideSensorObj07_ObstacleConf LFSideSensorObj07_MOISPrio LFSideSensorObj07_ObjDynClass LFSideSensorObj07_Height LFSideSensorObj07_HeadingVar LFSideSensorObj07_Heading LFSideSensorObj07_LatExtLeftVar LFSideSensorObj07_LatVel LFSideSensorObj07_Counter LFSideSensorObj07_TrackStatus LFSideSensorObj07_LongExtBack LFSideSensorObj07_LatVelVar LFSideSensorObj07_TimeStamp LFSideSensorObj07_LongAccVar LFSideSensorObj07_LongVelVar LFSideSensorObj07_LatExtLeft LFSideSensorObj07_LongPos LFSideSensorObj07_LongVel LFSideSensorObj07_LongExtFrVar LFSideSensorObj07_LatExtRtVar LFSideSensorObj07_LatAccVar LFSideSensorObj07_Prioritisation LFSideSensorObj07_ObjClass LFSideSensorObj07_CoastIndex LFSideSensorObj07_LatPos LFSideSensorObj07_LongExtBkVar LFSideSensorObj07_ObjID LFSideSensorObj07_LongExtFront LFSideSensorObj07_CRC LFSideSensorObj07_LatExtRight LFSideSensorObj07_LongAcc;
SIG_GROUP_ 838 LFSideSensorObj06_sg 1 : LFSideSensorObj06_MOISPrio LFSideSensorObj06_ObstacleConf LFSideSensorObj06_LongVel LFSideSensorObj06_LongExtFront LFSideSensorObj06_Counter LFSideSensorObj06_LongVelVar LFSideSensorObj06_LongPos LFSideSensorObj06_LongExtFrVar LFSideSensorObj06_LatExtLeft LFSideSensorObj06_Prioritisation LFSideSensorObj06_CoastIndex LFSideSensorObj06_HeadingVar LFSideSensorObj06_LatAcc LFSideSensorObj06_LongExtBkVar LFSideSensorObj06_LongAccVar LFSideSensorObj06_LongExtBack LFSideSensorObj06_Heading LFSideSensorObj06_ExistConf LFSideSensorObj06_LatVelVar LFSideSensorObj06_LifeTime LFSideSensorObj06_LatVel LFSideSensorObj06_TimeStamp LFSideSensorObj06_ObjDynClass LFSideSensorObj06_ObjClass LFSideSensorObj06_TrackStatus LFSideSensorObj06_LatExtLeftVar LFSideSensorObj06_ObjClassConf LFSideSensorObj06_LongPosVar LFSideSensorObj06_LatExtRtVar LFSideSensorObj06_CRC LFSideSensorObj06_LatPosVar LFSideSensorObj06_LatPos LFSideSensorObj06_ObjID LFSideSensorObj06_LongAcc LFSideSensorObj06_LatExtRight LFSideSensorObj06_LatAccVar LFSideSensorObj06_Height;
SIG_GROUP_ 837 LFSideSensorObj05_sg 1 : LFSideSensorObj05_Height LFSideSensorObj05_LatPosVar LFSideSensorObj05_MOISPrio LFSideSensorObj05_LatExtLeftVar LFSideSensorObj05_LongPosVar LFSideSensorObj05_LatAccVar LFSideSensorObj05_LongExtBkVar LFSideSensorObj05_LongAcc LFSideSensorObj05_LatExtRight LFSideSensorObj05_LatExtLeft LFSideSensorObj05_LongExtFront LFSideSensorObj05_ObjClassConf LFSideSensorObj05_ObjID LFSideSensorObj05_LatPos LFSideSensorObj05_LongExtBack LFSideSensorObj05_Heading LFSideSensorObj05_CRC LFSideSensorObj05_LongAccVar LFSideSensorObj05_LatExtRtVar LFSideSensorObj05_ExistConf LFSideSensorObj05_LatAcc LFSideSensorObj05_CoastIndex LFSideSensorObj05_LongPos LFSideSensorObj05_LongVel LFSideSensorObj05_LongVelVar LFSideSensorObj05_TrackStatus LFSideSensorObj05_LifeTime LFSideSensorObj05_ObjClass LFSideSensorObj05_HeadingVar LFSideSensorObj05_Prioritisation LFSideSensorObj05_Counter LFSideSensorObj05_LatVel LFSideSensorObj05_LongExtFrVar LFSideSensorObj05_ObjDynClass LFSideSensorObj05_TimeStamp LFSideSensorObj05_ObstacleConf LFSideSensorObj05_LatVelVar;
SIG_GROUP_ 836 LFSideSensorObj04_sg 1 : LFSideSensorObj04_TrackStatus LFSideSensorObj04_LongAcc LFSideSensorObj04_LatExtRight LFSideSensorObj04_Heading LFSideSensorObj04_ObjDynClass LFSideSensorObj04_CRC LFSideSensorObj04_ExistConf LFSideSensorObj04_LongAccVar LFSideSensorObj04_TimeStamp LFSideSensorObj04_Counter LFSideSensorObj04_LatPos LFSideSensorObj04_CoastIndex LFSideSensorObj04_LongPos LFSideSensorObj04_LongExtBkVar LFSideSensorObj04_LatVelVar LFSideSensorObj04_LatAccVar LFSideSensorObj04_LifeTime LFSideSensorObj04_LongExtFront LFSideSensorObj04_Prioritisation LFSideSensorObj04_ObjID LFSideSensorObj04_LongPosVar LFSideSensorObj04_LongVel LFSideSensorObj04_ObjClassConf LFSideSensorObj04_LatExtLeft LFSideSensorObj04_LatVel LFSideSensorObj04_LongExtBack LFSideSensorObj04_LatAcc LFSideSensorObj04_MOISPrio LFSideSensorObj04_ObstacleConf LFSideSensorObj04_LatPosVar LFSideSensorObj04_HeadingVar LFSideSensorObj04_LongExtFrVar LFSideSensorObj04_LatExtLeftVar LFSideSensorObj04_Height LFSideSensorObj04_LongVelVar LFSideSensorObj04_ObjClass LFSideSensorObj04_LatExtRtVar;
SIG_GROUP_ 835 LFSideSensorObj03_sg 1 : LFSideSensorObj03_ObjDynClass LFSideSensorObj03_TrackStatus LFSideSensorObj03_Counter LFSideSensorObj03_LatVel LFSideSensorObj03_LatVelVar LFSideSensorObj03_ExistConf LFSideSensorObj03_ObjClass LFSideSensorObj03_ObstacleConf LFSideSensorObj03_LongAcc LFSideSensorObj03_LatAccVar LFSideSensorObj03_CRC LFSideSensorObj03_MOISPrio LFSideSensorObj03_ObjClassConf LFSideSensorObj03_LongPos LFSideSensorObj03_LatPosVar LFSideSensorObj03_ObjID LFSideSensorObj03_LongVel LFSideSensorObj03_Height LFSideSensorObj03_LatExtLeftVar LFSideSensorObj03_Prioritisation LFSideSensorObj03_HeadingVar LFSideSensorObj03_LifeTime LFSideSensorObj03_LatExtLeft LFSideSensorObj03_Heading LFSideSensorObj03_LongPosVar LFSideSensorObj03_LongExtFrVar LFSideSensorObj03_LongExtBack LFSideSensorObj03_LatExtRtVar LFSideSensorObj03_TimeStamp LFSideSensorObj03_LongExtBkVar LFSideSensorObj03_LatAcc LFSideSensorObj03_LatPos LFSideSensorObj03_LongVelVar LFSideSensorObj03_CoastIndex LFSideSensorObj03_LatExtRight LFSideSensorObj03_LongExtFront LFSideSensorObj03_LongAccVar;
SIG_GROUP_ 834 LFSideSensorObj02_sg 1 : LFSideSensorObj02_LatVelVar LFSideSensorObj02_LatExtLeftVar LFSideSensorObj02_ObstacleConf LFSideSensorObj02_LatExtRtVar LFSideSensorObj02_Height LFSideSensorObj02_LongVelVar LFSideSensorObj02_Prioritisation LFSideSensorObj02_ExistConf LFSideSensorObj02_CRC LFSideSensorObj02_LongVel LFSideSensorObj02_LongAcc LFSideSensorObj02_LifeTime LFSideSensorObj02_LatAcc LFSideSensorObj02_ObjClassConf LFSideSensorObj02_LatPos LFSideSensorObj02_ObjID LFSideSensorObj02_LongPos LFSideSensorObj02_LatVel LFSideSensorObj02_Heading LFSideSensorObj02_LongExtFront LFSideSensorObj02_MOISPrio LFSideSensorObj02_LatAccVar LFSideSensorObj02_TimeStamp LFSideSensorObj02_LongExtFrVar LFSideSensorObj02_LatExtLeft LFSideSensorObj02_LongExtBack LFSideSensorObj02_ObjDynClass LFSideSensorObj02_HeadingVar LFSideSensorObj02_LongPosVar LFSideSensorObj02_LatPosVar LFSideSensorObj02_LatExtRight LFSideSensorObj02_LongAccVar LFSideSensorObj02_CoastIndex LFSideSensorObj02_Counter LFSideSensorObj02_ObjClass LFSideSensorObj02_LongExtBkVar LFSideSensorObj02_TrackStatus;
SIG_GROUP_ 833 LFSideSensorObj01_sg 1 : LFSideSensorObj01_LatAcc LFSideSensorObj01_ExistConf LFSideSensorObj01_ObjDynClass LFSideSensorObj01_LongAcc LFSideSensorObj01_LatExtRtVar LFSideSensorObj01_CRC LFSideSensorObj01_LatVel LFSideSensorObj01_LongExtBack LFSideSensorObj01_LongAccVar LFSideSensorObj01_Counter LFSideSensorObj01_Heading LFSideSensorObj01_ObjID LFSideSensorObj01_LatPosVar LFSideSensorObj01_LongVel LFSideSensorObj01_ObjClass LFSideSensorObj01_MOISPrio LFSideSensorObj01_LongPos LFSideSensorObj01_LatExtRight LFSideSensorObj01_LatExtLeftVar LFSideSensorObj01_LongExtFrVar LFSideSensorObj01_LatExtLeft LFSideSensorObj01_Prioritisation LFSideSensorObj01_Height LFSideSensorObj01_HeadingVar LFSideSensorObj01_CoastIndex LFSideSensorObj01_ObjClassConf LFSideSensorObj01_LongExtBkVar LFSideSensorObj01_LifeTime LFSideSensorObj01_LongPosVar LFSideSensorObj01_LatPos LFSideSensorObj01_LongVelVar LFSideSensorObj01_LongExtFront LFSideSensorObj01_ObstacleConf LFSideSensorObj01_TrackStatus LFSideSensorObj01_TimeStamp LFSideSensorObj01_LatAccVar LFSideSensorObj01_LatVelVar;
SIG_GROUP_ 832 LFSideSensorObj00_sg 1 : LFSideSensorObj00_LongAccVar LFSideSensorObj00_LongVelVar LFSideSensorObj00_Prioritisation LFSideSensorObj00_LatAcc LFSideSensorObj00_MOISPrio LFSideSensorObj00_Heading LFSideSensorObj00_LongAcc LFSideSensorObj00_LongPos LFSideSensorObj00_ObjID LFSideSensorObj00_LongPosVar LFSideSensorObj00_HeadingVar LFSideSensorObj00_LongExtFrVar LFSideSensorObj00_LatVelVar LFSideSensorObj00_LatPosVar LFSideSensorObj00_ObjDynClass LFSideSensorObj00_CRC LFSideSensorObj00_ExistConf LFSideSensorObj00_Height LFSideSensorObj00_LongVel LFSideSensorObj00_LongExtBkVar LFSideSensorObj00_LatPos LFSideSensorObj00_Counter LFSideSensorObj00_ObjClass LFSideSensorObj00_LatAccVar LFSideSensorObj00_TrackStatus LFSideSensorObj00_LatExtRtVar LFSideSensorObj00_ObstacleConf LFSideSensorObj00_LongExtBack LFSideSensorObj00_ObjClassConf LFSideSensorObj00_LatExtLeftVar LFSideSensorObj00_LifeTime LFSideSensorObj00_LatExtLeft LFSideSensorObj00_TimeStamp LFSideSensorObj00_LatVel LFSideSensorObj00_LongExtFront LFSideSensorObj00_LatExtRight LFSideSensorObj00_CoastIndex;
SIG_GROUP_ 1556 LFSRSwVersion_sg 1 : LFSRSwVersion_Substring6 LFSRSwVersion_Substring2 LFSRSwVersion_Substring1 LFSRSwVersion_Substring0 LFSRSwVersion_Substring3 LFSRSwVersion_Substring5 LFSRSwVersion_Substring4 LFSRSwVersion_Substring7;
SIG_GROUP_ 847 LFSRRaisedEdge_sg 1 : LFSRRaisedEdge_LifeTime LFSRRaisedEdge_HeadingAngle LFSRRaisedEdge_Curvature LFSRRaisedEdge_CoastIndex LFSRRaisedEdge_Confidence LFSRRaisedEdge_DxEnd LFSRRaisedEdge_Type LFSRRaisedEdge_CurvatureRate LFSRRaisedEdge_Counter LFSRRaisedEdge_LatDist LFSRRaisedEdge_DxStart LFSRRaisedEdge_TimeStamp LFSRRaisedEdge_CRC LFSRRaisedEdge_TrackStatus LFSRRaisedEdge_LatDistVar;
SIG_GROUP_ 846 LFSREgoAssumpt_sg 1 : LFSREgoAssumpt_EgoLongVel LFSREgoAssumpt_EgoRoadEnd LFSREgoAssumpt_EgoLongAcc LFSREgoAssumpt_EgoRoadCurvature LFSREgoAssumpt_EgoRoadCurvRate LFSREgoAssumpt_EgoYawRate LFSREgoAssumpt_VelCorrFactor LFSREgoAssumpt_EgoRoadHeading LFSREgoAssumpt_TimeStamp;
SIG_GROUP_ 1523 DiagFaultStat_SRRR_sg 1 : DiagFaultStat_SRRR_DtcIdA DiagFaultStat_SRRR_FailTB DiagFaultStat_SRRR_DtcIdB DiagFaultStat_SRRR_FailTA DiagFaultStat_SRRR_EcuAdr;
SIG_GROUP_ 1522 DiagFaultStat_SRRF_sg 1 : DiagFaultStat_SRRF_FailTA DiagFaultStat_SRRF_DtcIdA DiagFaultStat_SRRF_FailTB DiagFaultStat_SRRF_EcuAdr DiagFaultStat_SRRF_DtcIdB;
SIG_GROUP_ 1521 DiagFaultStat_SRLR_sg 1 : DiagFaultStat_SRLR_FailTA DiagFaultStat_SRLR_FailTB DiagFaultStat_SRLR_EcuAdr DiagFaultStat_SRLR_DtcIdA DiagFaultStat_SRLR_DtcIdB;
SIG_GROUP_ 1524 DiagFaultStat_SRLF_sg 1 : DiagFaultStat_SRLF_DtcIdA DiagFaultStat_SRLF_FailTA DiagFaultStat_SRLF_FailTB DiagFaultStat_SRLF_DtcIdB DiagFaultStat_SRLF_EcuAdr;
SIG_GROUP_ 257 DACUTimeSync_sg 1 : DACUTimeSync_TimeDomain DACUTimeSync_SeqCnt DACUTimeSync_Time DACUTimeSync_Type DACUTimeSync_UserByte DACUTimeSync_CRC;
SIG_GROUP_ 761 DACUTimeSyncOFS_sg 1 : DACUTimeSyncOFS_TimeDomain DACUTimeSyncOFS_OfsTimeSec DACUTimeSyncOFS_TypeOFS DACUTimeSyncOFS_SeqCnt DACUTimeSyncOFS_UserByte0 DACUTimeSyncOFS_CRCOFS;
SIG_GROUP_ 760 DACUTimeSyncOFNS_sg 1 : DACUTimeSyncOFNS_CRCOFNS DACUTimeSyncOFNS_TypeOFNS DACUTimeSyncOFNS_TimeDomain DACUTimeSyncOFNS_SGW DACUTimeSyncOFNS_OfsTimeNsec DACUTimeSyncOFNS_SeqCnt;
SIG_GROUP_ 279 EgoPathPrediction_sg 1 : EgoPathPrediction_DxEnd EgoPathPrediction_ConfCoeffA1 EgoPathPrediction_ConfCoeffA0 EgoPathPrediction_ConfCoeffA2 EgoPathPrediction_Curvature EgoPathPrediction_HeadingAngle EgoPathPrediction_ConfCoeffA3 EgoPathPrediction_CurvatureRate;
SIG_GROUP_ 275 EgoMotionXYplane_sg 1 : EgoMotionXYplane_LateralAcc EgoMotionXYplane_LongAcc EgoMotionXYplane_LongSpeed EgoMotionXYplane_LongMotDirConf EgoMotionXYplane_Curvature EgoMotionXYplane_EffectiveWheelB EgoMotionXYplane_LongMotionDir EgoMotionXYplane_LongSpeedVar EgoMotionXYplane_Counter EgoMotionXYplane_LatencyEst EgoMotionXYplane_LatAccVariance EgoMotionXYplane_CRC EgoMotionXYplane_ReferencePointX EgoMotionXYplane_LateralSpeed EgoMotionXYplane_LatSpeedVar EgoMotionXYplane_YawRateComp EgoMotionXYplane_ChassisDynPitch EgoMotionXYplane_YawRateVariance EgoMotionXYplane_LongAccVariance;
